VERSION ""

NS_ :

BS_:

BU_: EBOOST_HS CGM_HS BSM_HS HCP_B_HS AVM_HS PFAF_HS LVMPC_HS DCDC_HS TRCM_HS AMP_HS VICM2_HS FICM_HS ARS_HS MCP_B_HS MCP_A_HS ICCM_OBD_HS SAS_HS ACCM_HS VLBS_HS EBCM_OBD_HS HCP_T_HS EDI_HS HPCC_HS VITM_OBD_HS VICM_HS HCP_HS APPS_HS ICCM_HS EOCM_F_HS GPCM_HS VCM_HS HMIM_HS VES_HS Dummy_HS MCP_C_HS ONSTAR_HS EPS_HS TestTool_HS MCP_HS BCP_HS ALC_HS AHL_AFL_HS SADS_HS EPB_HS FCM_HS TCCM_HS RDCM_HS PTO_HS EBCM_HS ACC_HS BCM_HS TCM_HS ECM_HS

BO_ 1373 UUDT_Resp_From_ARS_HS: 8 ARS_HS
 SG_ DgnInf_HS55D : 7|64@0+ (1,0) [0|1.84467440737096E+019] ""  CGM_HS,ONSTAR_HS,TestTool_HS

BO_ 1372 UUDT_Resp_From_ACCM_HS: 8 ACCM_HS
 SG_ DgnInf_HS55C : 7|64@0+ (1,0) [0|1.84467440737096E+019] ""  CGM_HS,ONSTAR_HS,TestTool_HS

BO_ 1371 UUDT_Resp_From_ACC_HS: 8 ACC_HS
 SG_ DgnInf_HS55B : 7|64@0+ (1,0) [0|1.84467440737096E+019] ""  CGM_HS,ONSTAR_HS,TestTool_HS

BO_ 1370 UUDT_Resp_From_Free_5A_HS: 8 Dummy_HS
 SG_ DgnInf_HS55A : 7|64@0+ (1,0) [0|1.84467440737096E+019] ""  CGM_HS,ONSTAR_HS,TestTool_HS

BO_ 1368 UUDT_Resp_From_MCP_B_HS: 8 MCP_B_HS
 SG_ DgnInf_HS558 : 7|64@0+ (1,0) [0|1.84467440737096E+019] ""  CGM_HS,ONSTAR_HS,TestTool_HS

BO_ 1367 UUDT_Resp_From_MCP_HS: 8 MCP_HS
 SG_ DgnInf_HS557 : 7|64@0+ (1,0) [0|1.84467440737096E+019] ""  CGM_HS,ONSTAR_HS,TestTool_HS

BO_ 1366 UUDT_Resp_From_TCCM_HS: 8 TCCM_HS
 SG_ DgnInf_HS556 : 7|64@0+ (1,0) [0|1.84467440737096E+019] ""  CGM_HS,ONSTAR_HS,TestTool_HS

BO_ 1362 UUDT_Resp_From_HMIM_HS: 8 HMIM_HS
 SG_ DgnInf_HS552 : 7|64@0+ (1,0) [0|1.84467440737096E+019] ""  ONSTAR_HS,TestTool_HS

BO_ 1628 USDT_Resp_From_ACCM_HS: 8 ACCM_HS
 SG_ DgnInf : 7|64@0+ (1,0) [0|1.84467440737096E+019] ""  CGM_HS,ONSTAR_HS,TestTool_HS

BO_ 1627 USDT_Resp_From_ACC_HS: 8 ACC_HS
 SG_ DgnInf : 7|64@0+ (1,0) [0|1.84467440737096E+019] ""  CGM_HS,ONSTAR_HS,TestTool_HS

BO_ 1626 USDT_Resp_From_Free_5A_HS: 8 Dummy_HS
 SG_ DgnInf : 7|64@0+ (1,0) [0|1.84467440737096E+019] ""  CGM_HS,ONSTAR_HS,TestTool_HS

BO_ 1624 USDT_Resp_From_MCP_B_HS: 8 MCP_B_HS
 SG_ DgnInf : 7|64@0+ (1,0) [0|1.84467440737096E+019] ""  CGM_HS,ONSTAR_HS,TestTool_HS

BO_ 1623 USDT_Resp_From_MCP_HS: 8 MCP_HS
 SG_ DgnInf : 7|64@0+ (1,0) [0|1.84467440737096E+019] ""  CGM_HS,ONSTAR_HS,TestTool_HS

BO_ 1622 USDT_Resp_From_TCCM_HS: 8 TCCM_HS
 SG_ DgnInf : 7|64@0+ (1,0) [0|1.84467440737096E+019] ""  CGM_HS,ONSTAR_HS,TestTool_HS

BO_ 1619 USDT_Resp_From_AMP_HS: 8 AMP_HS
 SG_ DgnInf : 7|64@0+ (1,0) [0|1.84467440737096E+019] ""  ONSTAR_HS,TestTool_HS

BO_ 1618 USDT_Resp_From_HMIM_HS: 8 HMIM_HS
 SG_ DgnInf : 7|64@0+ (1,0) [0|1.84467440737096E+019] ""  ONSTAR_HS,TestTool_HS

BO_ 1617 USDT_Resp_From_Free_51_HS: 8 Dummy_HS
 SG_ DgnInf : 7|64@0+ (1,0) [0|1.84467440737096E+019] ""  CGM_HS,ONSTAR_HS,TestTool_HS

BO_ 600 USDT_Req_to_MCP_B_HS: 8 TestTool_HS
 SG_ DgnInf : 7|64@0+ (1,0) [0|1.84467440737096E+019] ""  MCP_B_HS

BO_ 599 USDT_Req_to_MCP_HS: 8 TestTool_HS
 SG_ DgnInf : 7|64@0+ (1,0) [0|1.84467440737096E+019] ""  MCP_A_HS,MCP_HS

BO_ 598 USDT_Req_to_TCCM_HS: 8 TestTool_HS
 SG_ DgnInf : 7|64@0+ (1,0) [0|1.84467440737096E+019] ""  TCCM_HS

BO_ 595 USDT_Req_to_AMP_HS: 8 TestTool_HS
 SG_ DgnInf : 7|64@0+ (1,0) [0|1.84467440737096E+019] ""  CGM_HS,AMP_HS

BO_ 594 USDT_Req_to_HMIM_HS: 8 TestTool_HS
 SG_ DgnInf : 7|64@0+ (1,0) [0|1.84467440737096E+019] ""  CGM_HS,HMIM_HS

BO_ 593 USDT_Req_to_Free_51_HS: 8 TestTool_HS
 SG_ DgnInf : 7|64@0+ (1,0) [0|1.84467440737096E+019] ""  Dummy_HS

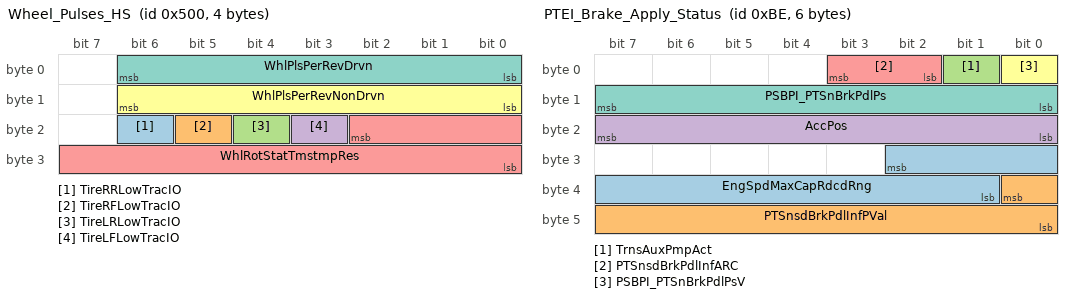
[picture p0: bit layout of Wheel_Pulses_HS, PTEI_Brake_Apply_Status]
BO_ 1280 Wheel_Pulses_HS: 4 EBCM_HS
 SG_ TireRRLowTracIO : 22|1@0+ (1,0) [0|1] ""  CGM_HS,BCM_HS
 SG_ TireRFLowTracIO : 21|1@0+ (1,0) [0|1] ""  CGM_HS,BCM_HS
 SG_ TireLRLowTracIO : 20|1@0+ (1,0) [0|1] ""  CGM_HS,BCM_HS
 SG_ TireLFLowTracIO : 19|1@0+ (1,0) [0|1] ""  CGM_HS,BCM_HS
 SG_ WhlRotStatTmstmpRes : 18|11@0+ (0.002,0) [0|4.094] "uSec"  CGM_HS,RDCM_HS,EPB_HS,HMIM_HS,TCCM_HS,BCM_HS,VES_HS,EPS_HS,EOCM_F_HS,ICCM_OBD_HS,ICCM_HS
 SG_ WhlPlsPerRevNonDrvn : 14|7@0+ (1,0) [0|127] ""  CGM_HS,ICCM_OBD_HS,ICCM_HS,HMIM_HS,TCCM_HS,EOCM_F_HS,VES_HS,EPS_HS,RDCM_HS,EPB_HS,ACC_HS,BCM_HS,SADS_HS,ONSTAR_HS
 SG_ WhlPlsPerRevDrvn : 6|7@0+ (1,0) [0|127] ""  CGM_HS,ICCM_OBD_HS,ICCM_HS,HMIM_HS,TCCM_HS,EOCM_F_HS,VES_HS,EPS_HS,RDCM_HS,ONSTAR_HS,ACC_HS,BCM_HS,EPB_HS,SADS_HS

BO_ 190 PTEI_Brake_Apply_Status: 6 ECM_HS
 SG_ EngSpdMaxCapRdcdRng : 26|10@0+ (8,0) [0|8184] "rpm"  TCM_HS
 SG_ PTSnsdBrkPdlInfPVal : 32|9@0+ (1,0) [0|511] ""  EBCM_OBD_HS,EBCM_HS,EBOOST_HS,ICCM_OBD_HS,ICCM_HS
 SG_ TrnsAuxPmpAct : 1|1@0+ (1,0) [0|1] ""  TCM_HS
 SG_ AccPos : 23|8@0+ (0.392157,0) [0|100.000035] "%"  BCP_HS,FICM_HS,TCM_HS,TCCM_HS
 SG_ PTSnsdBrkPdlInfARC : 3|2@0+ (1,0) [0|3] ""  EBCM_OBD_HS,EBCM_HS,EBOOST_HS,ICCM_OBD_HS,ICCM_HS
 SG_ PSBPI_PTSnBrkPdlPsV : 0|1@0+ (1,0) [0|1] ""  EBCM_OBD_HS,EBCM_HS,EBOOST_HS,ICCM_OBD_HS,ICCM_HS,TCM_HS
 SG_ PSBPI_PTSnBrkPdlPs : 15|8@0+ (0.392157,0) [0|100.000035] "%"  EBCM_OBD_HS,EBCM_HS,EBOOST_HS,ICCM_OBD_HS,ICCM_HS,TCM_HS

BO_ 1361 UUDT_Resp_From_Free_51_HS: 8 Dummy_HS
 SG_ DgnInf_HS551 : 7|64@0+ (1,0) [0|1.84467440737096E+019] ""  CGM_HS,ONSTAR_HS,TestTool_HS

BO_ 1345 UUDT_Resp_From_BCM_HS: 8 BCM_HS
 SG_ DgnInf_HS541 : 7|64@0+ (1,0) [0|1.84467440737096E+019] ""  CGM_HS,ONSTAR_HS,TestTool_HS

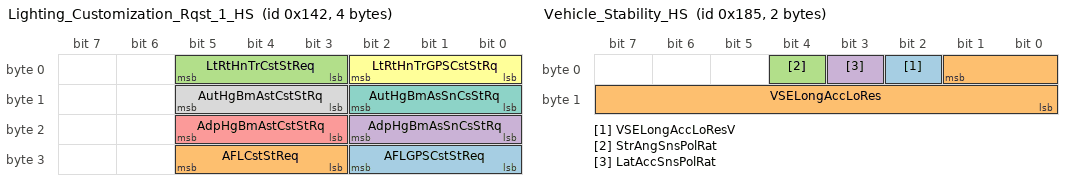
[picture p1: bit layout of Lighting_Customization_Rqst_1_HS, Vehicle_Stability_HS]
BO_ 322 Lighting_Customization_Rqst_1_HS: 4 BCM_HS
 SG_ AFLGPSCstStReq : 26|3@0+ (1,0) [0|7] ""  AHL_AFL_HS
 SG_ AFLCstStReq : 29|3@0+ (1,0) [0|7] ""  AHL_AFL_HS
 SG_ LtRtHnTrCstStReq : 5|3@0+ (1,0) [0|7] ""  AHL_AFL_HS
 SG_ AdpHgBmAsSnCsStRq : 18|3@0+ (1,0) [0|7] ""  AHL_AFL_HS
 SG_ AdpHgBmAstCstStRq : 21|3@0+ (1,0) [0|7] ""  AHL_AFL_HS
 SG_ LtRtHnTrGPSCstStRq : 2|3@0+ (1,0) [0|7] ""  AHL_AFL_HS
 SG_ AutHgBmAsSnCsStRq : 10|3@0+ (1,0) [0|7] ""  AHL_AFL_HS
 SG_ AutHgBmAstCstStRq : 13|3@0+ (1,0) [0|7] ""  AHL_AFL_HS

BO_ 1608 USDT_Resp_From_Free_48_HS: 8 Dummy_HS
 SG_ DgnInf : 7|64@0+ (1,0) [0|1.84467440737096E+019] ""  CGM_HS,ONSTAR_HS,TestTool_HS

BO_ 534 Damper_Information_HS: 2 SADS_HS
 SG_ DmpSysVehTopSpdLim : 15|8@0+ (2,0) [0|510] "km / h"  CGM_HS,BCM_HS
 SG_ SrvSuspSysIO : 0|1@0+ (1,0) [0|1] ""  CGM_HS,EDI_HS,ONSTAR_HS,BCM_HS

BO_ 309 Body_Information_2_HS: 8 BCM_HS
 SG_ StBltTgtCSRq : 23|3@0+ (1,0) [0|7] ""  CGM_HS,EBCM_OBD_HS,EBCM_HS
 SG_ ColPrSysCustReq : 15|3@0+ (1,0) [0|7] ""  FCM_HS,CGM_HS,ACC_HS,EOCM_F_HS
 SG_ SecV : 62|1@0+ (1,0) [0|1] ""  CGM_HS,ACC_HS
 SG_ Sec : 61|6@0+ (1,0) [0|63] "s"  CGM_HS,ACC_HS
 SG_ CldrYr_154 : 55|8@0+ (1,2000) [2000|2255] "year"  CGM_HS,ACC_HS
 SG_ CldrYr : 47|8@0+ (1,2000) [2000|2255] "year"  CGM_HS,EBCM_OBD_HS,EBCM_HS,ACC_HS
 SG_ CldrMth_154 : 39|4@0+ (1,0) [0|15] ""  CGM_HS,ACC_HS
 SG_ CldrMth : 35|4@0+ (1,0) [0|15] ""  EBCM_OBD_HS,EBCM_HS,CGM_HS,ACC_HS
 SG_ CldrDay_154 : 30|5@0+ (1,0) [0|31] "days"  CGM_HS,ACC_HS
 SG_ CldrDay : 20|5@0+ (1,0) [0|31] "days"  EBCM_OBD_HS,EBCM_HS,CGM_HS,ACC_HS
 SG_ AutoHiBmVDA : 25|1@0+ (1,0) [0|1] ""  CGM_HS,AHL_AFL_HS
 SG_ CtLghtDet : 24|1@0+ (1,0) [0|1] ""  CGM_HS,AHL_AFL_HS
 SG_ RrClosVDA : 11|1@0+ (1,0) [0|1] ""  CGM_HS,ICCM_OBD_HS,ICCM_HS,ALC_HS,SADS_HS
 SG_ TCSysDisSwAtv : 4|1@0+ (1,0) [0|1] ""  CGM_HS,EBCM_OBD_HS,EBCM_HS
 SG_ VehMovState : 2|3@0+ (1,0) [0|7] ""  CGM_HS,HMIM_HS,EBCM_OBD_HS,EBCM_HS,RDCM_HS,FCM_HS,SADS_HS,AHL_AFL_HS
 SG_ TCSysDisSwAtvV : 3|1@0+ (1,0) [0|1] ""  CGM_HS,EBCM_OBD_HS,EBCM_HS
 SG_ HillDesCtrlMdSwActV : 10|1@0+ (1,0) [0|1] ""  CGM_HS,EBCM_OBD_HS,EBCM_HS
 SG_ WSWshSwAtv : 5|1@0+ (1,0) [0|1] ""  CGM_HS,EOCM_F_HS,FCM_HS,ACC_HS
 SG_ HillDesCtrlMdSwAct : 9|1@0+ (1,0) [0|1] ""  CGM_HS,EBCM_OBD_HS,EBCM_HS
 SG_ RrClosAjarSwAct : 12|1@0+ (1,0) [0|1] ""  CGM_HS,ICCM_OBD_HS,ICCM_HS,ALC_HS,SADS_HS
 SG_ WSWprAct : 6|1@0+ (1,0) [0|1] ""  CGM_HS,FCM_HS,EOCM_F_HS,EBCM_OBD_HS,EBCM_HS,ACC_HS,AHL_AFL_HS

BO_ 389 Vehicle_Stability_HS: 2 EBCM_HS
 SG_ VSELongAccLoResV : 2|1@0+ (1,0) [0|1] ""  CGM_HS,EDI_HS,FCM_HS,TCM_HS,ICCM_OBD_HS,ICCM_HS,ALC_HS,SADS_HS,VES_HS,EPB_HS,RDCM_HS,BCM_HS,ACC_HS
 SG_ VSELongAccLoRes : 1|10@0- (0.03,0) [-15.36|15.33] "m/s^2"  CGM_HS,EDI_HS,FCM_HS,TCM_HS,ICCM_OBD_HS,ICCM_HS,ALC_HS,SADS_HS,VES_HS,EPB_HS,RDCM_HS,BCM_HS,ACC_HS
 SG_ StrAngSnsPolRat : 4|1@0+ (1,0) [0|1] ""  CGM_HS,EPS_HS
 SG_ LatAccSnsPolRat : 3|1@0+ (1,0) [0|1] ""  CGM_HS,EPS_HS

BO_ 1922 DTC_Triggered_782: 7 Dummy_HS
 SG_ DTCI_WrnIndRqdSt_782 : 47|1@0+ (1,0) [0|1] ""  HMIM_HS,ONSTAR_HS
 SG_ DTCIUnused7_782 : 1|1@0+ (1,0) [0|1] ""  HMIM_HS,ONSTAR_HS
 SG_ DTCIUnused6_782 : 2|1@0+ (1,0) [0|1] ""  HMIM_HS,ONSTAR_HS
 SG_ DTCIUnused5_782 : 3|1@0+ (1,0) [0|1] ""  HMIM_HS,ONSTAR_HS
 SG_ DTCIUnused4_782 : 4|1@0+ (1,0) [0|1] ""  HMIM_HS,ONSTAR_HS
 SG_ DTCIUnused3_782 : 5|1@0+ (1,0) [0|1] ""  HMIM_HS,ONSTAR_HS
 SG_ DTCIUnused2_782 : 6|1@0+ (1,0) [0|1] ""  HMIM_HS,ONSTAR_HS
 SG_ DTCIUnused1_782 : 7|1@0+ (1,0) [0|1] ""  HMIM_HS,ONSTAR_HS
 SG_ DTCI_TstNPsdPwrUpSt_782 : 45|1@0+ (1,0) [0|1] ""  HMIM_HS,ONSTAR_HS
 SG_ DTCI_TstNPsdCdClrdSt_782 : 42|1@0+ (1,0) [0|1] ""  HMIM_HS,ONSTAR_HS
 SG_ DTCI_TstFldPwrUpSt_782 : 46|1@0+ (1,0) [0|1] ""  HMIM_HS,ONSTAR_HS
 SG_ DTCI_TstFldCdClrdStat_782 : 43|1@0+ (1,0) [0|1] ""  HMIM_HS,ONSTAR_HS
 SG_ DTCI_HistStat_782 : 44|1@0+ (1,0) [0|1] ""  HMIM_HS,ONSTAR_HS
 SG_ DTCI_DTCTriggered_782 : 0|1@0+ (1,0) [0|1] ""  HMIM_HS,ONSTAR_HS
 SG_ DTCI_DTCSource_782 : 15|8@0+ (1,0) [0|255] ""  HMIM_HS,ONSTAR_HS
 SG_ DTCI_DTCNumber_782 : 23|16@0+ (1,0) [0|65535] ""  HMIM_HS,ONSTAR_HS
 SG_ DTCI_DTCFaultType_782 : 55|8@0+ (1,0) [0|255] ""  HMIM_HS,ONSTAR_HS
 SG_ DTCI_DTCFailType_782 : 39|8@0+ (1,0) [0|255] ""  HMIM_HS,ONSTAR_HS
 SG_ DTCI_CurrentStatus_782 : 41|1@0+ (1,0) [0|1] ""  HMIM_HS,ONSTAR_HS
 SG_ DTCI_CodeSupported_782 : 40|1@0+ (1,0) [0|1] ""  HMIM_HS,ONSTAR_HS

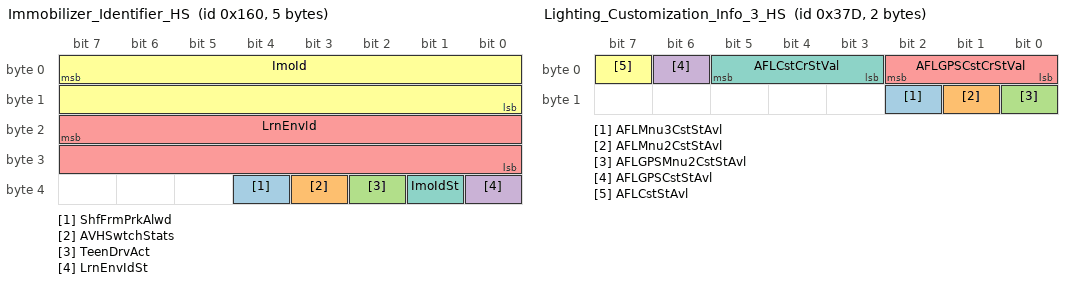
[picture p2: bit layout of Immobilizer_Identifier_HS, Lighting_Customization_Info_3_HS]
BO_ 352 Immobilizer_Identifier_HS: 5 BCM_HS
 SG_ ShfFrmPrkAlwd : 36|1@0+ (1,0) [0|1] ""  ICCM_HS
 SG_ AVHSwtchStats : 35|1@0+ (1,0) [0|1] ""  EBCM_OBD_HS,EBCM_HS
 SG_ TeenDrvAct : 34|1@0+ (1,0) [0|1] ""  CGM_HS,ALC_HS,EBCM_OBD_HS,EBCM_HS,AHL_AFL_HS,ACC_HS
 SG_ LrnEnvIdSt : 32|1@0+ (1,0) [0|1] ""  CGM_HS,VLBS_HS,ONSTAR_HS,EBCM_OBD_HS,EBCM_HS
 SG_ LrnEnvId : 23|16@0+ (1,0) [0|65535] ""  CGM_HS,VLBS_HS,ONSTAR_HS,EBCM_OBD_HS,EBCM_HS
 SG_ ImoId : 7|16@0+ (1,0) [0|65535] ""  CGM_HS,VLBS_HS,ONSTAR_HS,EBCM_OBD_HS,EBCM_HS
 SG_ ImoIdSt : 33|1@0+ (1,0) [0|1] ""  CGM_HS,VLBS_HS,ONSTAR_HS,EBCM_OBD_HS,EBCM_HS

BO_ 562 Driving_Mode_Control_HS: 8 EBCM_HS
 SG_ SndPerfMdCsStAvl : 63|1@0+ (1,0) [0|1] ""  CGM_HS,BCM_HS
 SG_ SndPerfMdCsCrStVal : 62|3@0+ (1,0) [0|7] ""  CGM_HS,BCM_HS
 SG_ DispPerfMdCsStAvl : 59|1@0+ (1,0) [0|1] ""  CGM_HS,BCM_HS
 SG_ DispPerfMdCsCrStVal : 58|3@0+ (1,0) [0|7] ""  CGM_HS,BCM_HS
 SG_ DrvlneMntsPerfMdRq : 50|3@0+ (1,0) [0|7] ""  CGM_HS,Dummy_HS,ICCM_OBD_HS,ICCM_HS
 SG_ RideCntrlPerfMdRq : 18|3@0+ (1,0) [0|7] ""  CGM_HS,EDI_HS,SADS_HS
 SG_ StgSysPerfMdRq : 29|3@0+ (1,0) [0|7] ""  EOCM_F_HS,FCM_HS,CGM_HS,EDI_HS,VES_HS,EPS_HS
 SG_ DiffPerfMdRq : 26|3@0+ (1,0) [0|7] ""  CGM_HS,ICCM_OBD_HS,ICCM_HS
 SG_ SndEnhcmtPerfMdRq : 13|3@0+ (1,0) [0|7] ""  CGM_HS,BCM_HS,AMP_HS
 SG_ DsplyPerfMdRq : 10|3@0+ (1,0) [0|7] ""  CGM_HS,EDI_HS,BCM_HS
 SG_ ExhstPerfMdRq : 5|3@0+ (1,0) [0|7] ""  CGM_HS,ICCM_OBD_HS,ICCM_HS
 SG_ HillDscntCntlSysStat : 55|3@0+ (1,0) [0|7] ""  CGM_HS,BCM_HS
 SG_ SusCustStngAvlbl : 23|1@0+ (1,0) [0|1] ""  CGM_HS,ONSTAR_HS,BCM_HS
 SG_ SusCustCurrStngVal : 45|3@0+ (1,0) [0|7] ""  CGM_HS,ONSTAR_HS,BCM_HS
 SG_ StrCustStngAvlbl : 7|1@0+ (1,0) [0|1] ""  CGM_HS,ONSTAR_HS,BCM_HS
 SG_ StrCustCurrStngVal : 42|3@0+ (1,0) [0|7] ""  CGM_HS,ONSTAR_HS,BCM_HS
 SG_ DrvlnCustStngAvlbl : 6|1@0+ (1,0) [0|1] ""  CGM_HS,ONSTAR_HS,BCM_HS
 SG_ DrvMdCntrlState : 39|8@0+ (1,0) [0|255] ""  CGM_HS,EOCM_F_HS,FCM_HS,VES_HS,EPS_HS,RDCM_HS,SADS_HS
 SG_ AWDPerfMdRq : 2|3@0+ (1,0) [0|7] ""  CGM_HS,RDCM_HS,TCCM_HS
 SG_ DrvlnCustCurrStngVal : 22|3@0+ (1,0) [0|7] ""  CGM_HS,ONSTAR_HS,BCM_HS

BO_ 893 Lighting_Customization_Info_3_HS: 2 AHL_AFL_HS
 SG_ AFLMnu3CstStAvl : 10|1@0+ (1,0) [0|1] ""  BCM_HS
 SG_ AFLMnu2CstStAvl : 9|1@0+ (1,0) [0|1] ""  BCM_HS
 SG_ AFLGPSMnu2CstStAvl : 8|1@0+ (1,0) [0|1] ""  BCM_HS
 SG_ AFLGPSCstStAvl : 6|1@0+ (1,0) [0|1] ""  BCM_HS
 SG_ AFLGPSCstCrStVal : 2|3@0+ (1,0) [0|7] ""  BCM_HS
 SG_ AFLCstStAvl : 7|1@0+ (1,0) [0|1] ""  BCM_HS
 SG_ AFLCstCrStVal : 5|3@0+ (1,0) [0|7] ""  BCM_HS

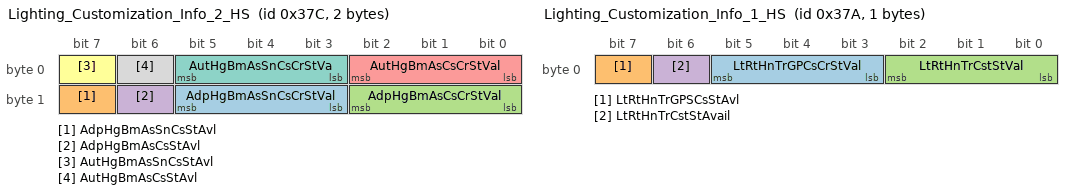
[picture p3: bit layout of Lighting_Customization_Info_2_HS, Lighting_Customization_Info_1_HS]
BO_ 892 Lighting_Customization_Info_2_HS: 2 AHL_AFL_HS
 SG_ AdpHgBmAsSnCsCrStVal : 13|3@0+ (1,0) [0|7] ""  BCM_HS
 SG_ AdpHgBmAsSnCsStAvl : 15|1@0+ (1,0) [0|1] ""  BCM_HS
 SG_ AdpHgBmAsCsCrStVal : 10|3@0+ (1,0) [0|7] ""  BCM_HS
 SG_ AdpHgBmAsCsStAvl : 14|1@0+ (1,0) [0|1] ""  BCM_HS
 SG_ AutHgBmAsCsCrStVal : 2|3@0+ (1,0) [0|7] ""  BCM_HS
 SG_ AutHgBmAsSnCsStAvl : 7|1@0+ (1,0) [0|1] ""  BCM_HS
 SG_ AutHgBmAsSnCsCrStVa : 5|3@0+ (1,0) [0|7] ""  BCM_HS
 SG_ AutHgBmAsCsStAvl : 6|1@0+ (1,0) [0|1] ""  BCM_HS

BO_ 386 Environment_Id_Resp_4_HS: 8 EBCM_HS
 SG_ AHAct : 31|1@0+ (1,0) [0|1] ""  BCM_HS
 SG_ AHEnbld : 30|1@0+ (1,0) [0|1] ""  BCM_HS
 SG_ ShfToPrkBfExtngIO : 29|1@0+ (1,0) [0|1] ""  BCM_HS
 SG_ AHServcIO : 28|1@0+ (1,0) [0|1] ""  BCM_HS
 SG_ AHAppBrkPedlIO : 27|1@0+ (1,0) [0|1] ""  BCM_HS
 SG_ AHDisbldStbltIO : 26|1@0+ (1,0) [0|1] ""  BCM_HS
 SG_ AHDisbldDrOpnIO : 25|1@0+ (1,0) [0|1] ""  BCM_HS
 SG_ PMVSS_Disps : 58|3@0+ (1,0) [0|7] ""  BCM_HS
 SG_ PMVSS_Exhst : 61|3@0+ (1,0) [0|7] ""  BCM_HS
 SG_ PMVSS_PsngrSeat : 48|3@0+ (1,0) [0|7] ""  BCM_HS
 SG_ PMVSS_DrvrSeat : 51|3@0+ (1,0) [0|7] ""  BCM_HS
 SG_ PMVSS_AdptCrsCnt : 54|3@0+ (1,0) [0|7] ""  BCM_HS
 SG_ PMVSS_Drvln : 41|3@0+ (1,0) [0|7] ""  BCM_HS
 SG_ PMVSS_Susp : 44|3@0+ (1,0) [0|7] ""  BCM_HS
 SG_ PMVSS_Strng : 47|3@0+ (1,0) [0|7] ""  BCM_HS
 SG_ PMVSS_Trans : 34|3@0+ (1,0) [0|7] ""  BCM_HS
 SG_ PMVSS_Eng : 37|3@0+ (1,0) [0|7] ""  BCM_HS
 SG_ PMVSS_Snd : 24|3@0+ (1,0) [0|7] ""  BCM_HS
 SG_ AdptCruzCtrlStg : 20|3@0+ (1,0) [0|7] ""  EOCM_F_HS,ACC_HS
 SG_ EnvIdRsp4 : 7|16@0+ (1,0) [0|65535] ""  BCM_HS
 SG_ EnvIdRspSt4 : 17|2@0+ (1,0) [0|3] ""  BCM_HS

BO_ 597 USDT_Req_to_TRCM_HS: 8 TestTool_HS
 SG_ DgnInf : 7|64@0+ (1,0) [0|1.84467440737096E+019] ""  TRCM_HS

BO_ 1621 USDT_Resp_From_TRCM_HS: 8 TRCM_HS
 SG_ DgnInf : 7|64@0+ (1,0) [0|1.84467440737096E+019] ""  CGM_HS,ONSTAR_HS,TestTool_HS

BO_ 532 Brake_Pedal_Driver_Status_HS: 6 EBCM_HS
 SG_ RedntVSEActARC : 38|2@0+ (1,0) [0|3] ""  CGM_HS,EPS_HS,ICCM_OBD_HS,ICCM_HS
 SG_ RedntVSEAct : 39|1@0+ (1,0) [0|1] ""  CGM_HS,EPS_HS,ICCM_OBD_HS,ICCM_HS
 SG_ AutoBrkngActARC : 22|2@0+ (1,0) [0|3] ""  CGM_HS,ICCM_OBD_HS,ICCM_HS
 SG_ HilRlbkCtrlActIO : 19|1@0+ (1,0) [0|1] ""  CGM_HS,BCM_HS
 SG_ VehHldDrvrDsblActvFlg : 36|1@0+ (1,0) [0|1] ""  CGM_HS,EPB_HS
 SG_ ABSAutnmsBrkReqPVal : 41|2@0+ (1,0) [0|3] ""  CGM_HS,EPB_HS
 SG_ AutoBrkngAvlbl : 17|1@0+ (1,0) [0|1] ""  FCM_HS,CGM_HS,EPS_HS,EOCM_F_HS,EPB_HS
 SG_ ABSAutnmsBrkReqARC : 35|2@0+ (1,0) [0|3] ""  CGM_HS,EPB_HS
 SG_ ABSAutnmsBrkReq : 33|1@0+ (1,0) [0|1] ""  CGM_HS,EPB_HS
 SG_ ABSActvProtPVal : 43|2@0+ (1,0) [0|3] ""  CGM_HS,EPS_HS,EOCM_F_HS,ICCM_OBD_HS,ICCM_HS
 SG_ ABSActvProtARC : 45|2@0+ (1,0) [0|3] ""  CGM_HS,EPS_HS,EOCM_F_HS,ICCM_OBD_HS,ICCM_HS
 SG_ HlStrAssActIO : 20|1@0+ (1,0) [0|1] ""  CGM_HS,BCM_HS
 SG_ ABSActvProt : 46|1@0+ (1,0) [0|1] ""  CGM_HS,EPS_HS,EOCM_F_HS,ICCM_OBD_HS,ICCM_HS
 SG_ BrkSysAutBrkFld : 5|1@0+ (1,0) [0|1] ""  FCM_HS,CGM_HS,EPB_HS,BCM_HS,ACC_HS
 SG_ IntBrkAssPreFilReq : 4|1@0+ (1,0) [0|1] "N/A"  CGM_HS,BCM_HS
 SG_ BrkSysMalFuncIndOn : 3|1@0+ (1,0) [0|1] ""  CGM_HS,BCM_HS
 SG_ BrkPdDrvAPrsStaPVal : 16|9@0+ (1,0) [0|511] ""  CGM_HS,FCM_HS,ACC_HS,EOCM_F_HS,ICCM_OBD_HS,ICCM_HS,EPB_HS,SADS_HS
 SG_ BPDAPS_BkPDrvApPV : 8|1@0+ (1,0) [0|1] ""  CGM_HS,FCM_HS,EOCM_F_HS,ICCM_OBD_HS,ICCM_HS,BCM_HS,ACC_HS,SADS_HS,EPB_HS
 SG_ BPDAPS_BkPDrvApP : 0|8@0+ (75,0) [0|19125] "kPa"  CGM_HS,FCM_HS,EOCM_F_HS,ICCM_OBD_HS,ICCM_HS,BCM_HS,ACC_HS,SADS_HS,EPB_HS
 SG_ BrkPdDrvAppPrsAlRC : 2|2@0+ (1,0) [0|3] ""  CGM_HS,FCM_HS,ACC_HS,EOCM_F_HS,ICCM_OBD_HS,ICCM_HS,SADS_HS,EPB_HS
 SG_ BrkFldLvlLwV : 7|1@0+ (1,0) [0|1] ""  CGM_HS,BCM_HS
 SG_ AutoBrkngAct : 18|1@0+ (1,0) [0|1] ""  CGM_HS,ICCM_OBD_HS,ICCM_HS,EPB_HS,ACC_HS
 SG_ BrkFldLvlLw : 6|1@0+ (1,0) [0|1] ""  CGM_HS,BCM_HS

BO_ 890 Lighting_Customization_Info_1_HS: 1 AHL_AFL_HS
 SG_ LtRtHnTrGPCsCrStVal : 5|3@0+ (1,0) [0|7] ""  BCM_HS
 SG_ LtRtHnTrGPSCsStAvl : 7|1@0+ (1,0) [0|1] ""  BCM_HS
 SG_ LtRtHnTrCstStVal : 2|3@0+ (1,0) [0|7] ""  BCM_HS
 SG_ LtRtHnTrCstStAvail : 6|1@0+ (1,0) [0|1] ""  BCM_HS

BO_ 592 USDT_Req_to_AVM_HS: 8 TestTool_HS
 SG_ DgnInf : 7|64@0+ (1,0) [0|1.84467440737096E+019] ""  AVM_HS

BO_ 1365 UUDT_Resp_From_TRCM_HS: 8 TRCM_HS
 SG_ DgnInf_HS555 : 7|64@0+ (1,0) [0|1.84467440737096E+019] ""  CGM_HS,ONSTAR_HS,TestTool_HS

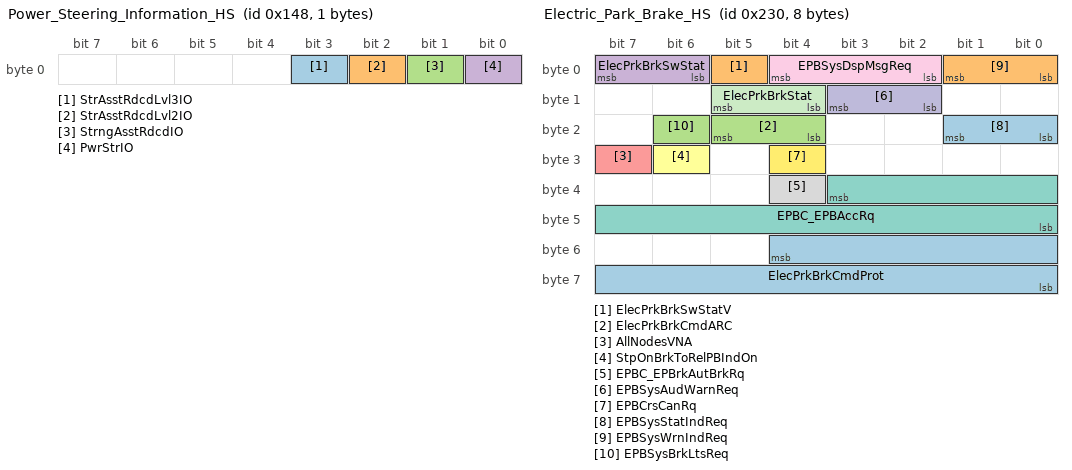
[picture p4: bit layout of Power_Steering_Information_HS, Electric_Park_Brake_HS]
BO_ 328 Power_Steering_Information_HS: 1 EPS_HS
 SG_ StrAsstRdcdLvl3IO : 3|1@0+ (1,0) [0|1] ""  BCM_HS,CGM_HS
 SG_ StrAsstRdcdLvl2IO : 2|1@0+ (1,0) [0|1] ""  BCM_HS,CGM_HS
 SG_ StrngAsstRdcdIO : 1|1@0+ (1,0) [0|1] ""  CGM_HS,BCM_HS
 SG_ PwrStrIO : 0|1@0+ (1,0) [0|1] ""  CGM_HS,BCM_HS,EPB_HS

BO_ 560 Electric_Park_Brake_HS: 8 EPB_HS
 SG_ ElecPrkBrkCmdProt : 52|13@0+ (1,0) [0|8191] ""  CGM_HS,EBCM_OBD_HS,EBCM_HS
 SG_ ElecPrkBrkSwStatV : 5|1@0+ (1,0) [0|1] ""  CGM_HS,EBCM_OBD_HS,EBCM_HS
 SG_ ElecPrkBrkCmdARC : 21|2@0+ (1,0) [0|3] ""  CGM_HS,EBCM_OBD_HS,EBCM_HS
 SG_ ElecPrkBrkSwStat : 7|2@0+ (1,0) [0|3] ""  CGM_HS,EBCM_OBD_HS,EBCM_HS
 SG_ AllNodesVNA : 31|1@0+ (1,0) [0|1] ""  CGM_HS,BCM_HS
 SG_ StpOnBrkToRelPBIndOn : 30|1@0+ (1,0) [0|1] ""  CGM_HS,BCM_HS
 SG_ EPBC_EPBAccRq : 35|12@0- (0.01,0) [-20.48|20.47] "m/s^2"  CGM_HS,EBCM_OBD_HS,EBCM_HS
 SG_ EPBC_EPBrkAutBrkRq : 36|1@0+ (1,0) [0|1] ""  CGM_HS,EBCM_OBD_HS,EBCM_HS
 SG_ EPBSysDspMsgReq : 4|3@0+ (1,0) [0|7] ""  CGM_HS,BCM_HS
 SG_ EPBSysAudWarnReq : 11|2@0+ (1,0) [0|3] ""  CGM_HS,BCM_HS
 SG_ ElecPrkBrkStat : 13|2@0+ (1,0) [0|3] ""  CGM_HS,ICCM_OBD_HS,ICCM_HS,ACC_HS,EOCM_F_HS,BCM_HS,EBCM_OBD_HS,EBCM_HS,RDCM_HS
 SG_ EPBCrsCanRq : 28|1@0+ (1,0) [0|1] ""  CGM_HS,ACC_HS,EOCM_F_HS,EBCM_OBD_HS,EBCM_HS,BCM_HS
 SG_ EPBSysStatIndReq : 17|2@0+ (1,0) [0|3] ""  CGM_HS,BCM_HS
 SG_ EPBSysWrnIndReq : 1|2@0+ (1,0) [0|3] ""  CGM_HS,BCM_HS
 SG_ EPBSysBrkLtsReq : 22|1@0+ (1,0) [0|1] ""  CGM_HS,BCM_HS

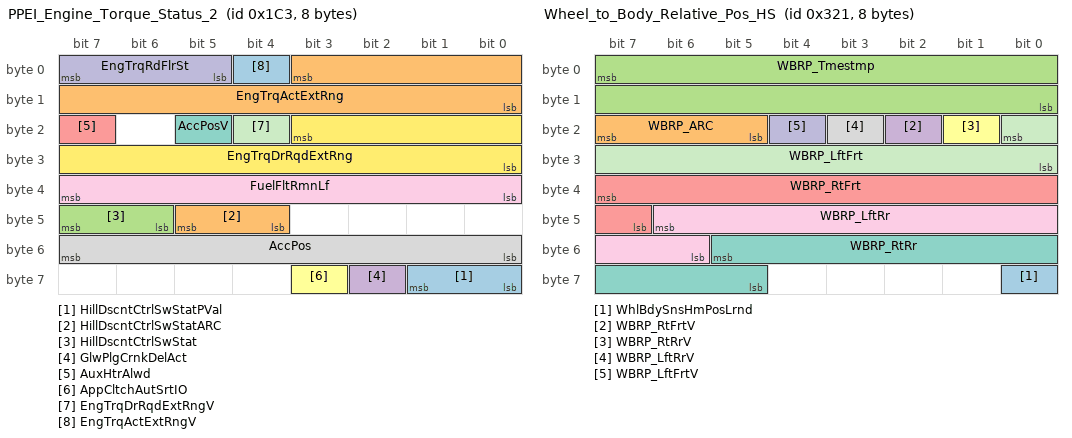
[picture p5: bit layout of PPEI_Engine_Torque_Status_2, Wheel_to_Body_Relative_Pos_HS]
BO_ 451 PPEI_Engine_Torque_Status_2: 8 ECM_HS
 SG_ HillDscntCtrlSwStatPVal : 57|2@0+ (1,0) [0|3] ""  CGM_HS,EBCM_OBD_HS,EBCM_HS
 SG_ HillDscntCtrlSwStatARC : 45|2@0+ (1,0) [0|3] ""  CGM_HS,EBCM_OBD_HS,EBCM_HS
 SG_ HillDscntCtrlSwStat : 47|2@0+ (1,0) [0|3] ""  CGM_HS,EBCM_OBD_HS,EBCM_HS
 SG_ GlwPlgCrnkDelAct : 58|1@0+ (1,0) [0|1] ""  CGM_HS,BCM_HS
 SG_ AuxHtrAlwd : 23|1@0+ (1,0) [0|1] ""  CGM_HS,BCM_HS
 SG_ AppCltchAutSrtIO : 59|1@0+ (1,0) [0|1] ""  CGM_HS,BCM_HS
 SG_ AccPosV : 21|1@0+ (1,0) [0|1] ""  RDCM_HS,CGM_HS,ICCM_OBD_HS,ICCM_HS,ACC_HS,EOCM_F_HS,TCCM_HS,EBCM_OBD_HS,EBCM_HS
 SG_ AccPos : 55|8@0+ (0.392157,0) [0|100.000035] "%"  RDCM_HS,CGM_HS,ICCM_OBD_HS,ICCM_HS,EOCM_F_HS,BSM_HS,VICM_HS,ACC_HS,TCCM_HS,EBCM_OBD_HS,EBCM_HS
 SG_ FuelFltRmnLf : 39|8@0+ (0.392157,0) [0|100.000035] "%"  CGM_HS,ONSTAR_HS,BCM_HS
 SG_ EngTrqRdFlrSt : 7|3@0+ (1,0) [0|7] ""  CGM_HS,EBCM_OBD_HS,EBCM_HS
 SG_ EngTrqDrRqdExtRngV : 20|1@0+ (1,0) [0|1] ""  CGM_HS,BCM_HS,ACC_HS,LVMPC_HS,RDCM_HS,EBCM_OBD_HS,EBCM_HS,SADS_HS
 SG_ EngTrqDrRqdExtRng : 19|12@0+ (0.5,-848) [-848|1199.5] "Nm"  CGM_HS,BCM_HS,LVMPC_HS,ACC_HS,RDCM_HS,EBCM_OBD_HS,EBCM_HS,SADS_HS
 SG_ EngTrqActExtRngV : 4|1@0+ (1,0) [0|1] ""  CGM_HS,AVM_HS,PTO_HS,ICCM_OBD_HS,ICCM_HS,AMP_HS,TCCM_HS,VES_HS,ACC_HS,EPS_HS,EPB_HS,BCM_HS,RDCM_HS,EBCM_OBD_HS,EBCM_HS,SADS_HS
 SG_ EngTrqActExtRng : 3|12@0+ (0.5,-848) [-848|1199.5] "Nm"  CGM_HS,AVM_HS,ICCM_OBD_HS,ICCM_HS,PTO_HS,AMP_HS,TCCM_HS,VES_HS,ACC_HS,EPS_HS,EPB_HS,BCM_HS,RDCM_HS,EBCM_OBD_HS,EBCM_HS,SADS_HS

BO_ 801 Wheel_to_Body_Relative_Pos_HS: 8 SADS_HS
 SG_ WhlBdySnsHmPosLrnd : 56|1@0+ (1,0) [0|1] ""  CGM_HS,EDI_HS,ICCM_OBD_HS,ICCM_HS,ALC_HS,SADS_HS,FCM_HS,AHL_AFL_HS,EBCM_OBD_HS,EBCM_HS
 SG_ WBRP_ARC : 23|3@0+ (1,0) [0|7] "counts"  CGM_HS,EDI_HS,ICCM_OBD_HS,ICCM_HS,ALC_HS,SADS_HS,FCM_HS,EBCM_OBD_HS,EBCM_HS,AHL_AFL_HS
 SG_ WBRP_Tmestmp : 7|16@0+ (1,0) [0|65535] "micro sec"  CGM_HS,EDI_HS,ICCM_OBD_HS,ICCM_HS,ALC_HS,SADS_HS,FCM_HS,EBCM_OBD_HS,EBCM_HS,AHL_AFL_HS
 SG_ WBRP_RtFrtV : 18|1@0+ (1,0) [0|1] ""  CGM_HS,EDI_HS,ICCM_OBD_HS,ICCM_HS,ALC_HS,SADS_HS,FCM_HS,EBCM_OBD_HS,EBCM_HS,AHL_AFL_HS
 SG_ WBRP_RtFrt : 39|9@0- (1,0) [-256|255] "mm"  CGM_HS,EDI_HS,ICCM_OBD_HS,ICCM_HS,ALC_HS,SADS_HS,FCM_HS,EBCM_OBD_HS,EBCM_HS,AHL_AFL_HS
 SG_ WBRP_RtRrV : 17|1@0+ (1,0) [0|1] ""  CGM_HS,EDI_HS,ICCM_OBD_HS,ICCM_HS,ALC_HS,SADS_HS,FCM_HS,EBCM_OBD_HS,EBCM_HS,AHL_AFL_HS
 SG_ WBRP_RtRr : 53|9@0- (1,0) [-256|255] "mm"  CGM_HS,EDI_HS,ICCM_OBD_HS,ICCM_HS,ALC_HS,SADS_HS,FCM_HS,EBCM_OBD_HS,EBCM_HS,AHL_AFL_HS
 SG_ WBRP_LftRrV : 19|1@0+ (1,0) [0|1] ""  CGM_HS,EDI_HS,ICCM_OBD_HS,ICCM_HS,ALC_HS,SADS_HS,FCM_HS,EBCM_OBD_HS,EBCM_HS,AHL_AFL_HS
 SG_ WBRP_LftRr : 46|9@0- (1,0) [-256|255] "mm"  CGM_HS,EDI_HS,ICCM_OBD_HS,ICCM_HS,ALC_HS,SADS_HS,FCM_HS,EBCM_OBD_HS,EBCM_HS,AHL_AFL_HS
 SG_ WBRP_LftFrtV : 20|1@0+ (1,0) [0|1] ""  CGM_HS,EDI_HS,ICCM_OBD_HS,ICCM_HS,ALC_HS,SADS_HS,FCM_HS,EBCM_OBD_HS,EBCM_HS,AHL_AFL_HS
 SG_ WBRP_LftFrt : 16|9@0- (1,0) [-256|255] "mm"  CGM_HS,EDI_HS,ICCM_OBD_HS,ICCM_HS,ALC_HS,SADS_HS,FCM_HS,EBCM_OBD_HS,EBCM_HS,AHL_AFL_HS

BO_ 320 Exterior_Lighting_HS: 3 BCM_HS
 SG_ Ky_IdDevPrgmAuthReq : 14|1@0+ (1,0) [0|1] ""  CGM_HS,EPS_HS
 SG_ ClmnLckStatV : 15|1@0+ (1,0) [0|1] ""  CGM_HS,EPS_HS
 SG_ ClmnLckStat : 21|2@0+ (1,0) [0|3] ""  CGM_HS,EPS_HS
 SG_ AutoBmSlctAllwd : 13|1@0+ (1,0) [0|1] ""  CGM_HS,AHL_AFL_HS
 SG_ BrkLtsAtv : 6|1@0+ (1,0) [0|1] ""  CGM_HS,AHL_AFL_HS,EOCM_F_HS,ACC_HS
 SG_ TrnSwAct : 19|2@0+ (1,0) [0|3] ""  CGM_HS,EBCM_OBD_HS,EBCM_HS,ECM_HS,EOCM_F_HS,AHL_AFL_HS
 SG_ RrFogLmpsAct : 8|1@0+ (1,0) [0|1] ""  CGM_HS,AHL_AFL_HS
 SG_ OtsdAmbtLtLvlStatV : 2|1@0+ (1,0) [0|1] ""  CGM_HS,FCM_HS,EOCM_F_HS,AHL_AFL_HS
 SG_ OtsdAmbtLtLvlStat : 17|2@0+ (1,0) [0|3] ""  CGM_HS,FCM_HS,EOCM_F_HS,AHL_AFL_HS
 SG_ MainLghtSw : 12|2@0+ (1,0) [0|3] "N/A"  CGM_HS,FCM_HS,AHL_AFL_HS
 SG_ LowBmAct : 1|1@0+ (1,0) [0|1] ""  CGM_HS,FCM_HS,EOCM_F_HS,AHL_AFL_HS
 SG_ HighBmAct : 7|1@0+ (1,0) [0|1] ""  CGM_HS,FCM_HS,EOCM_F_HS,AHL_AFL_HS
 SG_ HdlmpBmSelectStat : 10|2@0+ (1,0) [0|3] ""  CGM_HS,FCM_HS,AHL_AFL_HS
 SG_ FlToPsSwAtv : 5|1@0+ (1,0) [0|1] ""  CGM_HS,FCM_HS,AHL_AFL_HS
 SG_ AdvFrntLghtSysEnbld : 3|1@0+ (1,0) [0|1] ""  CGM_HS,AHL_AFL_HS
 SG_ FrFogLmpsAct : 0|1@0+ (1,0) [0|1] ""  CGM_HS,FCM_HS,AHL_AFL_HS
 SG_ AutLghtCtrl : 4|1@0+ (1,0) [0|1] "N/A"  CGM_HS,AHL_AFL_HS

BO_ 957 ETEI_Glow_Plug_Diagnostic_Status: 8 GPCM_HS
 SG_ RdctHtrCStat : 26|1@0+ (1,0) [0|1] ""  ECM_HS
 SG_ RdctHtrBStat : 27|1@0+ (1,0) [0|1] ""  ECM_HS
 SG_ RdctHtrAStat : 28|1@0+ (1,0) [0|1] ""  ECM_HS
 SG_ GPCMDS2_DTCStatus : 58|3@0+ (1,0) [0|7] ""  ECM_HS
 SG_ GPCMDS2_DTCIndex : 63|5@0+ (1,0) [0|31] ""  ECM_HS
 SG_ IntAirHtrPwrConsmp : 55|8@0+ (20,0) [0|5100] "W"  ECM_HS
 SG_ IntAirHtrPwrConsmpV : 29|1@0+ (1,0) [0|1] ""  ECM_HS
 SG_ DslGlwPlgMdOvTmOD : 25|1@0+ (1,0) [0|1] ""  ECM_HS
 SG_ IQAI_DataByte : 47|8@0+ (1,0) [0|255] ""  ECM_HS
 SG_ IQAI_DataSeqNmbr : 35|4@0+ (1,0) [0|15] ""  ECM_HS
 SG_ IQAI_InjIdInd : 38|3@0+ (1,0) [0|7] ""  ECM_HS
 SG_ IQAI_DataStat : 39|1@0+ (1,0) [0|1] ""  ECM_HS
 SG_ IntAirHtrTempSensVoltV : 30|1@0+ (1,0) [0|1] ""  ECM_HS
 SG_ IntAirHtrTempSensVolt : 23|8@0+ (0.0196078,0) [0|4.999989] "volts"  ECM_HS
 SG_ IntAirHtrSupVoltV : 31|1@0+ (1,0) [0|1] ""  ECM_HS
 SG_ IntAirHtrSupVolt : 15|8@0+ (0.1,0) [0|25.5] "volts"  ECM_HS
 SG_ GPCMDS_DTCStatus : 2|3@0+ (1,0) [0|7] ""  ECM_HS
 SG_ GPCMDS_DTCIndex : 7|5@0+ (1,0) [0|31] ""  ECM_HS

BO_ 1364 UUDT_Resp_From_EPB_HS: 8 EPB_HS
 SG_ DgnInf_HS554 : 7|64@0+ (1,0) [0|1.84467440737096E+019] ""  CGM_HS,ONSTAR_HS,TestTool_HS

BO_ 2041 PCU_Resp_From_SDM_HS: 8 BCM_HS
 SG_ PCUInfo_7F9 : 7|64@0+ (1,0) [0|1.84467440737096E+019] ""  TestTool_HS

BO_ 1904 DTC_Triggered_770: 7 ICCM_OBD_HS
 SG_ DTCI_WrnIndRqdSt_770 : 47|1@0+ (1,0) [0|1] ""  HMIM_HS,ONSTAR_HS
 SG_ DTCIUnused7_770 : 7|1@0+ (1,0) [0|1] ""  HMIM_HS,ONSTAR_HS
 SG_ DTCIUnused6_770 : 6|1@0+ (1,0) [0|1] ""  HMIM_HS,ONSTAR_HS
 SG_ DTCIUnused5_770 : 5|1@0+ (1,0) [0|1] ""  HMIM_HS,ONSTAR_HS
 SG_ DTCIUnused4_770 : 4|1@0+ (1,0) [0|1] ""  HMIM_HS,ONSTAR_HS
 SG_ DTCIUnused3_770 : 3|1@0+ (1,0) [0|1] ""  HMIM_HS,ONSTAR_HS
 SG_ DTCIUnused2_770 : 2|1@0+ (1,0) [0|1] ""  HMIM_HS,ONSTAR_HS
 SG_ DTCIUnused1_770 : 1|1@0+ (1,0) [0|1] ""  HMIM_HS,ONSTAR_HS
 SG_ DTCI_TstNPsdPwrUpSt_770 : 45|1@0+ (1,0) [0|1] ""  HMIM_HS,ONSTAR_HS
 SG_ DTCI_TstNPsdCdClrdSt_770 : 42|1@0+ (1,0) [0|1] ""  HMIM_HS,ONSTAR_HS
 SG_ DTCI_TstFldPwrUpSt_770 : 46|1@0+ (1,0) [0|1] ""  HMIM_HS,ONSTAR_HS
 SG_ DTCI_TstFldCdClrdStat_770 : 43|1@0+ (1,0) [0|1] ""  HMIM_HS,ONSTAR_HS
 SG_ DTCI_HistStat_770 : 44|1@0+ (1,0) [0|1] ""  HMIM_HS,ONSTAR_HS
 SG_ DTCI_DTCTriggered_770 : 0|1@0+ (1,0) [0|1] ""  HMIM_HS,ONSTAR_HS
 SG_ DTCI_DTCSource_770 : 15|8@0+ (1,0) [0|255] ""  HMIM_HS,ONSTAR_HS
 SG_ DTCI_DTCNumber_770 : 23|16@0+ (1,0) [0|65535] ""  HMIM_HS,ONSTAR_HS
 SG_ DTCI_DTCFaultType_770 : 55|8@0+ (1,0) [0|255] ""  HMIM_HS,ONSTAR_HS
 SG_ DTCI_DTCFailType_770 : 39|8@0+ (1,0) [0|255] ""  HMIM_HS,ONSTAR_HS
 SG_ DTCI_CurrentStatus_770 : 41|1@0+ (1,0) [0|1] ""  HMIM_HS,ONSTAR_HS
 SG_ DTCI_CodeSupported_770 : 40|1@0+ (1,0) [0|1] ""  HMIM_HS,ONSTAR_HS

BO_ 1908 DTC_Triggered_774: 7 DCDC_HS
 SG_ DTCI_DTCFaultType_774 : 55|8@0+ (1,0) [0|255] ""  HMIM_HS,ONSTAR_HS
 SG_ DTCI_CodeSupported_774 : 40|1@0+ (1,0) [0|1] ""  HMIM_HS,ONSTAR_HS
 SG_ DTCI_CurrentStatus_774 : 41|1@0+ (1,0) [0|1] ""  HMIM_HS,ONSTAR_HS
 SG_ DTCI_TstNPsdCdClrdSt_774 : 42|1@0+ (1,0) [0|1] ""  HMIM_HS,ONSTAR_HS
 SG_ DTCI_TstFldCdClrdStat_774 : 43|1@0+ (1,0) [0|1] ""  HMIM_HS,ONSTAR_HS
 SG_ DTCI_HistStat_774 : 44|1@0+ (1,0) [0|1] ""  HMIM_HS,ONSTAR_HS
 SG_ DTCI_TstNPsdPwrUpSt_774 : 45|1@0+ (1,0) [0|1] ""  HMIM_HS,ONSTAR_HS
 SG_ DTCI_TstFldPwrUpSt_774 : 46|1@0+ (1,0) [0|1] ""  HMIM_HS,ONSTAR_HS
 SG_ DTCI_WrnIndRqdSt_774 : 47|1@0+ (1,0) [0|1] ""  HMIM_HS,ONSTAR_HS
 SG_ DTCI_DTCFailType_774 : 39|8@0+ (1,0) [0|255] ""  HMIM_HS,ONSTAR_HS
 SG_ DTCI_DTCNumber_774 : 23|16@0+ (1,0) [0|65535] ""  HMIM_HS,ONSTAR_HS
 SG_ DTCI_DTCSource_774 : 15|8@0+ (1,0) [0|255] ""  HMIM_HS,ONSTAR_HS
 SG_ DTCI_DTCTriggered_774 : 0|1@0+ (1,0) [0|1] ""  HMIM_HS,ONSTAR_HS
 SG_ DTCIUnused7_774 : 1|1@0+ (1,0) [0|1] ""  HMIM_HS,ONSTAR_HS
 SG_ DTCIUnused6_774 : 2|1@0+ (1,0) [0|1] ""  HMIM_HS,ONSTAR_HS
 SG_ DTCIUnused5_774 : 3|1@0+ (1,0) [0|1] ""  HMIM_HS,ONSTAR_HS
 SG_ DTCIUnused4_774 : 4|1@0+ (1,0) [0|1] ""  HMIM_HS,ONSTAR_HS
 SG_ DTCIUnused3_774 : 5|1@0+ (1,0) [0|1] ""  HMIM_HS,ONSTAR_HS
 SG_ DTCIUnused2_774 : 6|1@0+ (1,0) [0|1] ""  HMIM_HS,ONSTAR_HS
 SG_ DTCIUnused1_774 : 7|1@0+ (1,0) [0|1] ""  HMIM_HS,ONSTAR_HS

BO_ 1909 DTC_Triggered_775: 7 MCP_HS
 SG_ DTCI_DTCFaultType_775 : 55|8@0+ (1,0) [0|255] ""  HMIM_HS,ONSTAR_HS
 SG_ DTCI_CodeSupported_775 : 40|1@0+ (1,0) [0|1] ""  HMIM_HS,ONSTAR_HS
 SG_ DTCI_CurrentStatus_775 : 41|1@0+ (1,0) [0|1] ""  HMIM_HS,ONSTAR_HS
 SG_ DTCI_TstNPsdCdClrdSt_775 : 42|1@0+ (1,0) [0|1] ""  HMIM_HS,ONSTAR_HS
 SG_ DTCI_TstFldCdClrdStat_775 : 43|1@0+ (1,0) [0|1] ""  HMIM_HS,ONSTAR_HS
 SG_ DTCI_HistStat_775 : 44|1@0+ (1,0) [0|1] ""  HMIM_HS,ONSTAR_HS
 SG_ DTCI_TstNPsdPwrUpSt_775 : 45|1@0+ (1,0) [0|1] ""  HMIM_HS,ONSTAR_HS
 SG_ DTCI_TstFldPwrUpSt_775 : 46|1@0+ (1,0) [0|1] ""  HMIM_HS,ONSTAR_HS
 SG_ DTCI_WrnIndRqdSt_775 : 47|1@0+ (1,0) [0|1] ""  HMIM_HS,ONSTAR_HS
 SG_ DTCI_DTCFailType_775 : 39|8@0+ (1,0) [0|255] ""  HMIM_HS,ONSTAR_HS
 SG_ DTCI_DTCNumber_775 : 23|16@0+ (1,0) [0|65535] ""  HMIM_HS,ONSTAR_HS
 SG_ DTCI_DTCSource_775 : 15|8@0+ (1,0) [0|255] ""  HMIM_HS,ONSTAR_HS
 SG_ DTCI_DTCTriggered_775 : 0|1@0+ (1,0) [0|1] ""  HMIM_HS,ONSTAR_HS
 SG_ DTCIUnused7_775 : 1|1@0+ (1,0) [0|1] ""  HMIM_HS,ONSTAR_HS
 SG_ DTCIUnused6_775 : 2|1@0+ (1,0) [0|1] ""  HMIM_HS,ONSTAR_HS
 SG_ DTCIUnused5_775 : 3|1@0+ (1,0) [0|1] ""  HMIM_HS,ONSTAR_HS
 SG_ DTCIUnused4_775 : 4|1@0+ (1,0) [0|1] ""  HMIM_HS,ONSTAR_HS
 SG_ DTCIUnused3_775 : 5|1@0+ (1,0) [0|1] ""  HMIM_HS,ONSTAR_HS
 SG_ DTCIUnused2_775 : 6|1@0+ (1,0) [0|1] ""  HMIM_HS,ONSTAR_HS
 SG_ DTCIUnused1_775 : 7|1@0+ (1,0) [0|1] ""  HMIM_HS,ONSTAR_HS

BO_TX_BU_ 1371 : CGM_HS,ACC_HS;
BO_TX_BU_ 1367 : MCP_A_HS,MCP_HS;
BO_TX_BU_ 1362 : CGM_HS,HMIM_HS;
BO_TX_BU_ 1627 : CGM_HS,ACC_HS;
BO_TX_BU_ 1623 : MCP_A_HS,MCP_HS;
BO_TX_BU_ 1619 : CGM_HS,AMP_HS;
BO_TX_BU_ 1618 : CGM_HS,HMIM_HS;
BO_TX_BU_ 600 : CGM_HS,ONSTAR_HS,TestTool_HS;
BO_TX_BU_ 599 : CGM_HS,ONSTAR_HS,TestTool_HS;
BO_TX_BU_ 598 : CGM_HS,ONSTAR_HS,TestTool_HS;
BO_TX_BU_ 595 : ONSTAR_HS,TestTool_HS;
BO_TX_BU_ 594 : ONSTAR_HS,TestTool_HS;
BO_TX_BU_ 593 : CGM_HS,ONSTAR_HS,TestTool_HS;
BO_TX_BU_ 1280 : EBCM_OBD_HS,EBCM_HS;
BO_TX_BU_ 389 : EBCM_OBD_HS,EBCM_HS;
BO_TX_BU_ 1922 : CGM_HS,PFAF_HS,Dummy_HS;
BO_TX_BU_ 562 : EBCM_OBD_HS,EBCM_HS;
BO_TX_BU_ 893 : CGM_HS,AHL_AFL_HS;
BO_TX_BU_ 386 : EBCM_OBD_HS,EBCM_HS;
BO_TX_BU_ 597 : CGM_HS,ONSTAR_HS,TestTool_HS;
BO_TX_BU_ 532 : EBCM_OBD_HS,EBCM_HS;
BO_TX_BU_ 592 : CGM_HS,ONSTAR_HS,TestTool_HS;
BO_TX_BU_ 328 : EBCM_OBD_HS,EBCM_HS,VES_HS,EPS_HS;
BO_TX_BU_ 560 : CGM_HS,EBCM_OBD_HS,EBCM_HS,EPB_HS;
BO_TX_BU_ 801 : ICCM_OBD_HS,ICCM_HS,ALC_HS,SADS_HS;
BO_TX_BU_ 1364 : CGM_HS,EPB_HS;
BO_TX_BU_ 1909 : MCP_A_HS,MCP_HS;
CM_ SG_ 1922 DTCI_DTCSource_782 "This shall be equal to the Diagnostic Address of the transmittting device.";
CM_ SG_ 1922 DTCI_DTCFaultType_782 "Based on Powertrain definition.  Not expected to be supported by all devices.";
CM_ SG_ 1922 DTCI_DTCFailType_782 "Assigned per GMW3110, Appendix E";
CM_ SG_ 532 BrkSysAutBrkFld "BrakeSystemAutomaticBrakingFailed";
CM_ SG_ 532 IntBrkAssPreFilReq "IntelligentBrakeAssistPreFillRequest";
CM_ SG_ 801 WBRP_RtFrt "Negative values indicate Compression, Positive values indicate Extension.";
CM_ SG_ 801 WBRP_RtRr "Negative values indicate Compression, Positive values indicate Extension.";
CM_ SG_ 801 WBRP_LftRr "Negative values indicate Compression, Positive values indicate Extension.";
CM_ SG_ 801 WBRP_LftFrt "Negative values indicate Compression, Positive values indicate Extension.";
CM_ SG_ 320 MainLghtSw "Operator selection for the main lighting switch";
CM_ SG_ 320 AutLghtCtrl "This signal represents if Automatic Lights Control feature is active/inactive";
CM_ SG_ 1904 DTCI_DTCSource_770 "This shall be equal to the Diagnostic Address of the transmittting device.";
CM_ SG_ 1904 DTCI_DTCFaultType_770 "Based on Powertrain definition.  Not expected to be supported by all devices.";
CM_ SG_ 1904 DTCI_DTCFailType_770 "Assigned per GMW3110, Appendix E";
CM_ SG_ 1908 DTCI_DTCFaultType_774 "Based on Powertrain definition.  Not expected to be supported by all devices.";
CM_ SG_ 1908 DTCI_DTCFailType_774 "Assigned per GMW3110, Appendix E";
CM_ SG_ 1908 DTCI_DTCSource_774 "This shall be equal to the Diagnostic Address of the transmittting device.";
CM_ SG_ 1909 DTCI_DTCFaultType_775 "Based on Powertrain definition.  Not expected to be supported by all devices.";
CM_ SG_ 1909 DTCI_DTCFailType_775 "Assigned per GMW3110, Appendix E";
CM_ SG_ 1909 DTCI_DTCSource_775 "This shall be equal to the Diagnostic Address of the transmittting device.";
BA_DEF_ SG_  "VNSigSLHS_VNReq" ENUM  "No","Yes";
BA_DEF_ SG_  "VNSigSLHSSharedDiagnostic" ENUM  "No","Yes";
BA_DEF_ SG_  "SignalType" STRING ;
BA_DEF_ SG_  "PacketOrder" INT 0 65535;
BA_DEF_ SG_  "SignalLongName" STRING ;
BA_DEF_ SG_  "GenSigStartValue" INT 0 65535;
BA_DEF_ SG_  "VNSigAllNodes" ENUM  "No","Yes";
BA_DEF_ SG_  "GenSigDeltaValue" INT 0 0;
BA_DEF_ SG_  "GenSigSendType" ENUM  "not used","not used","not used","not used","not used","not used","not used","NoSigSendType","not used","not used","OnAnyChange","OnChangeIfActive","OnDelta";
BA_DEF_ SG_  "GenSigSendOnInit" ENUM  "Not Initialized","Application","Handler";
BA_DEF_ BO_  "AppGenMsgCycleTime" INT 0 0;
BA_DEF_ BO_  "TpTxIndex" INT 0 99;
BA_DEF_ BO_  "GenMsgILSupport" ENUM  "No","Yes";
BA_DEF_ BO_  "TpApplType" STRING ;
BA_DEF_ BO_  "Prio" INT 0 7;
BA_DEF_ BO_  "MessageSubnet" ENUM  "LS","MS","HS","CE","PE","HV","FO","S1","HE","LE","HE2";
BA_DEF_ BO_  "DiagState" ENUM  "No","Yes";
BA_DEF_ BO_  "GenMsgStartDelayTime" INT 0 100000;
BA_DEF_ BO_  "GenMsgDelayTime" INT 0 100000;
BA_DEF_ BO_  "GenMsgCycleTime" INT 0 100000;
BA_DEF_ BO_  "GenMsgSendType" ENUM  "cyclicX","spontanX","cyclicIfActiveX","spontanWithDelay","cyclicAndSpontanX","cyclicAndSpontanWithDelay","spontanWithRepitition","cyclicIfActiveAndSpontanWD";
BA_DEF_ BO_  "DiagResponse" ENUM  "No","Yes";
BA_DEF_ BO_  "DiagRequest" ENUM  "No","Yes";
BA_DEF_ BO_  "NmMessage" ENUM  "No","Yes";
BA_DEF_REL_ BU_SG_REL_  "GenSigSuprvRespComment" STRING ;
BA_DEF_REL_ BU_SG_REL_  "GenSigVBitResp" ENUM  "No","Yes";
BA_DEF_REL_ BU_SG_REL_  "GenSigVBitRespComment" STRING ;
BA_DEF_REL_ BU_SG_REL_  "GenSigVDAFailComment" STRING ;
BA_DEF_REL_ BU_SG_REL_  "GenSigVDAFailResp" ENUM  "No","Yes";
BA_DEF_REL_ BU_SG_REL_  "GenSigRxStartValue" STRING ;
BA_DEF_REL_ BU_SG_REL_  "GenSigSuprvRespSubValue" INT 0 65535;
BA_DEF_REL_ BU_SG_REL_  "GenSigSuprvResp" ENUM  "None","Notify App","Substitute Default";
BA_DEF_REL_ BU_SG_REL_  "GenSigTimeoutMsg" HEX -2147483648 268435455;
BA_DEF_REL_ BU_SG_REL_  "GenSigTimeoutTime" INT 0 15000;
BA_DEF_DEF_  "VNSigSLHS_VNReq" "No";
BA_DEF_DEF_  "VNSigSLHSSharedDiagnostic" "No";
BA_DEF_DEF_  "SignalType" "";
BA_DEF_DEF_  "PacketOrder" 0;
BA_DEF_DEF_  "SignalLongName" "";
BA_DEF_DEF_  "GenSigStartValue" 0;
BA_DEF_DEF_  "VNSigAllNodes" "No";
BA_DEF_DEF_  "GenSigDeltaValue" 0;
BA_DEF_DEF_  "GenSigSendType" "NoSigSendType";
BA_DEF_DEF_  "GenSigSendOnInit" "Not Initialized";
BA_DEF_DEF_  "AppGenMsgCycleTime" 0;
BA_DEF_DEF_  "TpTxIndex" 0;
BA_DEF_DEF_  "GenMsgILSupport" "Yes";
BA_DEF_DEF_  "TpApplType" "";
BA_DEF_DEF_  "Prio" 4;
BA_DEF_DEF_  "MessageSubnet" "FO";
BA_DEF_DEF_  "DiagState" "No";
BA_DEF_DEF_  "GenMsgStartDelayTime" 0;
BA_DEF_DEF_  "GenMsgDelayTime" 0;
BA_DEF_DEF_  "GenMsgCycleTime" 0;
BA_DEF_DEF_  "GenMsgSendType" "spontanX";
BA_DEF_DEF_  "DiagResponse" "No";
BA_DEF_DEF_  "DiagRequest" "No";
BA_DEF_DEF_  "NmMessage" "No";
BA_DEF_DEF_REL_ "GenSigSuprvRespComment" "";
BA_DEF_DEF_REL_ "GenSigVBitResp" "No";
BA_DEF_DEF_REL_ "GenSigVBitRespComment" "";
BA_DEF_DEF_REL_ "GenSigVDAFailComment" "";
BA_DEF_DEF_REL_ "GenSigVDAFailResp" "No";
BA_DEF_DEF_REL_ "GenSigRxStartValue" "";
BA_DEF_DEF_REL_ "GenSigSuprvRespSubValue" 0;
BA_DEF_DEF_REL_ "GenSigSuprvResp" "None";
BA_DEF_DEF_REL_ "GenSigTimeoutMsg" 0;
BA_DEF_DEF_REL_ "GenSigTimeoutTime" 0;
BA_ "GenMsgILSupport" BO_ 1373 0;
BA_ "TpApplType" BO_ 1373 "DiagUUDTResponse";
BA_ "Prio" BO_ 1373 0;
BA_ "MessageSubnet" BO_ 1373 2;
BA_ "GenMsgILSupport" BO_ 1372 0;
BA_ "TpApplType" BO_ 1372 "DiagUUDTResponse";
BA_ "Prio" BO_ 1372 0;
BA_ "MessageSubnet" BO_ 1372 2;
BA_ "GenMsgILSupport" BO_ 1371 0;
BA_ "TpApplType" BO_ 1371 "DiagUUDTResponse";
BA_ "Prio" BO_ 1371 0;
BA_ "MessageSubnet" BO_ 1371 2;
BA_ "GenMsgILSupport" BO_ 1370 0;
BA_ "TpApplType" BO_ 1370 "DiagUUDTResponse";
BA_ "Prio" BO_ 1370 0;
BA_ "MessageSubnet" BO_ 1370 2;
BA_ "GenMsgILSupport" BO_ 1368 0;
BA_ "TpApplType" BO_ 1368 "DiagUUDTResponse";
BA_ "Prio" BO_ 1368 0;
BA_ "MessageSubnet" BO_ 1368 2;
BA_ "GenMsgILSupport" BO_ 1367 0;
BA_ "TpApplType" BO_ 1367 "DiagUUDTResponse";
BA_ "Prio" BO_ 1367 0;
BA_ "MessageSubnet" BO_ 1367 2;
BA_ "GenMsgILSupport" BO_ 1366 0;
BA_ "TpApplType" BO_ 1366 "DiagUUDTResponse";
BA_ "Prio" BO_ 1366 0;
BA_ "MessageSubnet" BO_ 1366 2;
BA_ "GenMsgILSupport" BO_ 1362 0;
BA_ "TpApplType" BO_ 1362 "DiagUUDTResponse";
BA_ "Prio" BO_ 1362 0;
BA_ "MessageSubnet" BO_ 1362 2;
BA_ "Prio" BO_ 1628 0;
BA_ "MessageSubnet" BO_ 1628 2;
BA_ "DiagResponse" BO_ 1628 1;
BA_ "Prio" BO_ 1627 0;
BA_ "MessageSubnet" BO_ 1627 2;
BA_ "DiagResponse" BO_ 1627 1;
BA_ "Prio" BO_ 1626 0;
BA_ "MessageSubnet" BO_ 1626 2;
BA_ "DiagResponse" BO_ 1626 1;
BA_ "Prio" BO_ 1624 0;
BA_ "MessageSubnet" BO_ 1624 2;
BA_ "DiagResponse" BO_ 1624 1;
BA_ "Prio" BO_ 1623 0;
BA_ "MessageSubnet" BO_ 1623 2;
BA_ "DiagResponse" BO_ 1623 1;
BA_ "Prio" BO_ 1622 0;
BA_ "MessageSubnet" BO_ 1622 2;
BA_ "DiagResponse" BO_ 1622 1;
BA_ "Prio" BO_ 1619 0;
BA_ "MessageSubnet" BO_ 1619 2;
BA_ "DiagResponse" BO_ 1619 1;
BA_ "Prio" BO_ 1618 0;
BA_ "MessageSubnet" BO_ 1618 2;
BA_ "DiagResponse" BO_ 1618 1;
BA_ "Prio" BO_ 1617 0;
BA_ "MessageSubnet" BO_ 1617 2;
BA_ "DiagResponse" BO_ 1617 1;
BA_ "Prio" BO_ 600 0;
BA_ "MessageSubnet" BO_ 600 2;
BA_ "DiagRequest" BO_ 600 1;
BA_ "Prio" BO_ 599 0;
BA_ "MessageSubnet" BO_ 599 2;
BA_ "DiagRequest" BO_ 599 1;
BA_ "Prio" BO_ 598 0;
BA_ "MessageSubnet" BO_ 598 2;
BA_ "DiagRequest" BO_ 598 1;
BA_ "Prio" BO_ 595 0;
BA_ "MessageSubnet" BO_ 595 2;
BA_ "DiagRequest" BO_ 595 1;
BA_ "Prio" BO_ 594 0;
BA_ "MessageSubnet" BO_ 594 2;
BA_ "DiagRequest" BO_ 594 1;
BA_ "Prio" BO_ 593 0;
BA_ "MessageSubnet" BO_ 593 2;
BA_ "DiagRequest" BO_ 593 1;
BA_ "Prio" BO_ 1280 0;
BA_ "MessageSubnet" BO_ 1280 2;
BA_ "GenMsgCycleTime" BO_ 1280 1000;
BA_ "GenMsgSendType" BO_ 1280 0;
BA_ "Prio" BO_ 190 0;
BA_ "MessageSubnet" BO_ 190 2;
BA_ "GenMsgCycleTime" BO_ 190 12;
BA_ "GenMsgSendType" BO_ 190 0;
BA_ "GenMsgILSupport" BO_ 1361 0;
BA_ "TpApplType" BO_ 1361 "DiagUUDTResponse";
BA_ "Prio" BO_ 1361 0;
BA_ "MessageSubnet" BO_ 1361 2;
BA_ "GenMsgILSupport" BO_ 1345 0;
BA_ "TpApplType" BO_ 1345 "DiagUUDTResponse";
BA_ "Prio" BO_ 1345 0;
BA_ "MessageSubnet" BO_ 1345 2;
BA_ "Prio" BO_ 322 0;
BA_ "MessageSubnet" BO_ 322 2;
BA_ "GenMsgStartDelayTime" BO_ 322 90;
BA_ "GenMsgCycleTime" BO_ 322 100;
BA_ "GenMsgSendType" BO_ 322 0;
BA_ "Prio" BO_ 1608 0;
BA_ "MessageSubnet" BO_ 1608 2;
BA_ "DiagResponse" BO_ 1608 1;
BA_ "Prio" BO_ 534 0;
BA_ "MessageSubnet" BO_ 534 2;
BA_ "GenMsgCycleTime" BO_ 534 100;
BA_ "GenMsgSendType" BO_ 534 0;
BA_ "Prio" BO_ 309 0;
BA_ "MessageSubnet" BO_ 309 2;
BA_ "GenMsgStartDelayTime" BO_ 309 50;
BA_ "GenMsgCycleTime" BO_ 309 100;
BA_ "GenMsgSendType" BO_ 309 0;
BA_ "Prio" BO_ 389 0;
BA_ "MessageSubnet" BO_ 389 2;
BA_ "GenMsgCycleTime" BO_ 389 20;
BA_ "GenMsgSendType" BO_ 389 0;
BA_ "Prio" BO_ 1922 0;
BA_ "MessageSubnet" BO_ 1922 2;
BA_ "GenMsgCycleTime" BO_ 1922 1000;
BA_ "GenMsgSendType" BO_ 1922 0;
BA_ "Prio" BO_ 352 0;
BA_ "MessageSubnet" BO_ 352 2;
BA_ "GenMsgStartDelayTime" BO_ 352 30;
BA_ "GenMsgCycleTime" BO_ 352 100;
BA_ "GenMsgSendType" BO_ 352 0;
BA_ "Prio" BO_ 562 0;
BA_ "MessageSubnet" BO_ 562 2;
BA_ "GenMsgCycleTime" BO_ 562 50;
BA_ "GenMsgSendType" BO_ 562 0;
BA_ "Prio" BO_ 893 0;
BA_ "MessageSubnet" BO_ 893 2;
BA_ "GenMsgCycleTime" BO_ 893 100;
BA_ "GenMsgSendType" BO_ 893 0;
BA_ "Prio" BO_ 892 0;
BA_ "MessageSubnet" BO_ 892 2;
BA_ "GenMsgCycleTime" BO_ 892 100;
BA_ "GenMsgSendType" BO_ 892 0;
BA_ "Prio" BO_ 386 0;
BA_ "MessageSubnet" BO_ 386 2;
BA_ "GenMsgCycleTime" BO_ 386 100;
BA_ "GenMsgSendType" BO_ 386 0;
BA_ "GenMsgILSupport" BO_ 597 0;
BA_ "Prio" BO_ 597 0;
BA_ "MessageSubnet" BO_ 597 2;
BA_ "DiagRequest" BO_ 597 1;
BA_ "GenMsgILSupport" BO_ 1621 0;
BA_ "Prio" BO_ 1621 0;
BA_ "MessageSubnet" BO_ 1621 2;
BA_ "DiagResponse" BO_ 1621 1;
BA_ "Prio" BO_ 532 0;
BA_ "MessageSubnet" BO_ 532 2;
BA_ "GenMsgCycleTime" BO_ 532 50;
BA_ "GenMsgSendType" BO_ 532 0;
BA_ "Prio" BO_ 890 0;
BA_ "MessageSubnet" BO_ 890 2;
BA_ "GenMsgCycleTime" BO_ 890 100;
BA_ "GenMsgSendType" BO_ 890 0;
BA_ "Prio" BO_ 592 0;
BA_ "MessageSubnet" BO_ 592 2;
BA_ "DiagRequest" BO_ 592 1;
BA_ "GenMsgILSupport" BO_ 1365 0;
BA_ "TpApplType" BO_ 1365 "DiagUUDTResponse";
BA_ "Prio" BO_ 1365 0;
BA_ "MessageSubnet" BO_ 1365 2;
BA_ "Prio" BO_ 328 0;
BA_ "MessageSubnet" BO_ 328 2;
BA_ "GenMsgDelayTime" BO_ 328 100;
BA_ "GenMsgCycleTime" BO_ 328 1000;
BA_ "GenMsgSendType" BO_ 328 0;
BA_ "Prio" BO_ 560 0;
BA_ "MessageSubnet" BO_ 560 2;
BA_ "GenMsgCycleTime" BO_ 560 50;
BA_ "GenMsgSendType" BO_ 560 0;
BA_ "Prio" BO_ 451 0;
BA_ "MessageSubnet" BO_ 451 2;
BA_ "GenMsgCycleTime" BO_ 451 25;
BA_ "GenMsgSendType" BO_ 451 0;
BA_ "Prio" BO_ 801 0;
BA_ "MessageSubnet" BO_ 801 2;
BA_ "GenMsgCycleTime" BO_ 801 25;
BA_ "GenMsgSendType" BO_ 801 0;
BA_ "Prio" BO_ 320 0;
BA_ "MessageSubnet" BO_ 320 2;
BA_ "GenMsgStartDelayTime" BO_ 320 30;
BA_ "GenMsgDelayTime" BO_ 320 10;
BA_ "GenMsgCycleTime" BO_ 320 1000;
BA_ "GenMsgSendType" BO_ 320 0;
BA_ "Prio" BO_ 957 0;
BA_ "MessageSubnet" BO_ 957 2;
BA_ "GenMsgCycleTime" BO_ 957 100;
BA_ "GenMsgSendType" BO_ 957 0;
BA_ "GenMsgILSupport" BO_ 1364 0;
BA_ "TpApplType" BO_ 1364 "DiagUUDTResponse";
BA_ "Prio" BO_ 1364 0;
BA_ "MessageSubnet" BO_ 1364 2;
BA_ "Prio" BO_ 2041 0;
BA_ "MessageSubnet" BO_ 2041 2;
BA_ "Prio" BO_ 1904 6;
BA_ "MessageSubnet" BO_ 1904 2;
BA_ "GenMsgCycleTime" BO_ 1904 1000;
BA_ "GenMsgSendType" BO_ 1904 0;
BA_ "Prio" BO_ 1908 6;
BA_ "MessageSubnet" BO_ 1908 2;
BA_ "GenMsgCycleTime" BO_ 1908 1000;
BA_ "GenMsgSendType" BO_ 1908 0;
BA_ "Prio" BO_ 1909 6;
BA_ "MessageSubnet" BO_ 1909 2;
BA_ "GenMsgCycleTime" BO_ 1909 1000;
BA_ "GenMsgSendType" BO_ 1909 0;
BA_ "VNSigSLHSSharedDiagnostic" SG_ 1373 DgnInf_HS55D 1;
BA_ "SignalType" SG_ 1373 DgnInf_HS55D "UNM";
BA_ "SignalLongName" SG_ 1373 DgnInf_HS55D "Diagnostic Information HS55D";
BA_ "VNSigAllNodes" SG_ 1373 DgnInf_HS55D 1;
BA_ "VNSigSLHSSharedDiagnostic" SG_ 1372 DgnInf_HS55C 1;
BA_ "SignalType" SG_ 1372 DgnInf_HS55C "UNM";
BA_ "SignalLongName" SG_ 1372 DgnInf_HS55C "Diagnostic Information HS55C";
BA_ "VNSigAllNodes" SG_ 1372 DgnInf_HS55C 1;
BA_ "VNSigSLHSSharedDiagnostic" SG_ 1371 DgnInf_HS55B 1;
BA_ "SignalType" SG_ 1371 DgnInf_HS55B "UNM";
BA_ "SignalLongName" SG_ 1371 DgnInf_HS55B "Diagnostic Information HS55B";
BA_ "VNSigAllNodes" SG_ 1371 DgnInf_HS55B 1;
BA_ "VNSigSLHSSharedDiagnostic" SG_ 1370 DgnInf_HS55A 1;
BA_ "SignalType" SG_ 1370 DgnInf_HS55A "UNM";
BA_ "SignalLongName" SG_ 1370 DgnInf_HS55A "Diagnostic Information HS55A";
BA_ "VNSigAllNodes" SG_ 1370 DgnInf_HS55A 1;
BA_ "VNSigSLHSSharedDiagnostic" SG_ 1368 DgnInf_HS558 1;
BA_ "SignalType" SG_ 1368 DgnInf_HS558 "UNM";
BA_ "SignalLongName" SG_ 1368 DgnInf_HS558 "Diagnostic Information HS558";
BA_ "VNSigAllNodes" SG_ 1368 DgnInf_HS558 1;
BA_ "VNSigSLHSSharedDiagnostic" SG_ 1367 DgnInf_HS557 1;
BA_ "SignalType" SG_ 1367 DgnInf_HS557 "UNM";
BA_ "SignalLongName" SG_ 1367 DgnInf_HS557 "Diagnostic Information HS557";
BA_ "VNSigAllNodes" SG_ 1367 DgnInf_HS557 1;
BA_ "VNSigSLHSSharedDiagnostic" SG_ 1366 DgnInf_HS556 1;
BA_ "SignalType" SG_ 1366 DgnInf_HS556 "UNM";
BA_ "SignalLongName" SG_ 1366 DgnInf_HS556 "Diagnostic Information HS556";
BA_ "VNSigAllNodes" SG_ 1366 DgnInf_HS556 1;
BA_ "VNSigSLHSSharedDiagnostic" SG_ 1362 DgnInf_HS552 1;
BA_ "SignalType" SG_ 1362 DgnInf_HS552 "UNM";
BA_ "SignalLongName" SG_ 1362 DgnInf_HS552 "Diagnostic Information HS552";
BA_ "VNSigAllNodes" SG_ 1362 DgnInf_HS552 1;
BA_ "VNSigSLHSSharedDiagnostic" SG_ 1628 DgnInf 1;
BA_ "SignalType" SG_ 1628 DgnInf "UNM";
BA_ "SignalLongName" SG_ 1628 DgnInf "Diagnostic Information";
BA_ "VNSigAllNodes" SG_ 1628 DgnInf 1;
BA_ "VNSigSLHSSharedDiagnostic" SG_ 1627 DgnInf 1;
BA_ "SignalType" SG_ 1627 DgnInf "UNM";
BA_ "SignalLongName" SG_ 1627 DgnInf "Diagnostic Information";
BA_ "VNSigAllNodes" SG_ 1627 DgnInf 1;
BA_ "VNSigSLHSSharedDiagnostic" SG_ 1626 DgnInf 1;
BA_ "SignalType" SG_ 1626 DgnInf "UNM";
BA_ "SignalLongName" SG_ 1626 DgnInf "Diagnostic Information";
BA_ "VNSigAllNodes" SG_ 1626 DgnInf 1;
BA_ "VNSigSLHSSharedDiagnostic" SG_ 1624 DgnInf 1;
BA_ "SignalType" SG_ 1624 DgnInf "UNM";
BA_ "SignalLongName" SG_ 1624 DgnInf "Diagnostic Information";
BA_ "VNSigAllNodes" SG_ 1624 DgnInf 1;
BA_ "VNSigSLHSSharedDiagnostic" SG_ 1623 DgnInf 1;
BA_ "SignalType" SG_ 1623 DgnInf "UNM";
BA_ "SignalLongName" SG_ 1623 DgnInf "Diagnostic Information";
BA_ "VNSigAllNodes" SG_ 1623 DgnInf 1;
BA_ "VNSigSLHSSharedDiagnostic" SG_ 1622 DgnInf 1;
BA_ "SignalType" SG_ 1622 DgnInf "UNM";
BA_ "SignalLongName" SG_ 1622 DgnInf "Diagnostic Information";
BA_ "VNSigAllNodes" SG_ 1622 DgnInf 1;
BA_ "VNSigSLHSSharedDiagnostic" SG_ 1619 DgnInf 1;
BA_ "SignalType" SG_ 1619 DgnInf "UNM";
BA_ "SignalLongName" SG_ 1619 DgnInf "Diagnostic Information";
BA_ "VNSigAllNodes" SG_ 1619 DgnInf 1;
BA_ "VNSigSLHSSharedDiagnostic" SG_ 1618 DgnInf 1;
BA_ "SignalType" SG_ 1618 DgnInf "UNM";
BA_ "SignalLongName" SG_ 1618 DgnInf "Diagnostic Information";
BA_ "VNSigAllNodes" SG_ 1618 DgnInf 1;
BA_ "VNSigSLHSSharedDiagnostic" SG_ 1617 DgnInf 1;
BA_ "SignalType" SG_ 1617 DgnInf "UNM";
BA_ "SignalLongName" SG_ 1617 DgnInf "Diagnostic Information";
BA_ "VNSigAllNodes" SG_ 1617 DgnInf 1;
BA_ "VNSigSLHSSharedDiagnostic" SG_ 600 DgnInf 1;
BA_ "SignalType" SG_ 600 DgnInf "UNM";
BA_ "SignalLongName" SG_ 600 DgnInf "Diagnostic Information";
BA_ "VNSigAllNodes" SG_ 600 DgnInf 1;
BA_ "VNSigSLHSSharedDiagnostic" SG_ 599 DgnInf 1;
BA_ "SignalType" SG_ 599 DgnInf "UNM";
BA_ "SignalLongName" SG_ 599 DgnInf "Diagnostic Information";
BA_ "VNSigAllNodes" SG_ 599 DgnInf 1;
BA_ "VNSigSLHSSharedDiagnostic" SG_ 598 DgnInf 1;
BA_ "SignalType" SG_ 598 DgnInf "UNM";
BA_ "SignalLongName" SG_ 598 DgnInf "Diagnostic Information";
BA_ "VNSigAllNodes" SG_ 598 DgnInf 1;
BA_ "VNSigSLHSSharedDiagnostic" SG_ 595 DgnInf 1;
BA_ "SignalType" SG_ 595 DgnInf "UNM";
BA_ "SignalLongName" SG_ 595 DgnInf "Diagnostic Information";
BA_ "VNSigAllNodes" SG_ 595 DgnInf 1;
BA_ "VNSigSLHSSharedDiagnostic" SG_ 594 DgnInf 1;
BA_ "SignalType" SG_ 594 DgnInf "UNM";
BA_ "SignalLongName" SG_ 594 DgnInf "Diagnostic Information";
BA_ "VNSigAllNodes" SG_ 594 DgnInf 1;
BA_ "VNSigSLHSSharedDiagnostic" SG_ 593 DgnInf 1;
BA_ "SignalType" SG_ 593 DgnInf "UNM";
BA_ "SignalLongName" SG_ 593 DgnInf "Diagnostic Information";
BA_ "VNSigAllNodes" SG_ 593 DgnInf 1;
BA_ "SignalType" SG_ 1280 TireRRLowTracIO "BLN";
BA_ "SignalLongName" SG_ 1280 TireRRLowTracIO "Tire Right Rear Low Traction Indication On";
BA_ "VNSigAllNodes" SG_ 1280 TireRRLowTracIO 1;
BA_ "SignalType" SG_ 1280 TireRFLowTracIO "BLN";
BA_ "SignalLongName" SG_ 1280 TireRFLowTracIO "Tire Right Front Low Traction Indication On";
BA_ "VNSigAllNodes" SG_ 1280 TireRFLowTracIO 1;
BA_ "SignalType" SG_ 1280 TireLRLowTracIO "BLN";
BA_ "SignalLongName" SG_ 1280 TireLRLowTracIO "Tire Left Rear Low Traction Indication On";
BA_ "VNSigAllNodes" SG_ 1280 TireLRLowTracIO 1;
BA_ "SignalType" SG_ 1280 TireLFLowTracIO "BLN";
BA_ "SignalLongName" SG_ 1280 TireLFLowTracIO "Tire Left Front Low Traction Indication On";
BA_ "VNSigAllNodes" SG_ 1280 TireLFLowTracIO 1;
BA_ "SignalType" SG_ 1280 WhlRotStatTmstmpRes "UNM";
BA_ "SignalLongName" SG_ 1280 WhlRotStatTmstmpRes "Wheel Rotational Status Timestamp Resolution";
BA_ "VNSigAllNodes" SG_ 1280 WhlRotStatTmstmpRes 1;
BA_ "SignalType" SG_ 1280 WhlPlsPerRevNonDrvn "UNM";
BA_ "SignalLongName" SG_ 1280 WhlPlsPerRevNonDrvn "Wheel Pulses Per Revolution Non Driven";
BA_ "VNSigAllNodes" SG_ 1280 WhlPlsPerRevNonDrvn 1;
BA_ "SignalType" SG_ 1280 WhlPlsPerRevDrvn "UNM";
BA_ "SignalLongName" SG_ 1280 WhlPlsPerRevDrvn "Wheel Pulses Per Revolution Driven";
BA_ "VNSigAllNodes" SG_ 1280 WhlPlsPerRevDrvn 1;
BA_ "SignalType" SG_ 190 EngSpdMaxCapRdcdRng "UNM";
BA_ "SignalLongName" SG_ 190 EngSpdMaxCapRdcdRng "Engine Speed Maximum Capacity Reduced Range";
BA_ "VNSigAllNodes" SG_ 190 EngSpdMaxCapRdcdRng 1;
BA_ "SignalType" SG_ 190 PTSnsdBrkPdlInfPVal "UNM";
BA_ "SignalLongName" SG_ 190 PTSnsdBrkPdlInfPVal "Powertrain Sensed Brake Pedal Information Protection Value";
BA_ "VNSigAllNodes" SG_ 190 PTSnsdBrkPdlInfPVal 1;
BA_ "SignalType" SG_ 190 TrnsAuxPmpAct "BLN";
BA_ "SignalLongName" SG_ 190 TrnsAuxPmpAct "Transmission Auxiliary Pump Active";
BA_ "VNSigAllNodes" SG_ 190 TrnsAuxPmpAct 1;
BA_ "SignalType" SG_ 190 AccPos "UNM";
BA_ "SignalLongName" SG_ 190 AccPos "Accelerator Effective Position";
BA_ "VNSigAllNodes" SG_ 190 AccPos 1;
BA_ "SignalType" SG_ 190 PTSnsdBrkPdlInfARC "UNM";
BA_ "SignalLongName" SG_ 190 PTSnsdBrkPdlInfARC "Powertrain Sensed Brake Pedal Information Alive Rolling Count";
BA_ "VNSigAllNodes" SG_ 190 PTSnsdBrkPdlInfARC 1;
BA_ "SignalType" SG_ 190 PSBPI_PTSnBrkPdlPsV "ENM";
BA_ "PacketOrder" SG_ 190 PSBPI_PTSnBrkPdlPsV 1;
BA_ "SignalLongName" SG_ 190 PSBPI_PTSnBrkPdlPsV "Powertrain Sensed Brake Pedal Information : Powertrain Sensed Brake Pedal Position Validity";
BA_ "VNSigAllNodes" SG_ 190 PSBPI_PTSnBrkPdlPsV 1;
BA_ "SignalType" SG_ 190 PSBPI_PTSnBrkPdlPs "UNM";
BA_ "PacketOrder" SG_ 190 PSBPI_PTSnBrkPdlPs 2;
BA_ "SignalLongName" SG_ 190 PSBPI_PTSnBrkPdlPs "Powertrain Sensed Brake Pedal Information : Powertrain Sensed Brake Pedal Position";
BA_ "VNSigAllNodes" SG_ 190 PSBPI_PTSnBrkPdlPs 1;
BA_ "VNSigSLHSSharedDiagnostic" SG_ 1361 DgnInf_HS551 1;
BA_ "SignalType" SG_ 1361 DgnInf_HS551 "UNM";
BA_ "SignalLongName" SG_ 1361 DgnInf_HS551 "Diagnostic Information HS551";
BA_ "VNSigAllNodes" SG_ 1361 DgnInf_HS551 1;
BA_ "VNSigSLHSSharedDiagnostic" SG_ 1345 DgnInf_HS541 1;
BA_ "SignalType" SG_ 1345 DgnInf_HS541 "UNM";
BA_ "SignalLongName" SG_ 1345 DgnInf_HS541 "Diagnostic Information HS541";
BA_ "VNSigAllNodes" SG_ 1345 DgnInf_HS541 1;
BA_ "SignalType" SG_ 322 AFLGPSCstStReq "ENM";
BA_ "SignalLongName" SG_ 322 AFLGPSCstStReq "Adaptive Forward Lighting With GPS Customization Setting Request";
BA_ "VNSigAllNodes" SG_ 322 AFLGPSCstStReq 1;
BA_ "SignalType" SG_ 322 AFLCstStReq "ENM";
BA_ "SignalLongName" SG_ 322 AFLCstStReq "Adaptive Forward Lighting Customization Setting Request";
BA_ "VNSigAllNodes" SG_ 322 AFLCstStReq 1;
BA_ "SignalType" SG_ 322 LtRtHnTrCstStReq "ENM";
BA_ "SignalLongName" SG_ 322 LtRtHnTrCstStReq "Left Right Hand Traffic Customization Setting Request";
BA_ "VNSigAllNodes" SG_ 322 LtRtHnTrCstStReq 1;
BA_ "SignalType" SG_ 322 AdpHgBmAsSnCsStRq "ENM";
BA_ "SignalLongName" SG_ 322 AdpHgBmAsSnCsStRq "Adaptive High Beam Assist With Sensitivity Customization Setting Request";
BA_ "VNSigAllNodes" SG_ 322 AdpHgBmAsSnCsStRq 1;
BA_ "SignalType" SG_ 322 AdpHgBmAstCstStRq "ENM";
BA_ "SignalLongName" SG_ 322 AdpHgBmAstCstStRq "Adaptive High Beam Assist Customization Setting Request";
BA_ "VNSigAllNodes" SG_ 322 AdpHgBmAstCstStRq 1;
BA_ "SignalType" SG_ 322 LtRtHnTrGPSCstStRq "ENM";
BA_ "SignalLongName" SG_ 322 LtRtHnTrGPSCstStRq "Left Right Hand Traffic With GPS Customization Setting Request";
BA_ "VNSigAllNodes" SG_ 322 LtRtHnTrGPSCstStRq 1;
BA_ "SignalType" SG_ 322 AutHgBmAsSnCsStRq "ENM";
BA_ "SignalLongName" SG_ 322 AutHgBmAsSnCsStRq "Auto High Beam Assist With Sensitivity Customization Setting Request";
BA_ "VNSigAllNodes" SG_ 322 AutHgBmAsSnCsStRq 1;
BA_ "SignalType" SG_ 322 AutHgBmAstCstStRq "ENM";
BA_ "SignalLongName" SG_ 322 AutHgBmAstCstStRq "Auto High Beam Assist Customization Setting Request";
BA_ "VNSigAllNodes" SG_ 322 AutHgBmAstCstStRq 1;
BA_ "VNSigSLHSSharedDiagnostic" SG_ 1608 DgnInf 1;
BA_ "SignalType" SG_ 1608 DgnInf "UNM";
BA_ "SignalLongName" SG_ 1608 DgnInf "Diagnostic Information";
BA_ "VNSigAllNodes" SG_ 1608 DgnInf 1;
BA_ "SignalType" SG_ 534 DmpSysVehTopSpdLim "UNM";
BA_ "SignalLongName" SG_ 534 DmpSysVehTopSpdLim "Damping System Vehicle Top Speed Limit Value";
BA_ "GenSigStartValue" SG_ 534 DmpSysVehTopSpdLim 255;
BA_ "VNSigAllNodes" SG_ 534 DmpSysVehTopSpdLim 1;
BA_ "SignalType" SG_ 534 SrvSuspSysIO "BLN";
BA_ "SignalLongName" SG_ 534 SrvSuspSysIO "Service Suspension System Indication On";
BA_ "VNSigAllNodes" SG_ 534 SrvSuspSysIO 1;
BA_ "SignalType" SG_ 309 StBltTgtCSRq "ENM";
BA_ "SignalLongName" SG_ 309 StBltTgtCSRq "Seat Belt Tightening Customize Setting Request";
BA_ "VNSigAllNodes" SG_ 309 StBltTgtCSRq 1;
BA_ "SignalType" SG_ 309 ColPrSysCustReq "ENM";
BA_ "SignalLongName" SG_ 309 ColPrSysCustReq "Collision Preparation System Customization Setting Request";
BA_ "VNSigAllNodes" SG_ 309 ColPrSysCustReq 1;
BA_ "SignalType" SG_ 309 SecV "ENM";
BA_ "SignalLongName" SG_ 309 SecV "Seconds Validity";
BA_ "VNSigAllNodes" SG_ 309 SecV 1;
BA_ "SignalType" SG_ 309 Sec "UNM";
BA_ "SignalLongName" SG_ 309 Sec "Seconds";
BA_ "VNSigAllNodes" SG_ 309 Sec 1;
BA_ "SignalType" SG_ 309 CldrYr_154 "UNM";
BA_ "SignalLongName" SG_ 309 CldrYr_154 "Calendar Year";
BA_ "VNSigAllNodes" SG_ 309 CldrYr_154 1;
BA_ "SignalType" SG_ 309 CldrYr "UNM";
BA_ "SignalLongName" SG_ 309 CldrYr "Calendar Year";
BA_ "VNSigAllNodes" SG_ 309 CldrYr 1;
BA_ "SignalType" SG_ 309 CldrMth_154 "ENM";
BA_ "SignalLongName" SG_ 309 CldrMth_154 "Calendar Month";
BA_ "VNSigAllNodes" SG_ 309 CldrMth_154 1;
BA_ "SignalType" SG_ 309 CldrMth "ENM";
BA_ "SignalLongName" SG_ 309 CldrMth "Calendar Month";
BA_ "VNSigAllNodes" SG_ 309 CldrMth 1;
BA_ "SignalType" SG_ 309 CldrDay_154 "UNM";
BA_ "SignalLongName" SG_ 309 CldrDay_154 "Calendar Day";
BA_ "VNSigAllNodes" SG_ 309 CldrDay_154 1;
BA_ "SignalType" SG_ 309 CldrDay "UNM";
BA_ "SignalLongName" SG_ 309 CldrDay "Calendar Day";
BA_ "VNSigAllNodes" SG_ 309 CldrDay 1;
BA_ "SignalType" SG_ 309 AutoHiBmVDA "ENM";
BA_ "SignalLongName" SG_ 309 AutoHiBmVDA "Automatic High Beam Virtual Device Availability";
BA_ "GenSigStartValue" SG_ 309 AutoHiBmVDA 1;
BA_ "VNSigAllNodes" SG_ 309 AutoHiBmVDA 1;
BA_ "SignalType" SG_ 309 CtLghtDet "BLN";
BA_ "SignalLongName" SG_ 309 CtLghtDet "City Light Detected";
BA_ "VNSigAllNodes" SG_ 309 CtLghtDet 1;
BA_ "SignalType" SG_ 309 RrClosVDA "ENM";
BA_ "SignalLongName" SG_ 309 RrClosVDA "Rear Closure Virtual Device Availability";
BA_ "GenSigStartValue" SG_ 309 RrClosVDA 1;
BA_ "VNSigAllNodes" SG_ 309 RrClosVDA 1;
BA_ "SignalType" SG_ 309 TCSysDisSwAtv "BLN";
BA_ "SignalLongName" SG_ 309 TCSysDisSwAtv "Traction Control System Disable Switch Active";
BA_ "VNSigAllNodes" SG_ 309 TCSysDisSwAtv 1;
BA_ "SignalType" SG_ 309 VehMovState "ENM";
BA_ "SignalLongName" SG_ 309 VehMovState "Vehicle Movement State";
BA_ "VNSigAllNodes" SG_ 309 VehMovState 1;
BA_ "SignalType" SG_ 309 TCSysDisSwAtvV "ENM";
BA_ "SignalLongName" SG_ 309 TCSysDisSwAtvV "Traction Control System Disable Switch Active Validity";
BA_ "VNSigAllNodes" SG_ 309 TCSysDisSwAtvV 1;
BA_ "SignalType" SG_ 309 HillDesCtrlMdSwActV "ENM";
BA_ "SignalLongName" SG_ 309 HillDesCtrlMdSwActV "Hill Descent Control Mode Switch Active Validity";
BA_ "VNSigAllNodes" SG_ 309 HillDesCtrlMdSwActV 1;
BA_ "SignalType" SG_ 309 WSWshSwAtv "BLN";
BA_ "SignalLongName" SG_ 309 WSWshSwAtv "Windshield Washer Switch Active";
BA_ "VNSigAllNodes" SG_ 309 WSWshSwAtv 1;
BA_ "SignalType" SG_ 309 HillDesCtrlMdSwAct "BLN";
BA_ "SignalLongName" SG_ 309 HillDesCtrlMdSwAct "Hill Descent Control Mode Switch Active";
BA_ "VNSigAllNodes" SG_ 309 HillDesCtrlMdSwAct 1;
BA_ "SignalType" SG_ 309 RrClosAjarSwAct "BLN";
BA_ "SignalLongName" SG_ 309 RrClosAjarSwAct "Rear Closure Ajar Switch Active";
BA_ "VNSigAllNodes" SG_ 309 RrClosAjarSwAct 1;
BA_ "SignalType" SG_ 309 WSWprAct "BLN";
BA_ "SignalLongName" SG_ 309 WSWprAct "Windshield Wiper Active";
BA_ "VNSigAllNodes" SG_ 309 WSWprAct 1;
BA_ "SignalType" SG_ 389 VSELongAccLoResV "ENM";
BA_ "SignalLongName" SG_ 389 VSELongAccLoResV "Vehicle Stability Enhancement Longitudinal Acceleration Low Resolution Validity";
BA_ "VNSigAllNodes" SG_ 389 VSELongAccLoResV 1;
BA_ "SignalType" SG_ 389 VSELongAccLoRes "SNM";
BA_ "SignalLongName" SG_ 389 VSELongAccLoRes "Vehicle Stability Enhancement Longitudinal Acceleration Low Resolution";
BA_ "VNSigAllNodes" SG_ 389 VSELongAccLoRes 1;
BA_ "SignalType" SG_ 389 StrAngSnsPolRat "ENM";
BA_ "SignalLongName" SG_ 389 StrAngSnsPolRat "Steering Angle Sensor Polarity Rationality";
BA_ "VNSigAllNodes" SG_ 389 StrAngSnsPolRat 1;
BA_ "SignalType" SG_ 389 LatAccSnsPolRat "ENM";
BA_ "SignalLongName" SG_ 389 LatAccSnsPolRat "Lateral Acceleration Sensor Polarity Rationality";
BA_ "VNSigAllNodes" SG_ 389 LatAccSnsPolRat 1;
BA_ "SignalType" SG_ 1922 DTCI_WrnIndRqdSt_782 "BLN";
BA_ "PacketOrder" SG_ 1922 DTCI_WrnIndRqdSt_782 12;
BA_ "SignalLongName" SG_ 1922 DTCI_WrnIndRqdSt_782 "Diagnostic Trouble Code Information Extended 782 : Warning Indicator Requested Status";
BA_ "VNSigAllNodes" SG_ 1922 DTCI_WrnIndRqdSt_782 1;
BA_ "SignalType" SG_ 1922 DTCIUnused7_782 "BLN";
BA_ "PacketOrder" SG_ 1922 DTCIUnused7_782 7;
BA_ "SignalLongName" SG_ 1922 DTCIUnused7_782 "Diagnostic Trouble Code Information Extended 782 : Unused 7";
BA_ "VNSigAllNodes" SG_ 1922 DTCIUnused7_782 1;
BA_ "SignalType" SG_ 1922 DTCIUnused6_782 "BLN";
BA_ "PacketOrder" SG_ 1922 DTCIUnused6_782 6;
BA_ "SignalLongName" SG_ 1922 DTCIUnused6_782 "Diagnostic Trouble Code Information Extended 782 : Unused 6";
BA_ "VNSigAllNodes" SG_ 1922 DTCIUnused6_782 1;
BA_ "SignalType" SG_ 1922 DTCIUnused5_782 "BLN";
BA_ "PacketOrder" SG_ 1922 DTCIUnused5_782 5;
BA_ "SignalLongName" SG_ 1922 DTCIUnused5_782 "Diagnostic Trouble Code Information Extended 782 : Unused 5";
BA_ "VNSigAllNodes" SG_ 1922 DTCIUnused5_782 1;
BA_ "SignalType" SG_ 1922 DTCIUnused4_782 "BLN";
BA_ "PacketOrder" SG_ 1922 DTCIUnused4_782 4;
BA_ "SignalLongName" SG_ 1922 DTCIUnused4_782 "Diagnostic Trouble Code Information Extended 782 : Unused 4";
BA_ "VNSigAllNodes" SG_ 1922 DTCIUnused4_782 1;
BA_ "SignalType" SG_ 1922 DTCIUnused3_782 "BLN";
BA_ "PacketOrder" SG_ 1922 DTCIUnused3_782 3;
BA_ "SignalLongName" SG_ 1922 DTCIUnused3_782 "Diagnostic Trouble Code Information Extended 782 : Unused 3";
BA_ "VNSigAllNodes" SG_ 1922 DTCIUnused3_782 1;
BA_ "SignalType" SG_ 1922 DTCIUnused2_782 "BLN";
BA_ "PacketOrder" SG_ 1922 DTCIUnused2_782 2;
BA_ "SignalLongName" SG_ 1922 DTCIUnused2_782 "Diagnostic Trouble Code Information Extended 782 : Unused 2";
BA_ "VNSigAllNodes" SG_ 1922 DTCIUnused2_782 1;
BA_ "SignalType" SG_ 1922 DTCIUnused1_782 "BLN";
BA_ "PacketOrder" SG_ 1922 DTCIUnused1_782 1;
BA_ "SignalLongName" SG_ 1922 DTCIUnused1_782 "Diagnostic Trouble Code Information Extended 782 : Unused 1";
BA_ "VNSigAllNodes" SG_ 1922 DTCIUnused1_782 1;
BA_ "SignalType" SG_ 1922 DTCI_TstNPsdPwrUpSt_782 "BLN";
BA_ "PacketOrder" SG_ 1922 DTCI_TstNPsdPwrUpSt_782 14;
BA_ "SignalLongName" SG_ 1922 DTCI_TstNPsdPwrUpSt_782 "Diagnostic Trouble Code Information Extended 782 : Test Not Passed Since Power Up Status";
BA_ "VNSigAllNodes" SG_ 1922 DTCI_TstNPsdPwrUpSt_782 1;
BA_ "SignalType" SG_ 1922 DTCI_TstNPsdCdClrdSt_782 "BLN";
BA_ "PacketOrder" SG_ 1922 DTCI_TstNPsdCdClrdSt_782 17;
BA_ "SignalLongName" SG_ 1922 DTCI_TstNPsdCdClrdSt_782 "Diagnostic Trouble Code Information Extended 782 : Test Not Passed Since Code Cleared Status";
BA_ "VNSigAllNodes" SG_ 1922 DTCI_TstNPsdCdClrdSt_782 1;
BA_ "SignalType" SG_ 1922 DTCI_TstFldPwrUpSt_782 "BLN";
BA_ "PacketOrder" SG_ 1922 DTCI_TstFldPwrUpSt_782 13;
BA_ "SignalLongName" SG_ 1922 DTCI_TstFldPwrUpSt_782 "Diagnostic Trouble Code Information Extended 782 : Test Failed Since Power Up Status";
BA_ "VNSigAllNodes" SG_ 1922 DTCI_TstFldPwrUpSt_782 1;
BA_ "SignalType" SG_ 1922 DTCI_TstFldCdClrdStat_782 "BLN";
BA_ "PacketOrder" SG_ 1922 DTCI_TstFldCdClrdStat_782 16;
BA_ "SignalLongName" SG_ 1922 DTCI_TstFldCdClrdStat_782 "Diagnostic Trouble Code Information Extended 782 : Test Failed Since Code Cleared Status";
BA_ "VNSigAllNodes" SG_ 1922 DTCI_TstFldCdClrdStat_782 1;
BA_ "SignalType" SG_ 1922 DTCI_HistStat_782 "BLN";
BA_ "PacketOrder" SG_ 1922 DTCI_HistStat_782 15;
BA_ "SignalLongName" SG_ 1922 DTCI_HistStat_782 "Diagnostic Trouble Code Information Extended 782 : History Status";
BA_ "VNSigAllNodes" SG_ 1922 DTCI_HistStat_782 1;
BA_ "SignalType" SG_ 1922 DTCI_DTCTriggered_782 "BLN";
BA_ "PacketOrder" SG_ 1922 DTCI_DTCTriggered_782 8;
BA_ "SignalLongName" SG_ 1922 DTCI_DTCTriggered_782 "Diagnostic Trouble Code Information Extended 782 : Diagnostic Trouble Code Triggered";
BA_ "VNSigAllNodes" SG_ 1922 DTCI_DTCTriggered_782 1;
BA_ "SignalType" SG_ 1922 DTCI_DTCSource_782 "UNM";
BA_ "PacketOrder" SG_ 1922 DTCI_DTCSource_782 9;
BA_ "SignalLongName" SG_ 1922 DTCI_DTCSource_782 "Diagnostic Trouble Code Information Extended 782 : Diagnostic Trouble Code Source";
BA_ "VNSigAllNodes" SG_ 1922 DTCI_DTCSource_782 1;
BA_ "SignalType" SG_ 1922 DTCI_DTCNumber_782 "UNM";
BA_ "PacketOrder" SG_ 1922 DTCI_DTCNumber_782 10;
BA_ "SignalLongName" SG_ 1922 DTCI_DTCNumber_782 "Diagnostic Trouble Code Information Extended 782 : Diagnostic Trouble Code Number";
BA_ "VNSigAllNodes" SG_ 1922 DTCI_DTCNumber_782 1;
BA_ "SignalType" SG_ 1922 DTCI_DTCFaultType_782 "ENM";
BA_ "PacketOrder" SG_ 1922 DTCI_DTCFaultType_782 20;
BA_ "SignalLongName" SG_ 1922 DTCI_DTCFaultType_782 "Diagnostic Trouble Code Information Extended 782 : Diagnostic Trouble Code Fault Type";
BA_ "VNSigAllNodes" SG_ 1922 DTCI_DTCFaultType_782 1;
BA_ "SignalType" SG_ 1922 DTCI_DTCFailType_782 "UNM";
BA_ "PacketOrder" SG_ 1922 DTCI_DTCFailType_782 11;
BA_ "SignalLongName" SG_ 1922 DTCI_DTCFailType_782 "Diagnostic Trouble Code Information Extended 782 : Diagnostic Trouble Code Failure Type";
BA_ "VNSigAllNodes" SG_ 1922 DTCI_DTCFailType_782 1;
BA_ "SignalType" SG_ 1922 DTCI_CurrentStatus_782 "BLN";
BA_ "PacketOrder" SG_ 1922 DTCI_CurrentStatus_782 18;
BA_ "SignalLongName" SG_ 1922 DTCI_CurrentStatus_782 "Diagnostic Trouble Code Information Extended 782 : Current Status";
BA_ "VNSigAllNodes" SG_ 1922 DTCI_CurrentStatus_782 1;
BA_ "SignalType" SG_ 1922 DTCI_CodeSupported_782 "BLN";
BA_ "PacketOrder" SG_ 1922 DTCI_CodeSupported_782 19;
BA_ "SignalLongName" SG_ 1922 DTCI_CodeSupported_782 "Diagnostic Trouble Code Information Extended 782 : Code Supported";
BA_ "VNSigAllNodes" SG_ 1922 DTCI_CodeSupported_782 1;
BA_ "SignalType" SG_ 352 ShfFrmPrkAlwd "BLN";
BA_ "SignalLongName" SG_ 352 ShfFrmPrkAlwd "Shift From Park Allowed";
BA_ "VNSigAllNodes" SG_ 352 ShfFrmPrkAlwd 1;
BA_ "SignalType" SG_ 352 AVHSwtchStats "ENM";
BA_ "SignalLongName" SG_ 352 AVHSwtchStats "Auto Vehicle Hold Switch Status";
BA_ "VNSigAllNodes" SG_ 352 AVHSwtchStats 1;
BA_ "SignalType" SG_ 352 TeenDrvAct "BLN";
BA_ "SignalLongName" SG_ 352 TeenDrvAct "Teen Driver Active";
BA_ "VNSigAllNodes" SG_ 352 TeenDrvAct 1;
BA_ "SignalType" SG_ 352 LrnEnvIdSt "ENM";
BA_ "SignalLongName" SG_ 352 LrnEnvIdSt "Learn Environment Identification Status";
BA_ "VNSigAllNodes" SG_ 352 LrnEnvIdSt 1;
BA_ "SignalType" SG_ 352 LrnEnvId "UNM";
BA_ "SignalLongName" SG_ 352 LrnEnvId "Learn Environment Identification";
BA_ "VNSigAllNodes" SG_ 352 LrnEnvId 1;
BA_ "SignalType" SG_ 352 ImoId "UNM";
BA_ "SignalLongName" SG_ 352 ImoId "Immobilizer Identifier";
BA_ "VNSigAllNodes" SG_ 352 ImoId 1;
BA_ "SignalType" SG_ 352 ImoIdSt "ENM";
BA_ "SignalLongName" SG_ 352 ImoIdSt "Immobilizer Identifier Status";
BA_ "VNSigAllNodes" SG_ 352 ImoIdSt 1;
BA_ "SignalType" SG_ 562 SndPerfMdCsStAvl "BLN";
BA_ "SignalLongName" SG_ 562 SndPerfMdCsStAvl "Sound Performance Mode Customization Setting Available";
BA_ "VNSigAllNodes" SG_ 562 SndPerfMdCsStAvl 1;
BA_ "SignalType" SG_ 562 SndPerfMdCsCrStVal "ENM";
BA_ "SignalLongName" SG_ 562 SndPerfMdCsCrStVal "Sound Performance Mode Customization Current Setting Value";
BA_ "VNSigAllNodes" SG_ 562 SndPerfMdCsCrStVal 1;
BA_ "SignalType" SG_ 562 DispPerfMdCsStAvl "BLN";
BA_ "SignalLongName" SG_ 562 DispPerfMdCsStAvl "Display Performance Mode Customization Setting Available";
BA_ "VNSigAllNodes" SG_ 562 DispPerfMdCsStAvl 1;
BA_ "SignalType" SG_ 562 DispPerfMdCsCrStVal "ENM";
BA_ "SignalLongName" SG_ 562 DispPerfMdCsCrStVal "Display Performance Mode Customization Current Setting Value";
BA_ "VNSigAllNodes" SG_ 562 DispPerfMdCsCrStVal 1;
BA_ "SignalType" SG_ 562 DrvlneMntsPerfMdRq "ENM";
BA_ "SignalLongName" SG_ 562 DrvlneMntsPerfMdRq "Driveline Mounts Performance Mode Request";
BA_ "VNSigAllNodes" SG_ 562 DrvlneMntsPerfMdRq 1;
BA_ "SignalType" SG_ 562 RideCntrlPerfMdRq "ENM";
BA_ "SignalLongName" SG_ 562 RideCntrlPerfMdRq "Ride Control Performance Mode Request";
BA_ "VNSigAllNodes" SG_ 562 RideCntrlPerfMdRq 1;
BA_ "SignalType" SG_ 562 StgSysPerfMdRq "ENM";
BA_ "SignalLongName" SG_ 562 StgSysPerfMdRq "Steering System Performance Mode Request";
BA_ "VNSigAllNodes" SG_ 562 StgSysPerfMdRq 1;
BA_ "SignalType" SG_ 562 DiffPerfMdRq "ENM";
BA_ "SignalLongName" SG_ 562 DiffPerfMdRq "Differential Performance Mode Request";
BA_ "VNSigAllNodes" SG_ 562 DiffPerfMdRq 1;
BA_ "SignalType" SG_ 562 SndEnhcmtPerfMdRq "ENM";
BA_ "SignalLongName" SG_ 562 SndEnhcmtPerfMdRq "Sound Enhancement Performance Mode Request";
BA_ "VNSigAllNodes" SG_ 562 SndEnhcmtPerfMdRq 1;
BA_ "SignalType" SG_ 562 DsplyPerfMdRq "ENM";
BA_ "SignalLongName" SG_ 562 DsplyPerfMdRq "Display Performance Mode Request";
BA_ "VNSigAllNodes" SG_ 562 DsplyPerfMdRq 1;
BA_ "SignalType" SG_ 562 ExhstPerfMdRq "ENM";
BA_ "SignalLongName" SG_ 562 ExhstPerfMdRq "Exhaust Performance Mode Request";
BA_ "VNSigAllNodes" SG_ 562 ExhstPerfMdRq 1;
BA_ "SignalType" SG_ 562 HillDscntCntlSysStat "ENM";
BA_ "SignalLongName" SG_ 562 HillDscntCntlSysStat "Hill Descent Control System Status";
BA_ "VNSigAllNodes" SG_ 562 HillDscntCntlSysStat 1;
BA_ "SignalType" SG_ 562 SusCustStngAvlbl "BLN";
BA_ "SignalLongName" SG_ 562 SusCustStngAvlbl "Suspension Customization Setting Available";
BA_ "VNSigAllNodes" SG_ 562 SusCustStngAvlbl 1;
BA_ "SignalType" SG_ 562 SusCustCurrStngVal "ENM";
BA_ "SignalLongName" SG_ 562 SusCustCurrStngVal "Suspension Customization Current Setting Value";
BA_ "VNSigAllNodes" SG_ 562 SusCustCurrStngVal 1;
BA_ "SignalType" SG_ 562 StrCustStngAvlbl "BLN";
BA_ "SignalLongName" SG_ 562 StrCustStngAvlbl "Steering Customization Setting Available";
BA_ "VNSigAllNodes" SG_ 562 StrCustStngAvlbl 1;
BA_ "SignalType" SG_ 562 StrCustCurrStngVal "ENM";
BA_ "SignalLongName" SG_ 562 StrCustCurrStngVal "Steering Customization Current Setting Value";
BA_ "VNSigAllNodes" SG_ 562 StrCustCurrStngVal 1;
BA_ "SignalType" SG_ 562 DrvlnCustStngAvlbl "BLN";
BA_ "SignalLongName" SG_ 562 DrvlnCustStngAvlbl "Driveline Customization Setting Available";
BA_ "VNSigAllNodes" SG_ 562 DrvlnCustStngAvlbl 1;
BA_ "SignalType" SG_ 562 DrvMdCntrlState "UNM";
BA_ "SignalLongName" SG_ 562 DrvMdCntrlState "Driving Mode Control State";
BA_ "VNSigAllNodes" SG_ 562 DrvMdCntrlState 1;
BA_ "SignalType" SG_ 562 AWDPerfMdRq "ENM";
BA_ "SignalLongName" SG_ 562 AWDPerfMdRq "AWD Performance Mode Request";
BA_ "VNSigAllNodes" SG_ 562 AWDPerfMdRq 1;
BA_ "SignalType" SG_ 562 DrvlnCustCurrStngVal "ENM";
BA_ "SignalLongName" SG_ 562 DrvlnCustCurrStngVal "Driveline Customization Current Setting Value";
BA_ "VNSigAllNodes" SG_ 562 DrvlnCustCurrStngVal 1;
BA_ "SignalType" SG_ 893 AFLMnu3CstStAvl "BLN";
BA_ "SignalLongName" SG_ 893 AFLMnu3CstStAvl "Adaptive Forward Lighting Menu 3 Customization Setting Available";
BA_ "VNSigAllNodes" SG_ 893 AFLMnu3CstStAvl 1;
BA_ "SignalType" SG_ 893 AFLMnu2CstStAvl "BLN";
BA_ "SignalLongName" SG_ 893 AFLMnu2CstStAvl "Adaptive Forward Lighting Menu 2 Customization Setting Available";
BA_ "VNSigAllNodes" SG_ 893 AFLMnu2CstStAvl 1;
BA_ "SignalType" SG_ 893 AFLGPSMnu2CstStAvl "BLN";
BA_ "SignalLongName" SG_ 893 AFLGPSMnu2CstStAvl "Adaptive Forward Lighting With GPS Menu 2 Customization Setting Avail";
BA_ "VNSigAllNodes" SG_ 893 AFLGPSMnu2CstStAvl 1;
BA_ "SignalType" SG_ 893 AFLGPSCstStAvl "BLN";
BA_ "SignalLongName" SG_ 893 AFLGPSCstStAvl "Adaptive Forward Lighting With GPS Customization Setting Available";
BA_ "VNSigAllNodes" SG_ 893 AFLGPSCstStAvl 1;
BA_ "SignalType" SG_ 893 AFLGPSCstCrStVal "ENM";
BA_ "SignalLongName" SG_ 893 AFLGPSCstCrStVal "Adaptive Forward Lighting With GPS Customization Current Setting Value";
BA_ "VNSigAllNodes" SG_ 893 AFLGPSCstCrStVal 1;
BA_ "SignalType" SG_ 893 AFLCstStAvl "BLN";
BA_ "SignalLongName" SG_ 893 AFLCstStAvl "Adaptive Forward Lighting Customization Setting Available";
BA_ "VNSigAllNodes" SG_ 893 AFLCstStAvl 1;
BA_ "SignalType" SG_ 893 AFLCstCrStVal "ENM";
BA_ "SignalLongName" SG_ 893 AFLCstCrStVal "Adaptive Forward Lighting Customization Current Setting Value";
BA_ "VNSigAllNodes" SG_ 893 AFLCstCrStVal 1;
BA_ "SignalType" SG_ 892 AdpHgBmAsSnCsCrStVal "ENM";
BA_ "SignalLongName" SG_ 892 AdpHgBmAsSnCsCrStVal "Adaptive High Beam Assist With Sensitivity Customization Current Setting Value";
BA_ "VNSigAllNodes" SG_ 892 AdpHgBmAsSnCsCrStVal 1;
BA_ "SignalType" SG_ 892 AdpHgBmAsSnCsStAvl "BLN";
BA_ "SignalLongName" SG_ 892 AdpHgBmAsSnCsStAvl "Adaptive High Beam Assist With Sensitivity Customization Setting Available";
BA_ "VNSigAllNodes" SG_ 892 AdpHgBmAsSnCsStAvl 1;
BA_ "SignalType" SG_ 892 AdpHgBmAsCsCrStVal "ENM";
BA_ "SignalLongName" SG_ 892 AdpHgBmAsCsCrStVal "Adaptive High Beam Assist Customization Current Setting Value";
BA_ "VNSigAllNodes" SG_ 892 AdpHgBmAsCsCrStVal 1;
BA_ "SignalType" SG_ 892 AdpHgBmAsCsStAvl "BLN";
BA_ "SignalLongName" SG_ 892 AdpHgBmAsCsStAvl "Adaptive High Beam Assist Customization Setting Available";
BA_ "VNSigAllNodes" SG_ 892 AdpHgBmAsCsStAvl 1;
BA_ "SignalType" SG_ 892 AutHgBmAsCsCrStVal "ENM";
BA_ "SignalLongName" SG_ 892 AutHgBmAsCsCrStVal "Auto High Beam Assist Customization Current Setting Value";
BA_ "VNSigAllNodes" SG_ 892 AutHgBmAsCsCrStVal 1;
BA_ "SignalType" SG_ 892 AutHgBmAsSnCsStAvl "BLN";
BA_ "SignalLongName" SG_ 892 AutHgBmAsSnCsStAvl "Auto High Beam Assist With Sensitivity Customization Setting Available";
BA_ "VNSigAllNodes" SG_ 892 AutHgBmAsSnCsStAvl 1;
BA_ "SignalType" SG_ 892 AutHgBmAsSnCsCrStVa "ENM";
BA_ "SignalLongName" SG_ 892 AutHgBmAsSnCsCrStVa "Auto High Beam Assist With Sensitivity Customization Current Setting Value";
BA_ "VNSigAllNodes" SG_ 892 AutHgBmAsSnCsCrStVa 1;
BA_ "SignalType" SG_ 892 AutHgBmAsCsStAvl "BLN";
BA_ "SignalLongName" SG_ 892 AutHgBmAsCsStAvl "Auto High Beam Assist Customization Setting Available";
BA_ "VNSigAllNodes" SG_ 892 AutHgBmAsCsStAvl 1;
BA_ "SignalType" SG_ 386 AHAct "BLN";
BA_ "SignalLongName" SG_ 386 AHAct "Auto Hold Active";
BA_ "VNSigAllNodes" SG_ 386 AHAct 1;
BA_ "SignalType" SG_ 386 AHEnbld "BLN";
BA_ "SignalLongName" SG_ 386 AHEnbld "Auto Hold Enabled";
BA_ "VNSigAllNodes" SG_ 386 AHEnbld 1;
BA_ "SignalType" SG_ 386 ShfToPrkBfExtngIO "BLN";
BA_ "SignalLongName" SG_ 386 ShfToPrkBfExtngIO "Shift To Park Before Exiting Indication On";
BA_ "VNSigAllNodes" SG_ 386 ShfToPrkBfExtngIO 1;
BA_ "SignalType" SG_ 386 AHServcIO "BLN";
BA_ "SignalLongName" SG_ 386 AHServcIO "Auto Hold Service Indication On";
BA_ "VNSigAllNodes" SG_ 386 AHServcIO 1;
BA_ "SignalType" SG_ 386 AHAppBrkPedlIO "BLN";
BA_ "SignalLongName" SG_ 386 AHAppBrkPedlIO "Auto Hold Apply Brake Pedal Indication On";
BA_ "VNSigAllNodes" SG_ 386 AHAppBrkPedlIO 1;
BA_ "SignalType" SG_ 386 AHDisbldStbltIO "BLN";
BA_ "SignalLongName" SG_ 386 AHDisbldStbltIO "Auto Hold Disabled Seatbelt Indication On";
BA_ "VNSigAllNodes" SG_ 386 AHDisbldStbltIO 1;
BA_ "SignalType" SG_ 386 AHDisbldDrOpnIO "BLN";
BA_ "SignalLongName" SG_ 386 AHDisbldDrOpnIO "Auto Hold Disabled Door Open Indication On";
BA_ "VNSigAllNodes" SG_ 386 AHDisbldDrOpnIO 1;
BA_ "SignalType" SG_ 386 PMVSS_Disps "ENM";
BA_ "PacketOrder" SG_ 386 PMVSS_Disps 11;
BA_ "SignalLongName" SG_ 386 PMVSS_Disps "Performance Mode Visualization Screen Status : Displays";
BA_ "VNSigAllNodes" SG_ 386 PMVSS_Disps 1;
BA_ "SignalType" SG_ 386 PMVSS_Exhst "ENM";
BA_ "PacketOrder" SG_ 386 PMVSS_Exhst 10;
BA_ "SignalLongName" SG_ 386 PMVSS_Exhst "Performance Mode Visualization Screen Status : Exhaust";
BA_ "VNSigAllNodes" SG_ 386 PMVSS_Exhst 1;
BA_ "SignalType" SG_ 386 PMVSS_PsngrSeat "ENM";
BA_ "PacketOrder" SG_ 386 PMVSS_PsngrSeat 9;
BA_ "SignalLongName" SG_ 386 PMVSS_PsngrSeat "Performance Mode Visualization Screen Status : Passenger Seat";
BA_ "VNSigAllNodes" SG_ 386 PMVSS_PsngrSeat 1;
BA_ "SignalType" SG_ 386 PMVSS_DrvrSeat "ENM";
BA_ "PacketOrder" SG_ 386 PMVSS_DrvrSeat 8;
BA_ "SignalLongName" SG_ 386 PMVSS_DrvrSeat "Performance Mode Visualization Screen Status : Driver Seat";
BA_ "VNSigAllNodes" SG_ 386 PMVSS_DrvrSeat 1;
BA_ "SignalType" SG_ 386 PMVSS_AdptCrsCnt "ENM";
BA_ "PacketOrder" SG_ 386 PMVSS_AdptCrsCnt 7;
BA_ "SignalLongName" SG_ 386 PMVSS_AdptCrsCnt "Performance Mode Visualization Screen Status : Adaptive Cruise Control";
BA_ "VNSigAllNodes" SG_ 386 PMVSS_AdptCrsCnt 1;
BA_ "SignalType" SG_ 386 PMVSS_Drvln "ENM";
BA_ "PacketOrder" SG_ 386 PMVSS_Drvln 6;
BA_ "SignalLongName" SG_ 386 PMVSS_Drvln "Performance Mode Visualization Screen Status : Driveline";
BA_ "VNSigAllNodes" SG_ 386 PMVSS_Drvln 1;
BA_ "SignalType" SG_ 386 PMVSS_Susp "ENM";
BA_ "PacketOrder" SG_ 386 PMVSS_Susp 5;
BA_ "SignalLongName" SG_ 386 PMVSS_Susp "Performance Mode Visualization Screen Status : Suspension";
BA_ "VNSigAllNodes" SG_ 386 PMVSS_Susp 1;
BA_ "SignalType" SG_ 386 PMVSS_Strng "ENM";
BA_ "PacketOrder" SG_ 386 PMVSS_Strng 4;
BA_ "SignalLongName" SG_ 386 PMVSS_Strng "Performance Mode Visualization Screen Status : Steering";
BA_ "VNSigAllNodes" SG_ 386 PMVSS_Strng 1;
BA_ "SignalType" SG_ 386 PMVSS_Trans "ENM";
BA_ "PacketOrder" SG_ 386 PMVSS_Trans 3;
BA_ "SignalLongName" SG_ 386 PMVSS_Trans "Performance Mode Visualization Screen Status : Transmission";
BA_ "VNSigAllNodes" SG_ 386 PMVSS_Trans 1;
BA_ "SignalType" SG_ 386 PMVSS_Eng "ENM";
BA_ "PacketOrder" SG_ 386 PMVSS_Eng 2;
BA_ "SignalLongName" SG_ 386 PMVSS_Eng "Performance Mode Visualization Screen Status : Engine";
BA_ "VNSigAllNodes" SG_ 386 PMVSS_Eng 1;
BA_ "SignalType" SG_ 386 PMVSS_Snd "ENM";
BA_ "PacketOrder" SG_ 386 PMVSS_Snd 1;
BA_ "SignalLongName" SG_ 386 PMVSS_Snd "Performance Mode Visualization Screen Status : Sound";
BA_ "VNSigAllNodes" SG_ 386 PMVSS_Snd 1;
BA_ "SignalType" SG_ 386 AdptCruzCtrlStg "ENM";
BA_ "SignalLongName" SG_ 386 AdptCruzCtrlStg "Adaptive Cruise Control Setting";
BA_ "VNSigAllNodes" SG_ 386 AdptCruzCtrlStg 1;
BA_ "SignalType" SG_ 386 EnvIdRsp4 "UNM";
BA_ "SignalLongName" SG_ 386 EnvIdRsp4 "Environment Identification Response 4";
BA_ "VNSigAllNodes" SG_ 386 EnvIdRsp4 1;
BA_ "SignalType" SG_ 386 EnvIdRspSt4 "ENM";
BA_ "SignalLongName" SG_ 386 EnvIdRspSt4 "Environment Identification Response Status 4";
BA_ "VNSigAllNodes" SG_ 386 EnvIdRspSt4 1;
BA_ "VNSigSLHSSharedDiagnostic" SG_ 597 DgnInf 1;
BA_ "SignalType" SG_ 597 DgnInf "UNM";
BA_ "SignalLongName" SG_ 597 DgnInf "Diagnostic Information";
BA_ "VNSigAllNodes" SG_ 597 DgnInf 1;
BA_ "VNSigSLHSSharedDiagnostic" SG_ 1621 DgnInf 1;
BA_ "SignalType" SG_ 1621 DgnInf "UNM";
BA_ "SignalLongName" SG_ 1621 DgnInf "Diagnostic Information";
BA_ "VNSigAllNodes" SG_ 1621 DgnInf 1;
BA_ "SignalType" SG_ 532 RedntVSEActARC "UNM";
BA_ "SignalLongName" SG_ 532 RedntVSEActARC "Redundant Vehicle Stability Enhancement System Active Alive Rolling Count";
BA_ "VNSigAllNodes" SG_ 532 RedntVSEActARC 1;
BA_ "SignalType" SG_ 532 RedntVSEAct "BLN";
BA_ "SignalLongName" SG_ 532 RedntVSEAct "Redundant Vehicle Stability Enhancement System Active";
BA_ "VNSigAllNodes" SG_ 532 RedntVSEAct 1;
BA_ "SignalType" SG_ 532 AutoBrkngActARC "UNM";
BA_ "SignalLongName" SG_ 532 AutoBrkngActARC "Automatic Braking Active Alive Rolling Count";
BA_ "VNSigAllNodes" SG_ 532 AutoBrkngActARC 1;
BA_ "SignalType" SG_ 532 HilRlbkCtrlActIO "BLN";
BA_ "SignalLongName" SG_ 532 HilRlbkCtrlActIO "Hill Rollback Control Active Indiction On";
BA_ "VNSigAllNodes" SG_ 532 HilRlbkCtrlActIO 1;
BA_ "SignalType" SG_ 532 VehHldDrvrDsblActvFlg "BLN";
BA_ "SignalLongName" SG_ 532 VehHldDrvrDsblActvFlg "Vehicle Hold Driver Disable Active Flag";
BA_ "VNSigAllNodes" SG_ 532 VehHldDrvrDsblActvFlg 1;
BA_ "SignalType" SG_ 532 ABSAutnmsBrkReqPVal "UNM";
BA_ "SignalLongName" SG_ 532 ABSAutnmsBrkReqPVal "Antilock Brake System Autonomous Braking Request Protection Value";
BA_ "VNSigAllNodes" SG_ 532 ABSAutnmsBrkReqPVal 1;
BA_ "SignalType" SG_ 532 AutoBrkngAvlbl "BLN";
BA_ "SignalLongName" SG_ 532 AutoBrkngAvlbl "Automatic Braking Available";
BA_ "VNSigAllNodes" SG_ 532 AutoBrkngAvlbl 1;
BA_ "SignalType" SG_ 532 ABSAutnmsBrkReqARC "UNM";
BA_ "SignalLongName" SG_ 532 ABSAutnmsBrkReqARC "Antilock Brake System Autonomous Braking Request Alive Rolling Count";
BA_ "VNSigAllNodes" SG_ 532 ABSAutnmsBrkReqARC 1;
BA_ "SignalType" SG_ 532 ABSAutnmsBrkReq "BLN";
BA_ "SignalLongName" SG_ 532 ABSAutnmsBrkReq "Antilock Brake System Autonomous Braking Request";
BA_ "VNSigAllNodes" SG_ 532 ABSAutnmsBrkReq 1;
BA_ "SignalType" SG_ 532 ABSActvProtPVal "UNM";
BA_ "SignalLongName" SG_ 532 ABSActvProtPVal "Antilock Brake System Active Protected Protection Value";
BA_ "VNSigAllNodes" SG_ 532 ABSActvProtPVal 1;
BA_ "SignalType" SG_ 532 ABSActvProtARC "UNM";
BA_ "SignalLongName" SG_ 532 ABSActvProtARC "Antilock Brake System Active Protected Alive Rolling Count";
BA_ "VNSigAllNodes" SG_ 532 ABSActvProtARC 1;
BA_ "SignalType" SG_ 532 HlStrAssActIO "BLN";
BA_ "SignalLongName" SG_ 532 HlStrAssActIO "Hill Start Assist Active Indication On";
BA_ "VNSigAllNodes" SG_ 532 HlStrAssActIO 1;
BA_ "SignalType" SG_ 532 ABSActvProt "BLN";
BA_ "SignalLongName" SG_ 532 ABSActvProt "Antilock Brake System Active Protected";
BA_ "VNSigAllNodes" SG_ 532 ABSActvProt 1;
BA_ "SignalType" SG_ 532 BrkSysAutBrkFld "BLN";
BA_ "SignalLongName" SG_ 532 BrkSysAutBrkFld "Brake System Automatic Braking Failed";
BA_ "VNSigAllNodes" SG_ 532 BrkSysAutBrkFld 1;
BA_ "SignalType" SG_ 532 IntBrkAssPreFilReq "BLN";
BA_ "SignalLongName" SG_ 532 IntBrkAssPreFilReq "Inteligent Brake Assist Pre-Fil Request";
BA_ "VNSigAllNodes" SG_ 532 IntBrkAssPreFilReq 1;
BA_ "SignalType" SG_ 532 BrkSysMalFuncIndOn "BLN";
BA_ "SignalLongName" SG_ 532 BrkSysMalFuncIndOn "Brake System Malfunction Indication On";
BA_ "VNSigAllNodes" SG_ 532 BrkSysMalFuncIndOn 1;
BA_ "SignalType" SG_ 532 BrkPdDrvAPrsStaPVal "UNM";
BA_ "SignalLongName" SG_ 532 BrkPdDrvAPrsStaPVal "Brake Pedal Driver Applied Pressure Status Protection Value";
BA_ "VNSigAllNodes" SG_ 532 BrkPdDrvAPrsStaPVal 1;
BA_ "SignalType" SG_ 532 BPDAPS_BkPDrvApPV "ENM";
BA_ "PacketOrder" SG_ 532 BPDAPS_BkPDrvApPV 2;
BA_ "SignalLongName" SG_ 532 BPDAPS_BkPDrvApPV "Brake Pedal Driver Applied Pressure Status : Brake Pedal Driver Applied Pressure Validity";
BA_ "VNSigAllNodes" SG_ 532 BPDAPS_BkPDrvApPV 1;
BA_ "SignalType" SG_ 532 BPDAPS_BkPDrvApP "UNM";
BA_ "PacketOrder" SG_ 532 BPDAPS_BkPDrvApP 1;
BA_ "SignalLongName" SG_ 532 BPDAPS_BkPDrvApP "Brake Pedal Driver Applied Pressure Status : Brake Pedal Driver Applied Pressure";
BA_ "VNSigAllNodes" SG_ 532 BPDAPS_BkPDrvApP 1;
BA_ "SignalType" SG_ 532 BrkPdDrvAppPrsAlRC "UNM";
BA_ "SignalLongName" SG_ 532 BrkPdDrvAppPrsAlRC "Brake Pedal Driver Applied Pressure Alive Rolling Count";
BA_ "VNSigAllNodes" SG_ 532 BrkPdDrvAppPrsAlRC 1;
BA_ "SignalType" SG_ 532 BrkFldLvlLwV "ENM";
BA_ "SignalLongName" SG_ 532 BrkFldLvlLwV "Brake Fluid Level Low Validity";
BA_ "VNSigAllNodes" SG_ 532 BrkFldLvlLwV 1;
BA_ "SignalType" SG_ 532 AutoBrkngAct "BLN";
BA_ "SignalLongName" SG_ 532 AutoBrkngAct "Automatic Braking Active";
BA_ "VNSigAllNodes" SG_ 532 AutoBrkngAct 1;
BA_ "SignalType" SG_ 532 BrkFldLvlLw "BLN";
BA_ "SignalLongName" SG_ 532 BrkFldLvlLw "Brake Fluid Level Low";
BA_ "VNSigAllNodes" SG_ 532 BrkFldLvlLw 1;
BA_ "SignalType" SG_ 890 LtRtHnTrGPCsCrStVal "ENM";
BA_ "SignalLongName" SG_ 890 LtRtHnTrGPCsCrStVal "Left Right Hand Traffic With GPS Customization Current Setting Value";
BA_ "VNSigAllNodes" SG_ 890 LtRtHnTrGPCsCrStVal 1;
BA_ "SignalType" SG_ 890 LtRtHnTrGPSCsStAvl "BLN";
BA_ "SignalLongName" SG_ 890 LtRtHnTrGPSCsStAvl "Left Right Hand Traffic With GPS Customization Setting Available";
BA_ "VNSigAllNodes" SG_ 890 LtRtHnTrGPSCsStAvl 1;
BA_ "SignalType" SG_ 890 LtRtHnTrCstStVal "ENM";
BA_ "SignalLongName" SG_ 890 LtRtHnTrCstStVal "Left Right Hand Traffic Customization Current Setting Value";
BA_ "VNSigAllNodes" SG_ 890 LtRtHnTrCstStVal 1;
BA_ "SignalType" SG_ 890 LtRtHnTrCstStAvail "ENM";
BA_ "SignalLongName" SG_ 890 LtRtHnTrCstStAvail "Left Right Hand Traffic Customization Setting Available";
BA_ "VNSigAllNodes" SG_ 890 LtRtHnTrCstStAvail 1;
BA_ "VNSigSLHSSharedDiagnostic" SG_ 592 DgnInf 1;
BA_ "SignalType" SG_ 592 DgnInf "UNM";
BA_ "SignalLongName" SG_ 592 DgnInf "Diagnostic Information";
BA_ "VNSigAllNodes" SG_ 592 DgnInf 1;
BA_ "GenSigDeltaValue" SG_ 1365 DgnInf_HS555 1;
BA_ "VNSigSLHSSharedDiagnostic" SG_ 1365 DgnInf_HS555 1;
BA_ "SignalType" SG_ 1365 DgnInf_HS555 "UNM";
BA_ "SignalLongName" SG_ 1365 DgnInf_HS555 "Diagnostic Information HS555";
BA_ "VNSigAllNodes" SG_ 1365 DgnInf_HS555 1;
BA_ "VNSigAllNodes" SG_ 328 StrAsstRdcdLvl3IO 1;
BA_ "SignalLongName" SG_ 328 StrAsstRdcdLvl3IO "Steering Assist Reduced Level 3 Indication On";
BA_ "SignalType" SG_ 328 StrAsstRdcdLvl3IO "BLN";
BA_ "VNSigAllNodes" SG_ 328 StrAsstRdcdLvl2IO 1;
BA_ "SignalLongName" SG_ 328 StrAsstRdcdLvl2IO "Steering Assist Reduced Level 2 Indication On";
BA_ "GenSigSendType" SG_ 328 StrngAsstRdcdIO 10;
BA_ "SignalType" SG_ 328 StrngAsstRdcdIO "BLN";
BA_ "SignalLongName" SG_ 328 StrngAsstRdcdIO "Steering Assist Reduced Indication On";
BA_ "VNSigAllNodes" SG_ 328 StrngAsstRdcdIO 1;
BA_ "GenSigSendType" SG_ 328 PwrStrIO 10;
BA_ "SignalType" SG_ 328 PwrStrIO "BLN";
BA_ "SignalLongName" SG_ 328 PwrStrIO "Power Steering Indication On";
BA_ "VNSigAllNodes" SG_ 328 PwrStrIO 1;
BA_ "SignalType" SG_ 560 ElecPrkBrkCmdProt "UNM";
BA_ "SignalLongName" SG_ 560 ElecPrkBrkCmdProt "Electric Park Brake Command Protection";
BA_ "VNSigAllNodes" SG_ 560 ElecPrkBrkCmdProt 1;
BA_ "SignalType" SG_ 560 ElecPrkBrkSwStatV "ENM";
BA_ "SignalLongName" SG_ 560 ElecPrkBrkSwStatV "Electric Park Brake Switch Status Validity";
BA_ "VNSigAllNodes" SG_ 560 ElecPrkBrkSwStatV 1;
BA_ "SignalType" SG_ 560 ElecPrkBrkCmdARC "UNM";
BA_ "SignalLongName" SG_ 560 ElecPrkBrkCmdARC "Electric Park Brake Command Alive Rolling Count";
BA_ "VNSigAllNodes" SG_ 560 ElecPrkBrkCmdARC 1;
BA_ "SignalType" SG_ 560 ElecPrkBrkSwStat "ENM";
BA_ "SignalLongName" SG_ 560 ElecPrkBrkSwStat "Electric Park Brake Switch Status";
BA_ "VNSigAllNodes" SG_ 560 ElecPrkBrkSwStat 1;
BA_ "VNSigSLHS_VNReq" SG_ 560 AllNodesVNA 1;
BA_ "SignalType" SG_ 560 AllNodesVNA "ENM";
BA_ "SignalLongName" SG_ 560 AllNodesVNA "All Nodes Virtual Network Activation";
BA_ "VNSigAllNodes" SG_ 560 AllNodesVNA 1;
BA_ "SignalType" SG_ 560 StpOnBrkToRelPBIndOn "BLN";
BA_ "SignalLongName" SG_ 560 StpOnBrkToRelPBIndOn "Step On Brake To Release Park Brake Indication On";
BA_ "VNSigAllNodes" SG_ 560 StpOnBrkToRelPBIndOn 1;
BA_ "SignalType" SG_ 560 EPBC_EPBAccRq "SNM";
BA_ "PacketOrder" SG_ 560 EPBC_EPBAccRq 2;
BA_ "SignalLongName" SG_ 560 EPBC_EPBAccRq "Electric Park Brake Command : Electric Park Brake Acceleration Requested";
BA_ "VNSigAllNodes" SG_ 560 EPBC_EPBAccRq 1;
BA_ "SignalType" SG_ 560 EPBC_EPBrkAutBrkRq "BLN";
BA_ "PacketOrder" SG_ 560 EPBC_EPBrkAutBrkRq 1;
BA_ "SignalLongName" SG_ 560 EPBC_EPBrkAutBrkRq "Electric Park Brake Command : Electric Park Brake Automatic Braking Requested";
BA_ "VNSigAllNodes" SG_ 560 EPBC_EPBrkAutBrkRq 1;
BA_ "SignalType" SG_ 560 EPBSysDspMsgReq "ENM";
BA_ "SignalLongName" SG_ 560 EPBSysDspMsgReq "Electric Park Brake System Display Message Request";
BA_ "VNSigAllNodes" SG_ 560 EPBSysDspMsgReq 1;
BA_ "SignalType" SG_ 560 EPBSysAudWarnReq "ENM";
BA_ "SignalLongName" SG_ 560 EPBSysAudWarnReq "Electric Park Brake System Audible Warning Request";
BA_ "VNSigAllNodes" SG_ 560 EPBSysAudWarnReq 1;
BA_ "SignalType" SG_ 560 ElecPrkBrkStat "ENM";
BA_ "SignalLongName" SG_ 560 ElecPrkBrkStat "Electric Park Brake Status";
BA_ "VNSigAllNodes" SG_ 560 ElecPrkBrkStat 1;
BA_ "SignalType" SG_ 560 EPBCrsCanRq "BLN";
BA_ "SignalLongName" SG_ 560 EPBCrsCanRq "Electric Park Brake Cruise Control Cancel Requested";
BA_ "VNSigAllNodes" SG_ 560 EPBCrsCanRq 1;
BA_ "SignalType" SG_ 560 EPBSysStatIndReq "ENM";
BA_ "SignalLongName" SG_ 560 EPBSysStatIndReq "Electric Park Brake System Status Indication Request";
BA_ "VNSigAllNodes" SG_ 560 EPBSysStatIndReq 1;
BA_ "SignalType" SG_ 560 EPBSysWrnIndReq "ENM";
BA_ "SignalLongName" SG_ 560 EPBSysWrnIndReq "Electric Park Brake System Warning Indication Request";
BA_ "VNSigAllNodes" SG_ 560 EPBSysWrnIndReq 1;
BA_ "SignalType" SG_ 560 EPBSysBrkLtsReq "BLN";
BA_ "SignalLongName" SG_ 560 EPBSysBrkLtsReq "Electric Park Brake System Brake Lights Requested";
BA_ "VNSigAllNodes" SG_ 560 EPBSysBrkLtsReq 1;
BA_ "SignalType" SG_ 451 HillDscntCtrlSwStatPVal "UNM";
BA_ "SignalLongName" SG_ 451 HillDscntCtrlSwStatPVal "Hill Descent Control Switch Status Protection Value";
BA_ "VNSigAllNodes" SG_ 451 HillDscntCtrlSwStatPVal 1;
BA_ "SignalType" SG_ 451 HillDscntCtrlSwStatARC "UNM";
BA_ "SignalLongName" SG_ 451 HillDscntCtrlSwStatARC "Hill Descent Control Switch Status Alive Rolling Count";
BA_ "VNSigAllNodes" SG_ 451 HillDscntCtrlSwStatARC 1;
BA_ "SignalType" SG_ 451 HillDscntCtrlSwStat "ENM";
BA_ "SignalLongName" SG_ 451 HillDscntCtrlSwStat "Hill Descent Control Switch Status";
BA_ "VNSigAllNodes" SG_ 451 HillDscntCtrlSwStat 1;
BA_ "SignalType" SG_ 451 GlwPlgCrnkDelAct "BLN";
BA_ "SignalLongName" SG_ 451 GlwPlgCrnkDelAct "Glow Plugs Crank Delay Active";
BA_ "VNSigAllNodes" SG_ 451 GlwPlgCrnkDelAct 1;
BA_ "SignalType" SG_ 451 AuxHtrAlwd "BLN";
BA_ "SignalLongName" SG_ 451 AuxHtrAlwd "Auxiliary Heater Allowed";
BA_ "VNSigAllNodes" SG_ 451 AuxHtrAlwd 1;
BA_ "SignalType" SG_ 451 AppCltchAutSrtIO "BLN";
BA_ "SignalLongName" SG_ 451 AppCltchAutSrtIO "Apply Clutch For Automatic Start Indication On";
BA_ "VNSigAllNodes" SG_ 451 AppCltchAutSrtIO 1;
BA_ "SignalType" SG_ 451 AccPosV "ENM";
BA_ "SignalLongName" SG_ 451 AccPosV "Accelerator Effective Position Validity";
BA_ "VNSigAllNodes" SG_ 451 AccPosV 1;
BA_ "SignalType" SG_ 451 AccPos "UNM";
BA_ "SignalLongName" SG_ 451 AccPos "Accelerator Effective Position";
BA_ "VNSigAllNodes" SG_ 451 AccPos 1;
BA_ "SignalType" SG_ 451 FuelFltRmnLf "UNM";
BA_ "SignalLongName" SG_ 451 FuelFltRmnLf "Fuel Filter Remaining Life";
BA_ "VNSigAllNodes" SG_ 451 FuelFltRmnLf 1;
BA_ "SignalType" SG_ 451 EngTrqRdFlrSt "ENM";
BA_ "SignalLongName" SG_ 451 EngTrqRdFlrSt "Engine Torque Reduction Failure Status";
BA_ "VNSigAllNodes" SG_ 451 EngTrqRdFlrSt 1;
BA_ "SignalType" SG_ 451 EngTrqDrRqdExtRngV "ENM";
BA_ "SignalLongName" SG_ 451 EngTrqDrRqdExtRngV "Engine Torque Driver Requested Extended Range Validity";
BA_ "VNSigAllNodes" SG_ 451 EngTrqDrRqdExtRngV 1;
BA_ "SignalType" SG_ 451 EngTrqDrRqdExtRng "UNM";
BA_ "SignalLongName" SG_ 451 EngTrqDrRqdExtRng "Engine Torque Driver Requested Extended Range";
BA_ "GenSigStartValue" SG_ 451 EngTrqDrRqdExtRng 1696;
BA_ "VNSigAllNodes" SG_ 451 EngTrqDrRqdExtRng 1;
BA_ "SignalType" SG_ 451 EngTrqActExtRngV "ENM";
BA_ "SignalLongName" SG_ 451 EngTrqActExtRngV "Engine Torque Actual Extended Range Validity";
BA_ "VNSigAllNodes" SG_ 451 EngTrqActExtRngV 1;
BA_ "SignalType" SG_ 451 EngTrqActExtRng "UNM";
BA_ "SignalLongName" SG_ 451 EngTrqActExtRng "Engine Torque Actual Extended Range";
BA_ "GenSigStartValue" SG_ 451 EngTrqActExtRng 1696;
BA_ "VNSigAllNodes" SG_ 451 EngTrqActExtRng 1;
BA_ "SignalType" SG_ 801 WhlBdySnsHmPosLrnd "BLN";
BA_ "SignalLongName" SG_ 801 WhlBdySnsHmPosLrnd "Wheel to Body Sensors Home Position Learned";
BA_ "VNSigAllNodes" SG_ 801 WhlBdySnsHmPosLrnd 1;
BA_ "SignalType" SG_ 801 WBRP_ARC "UNM";
BA_ "PacketOrder" SG_ 801 WBRP_ARC 2;
BA_ "SignalLongName" SG_ 801 WBRP_ARC "Wheel to Body Relative Position : Alive Rolling Count";
BA_ "VNSigAllNodes" SG_ 801 WBRP_ARC 1;
BA_ "SignalType" SG_ 801 WBRP_Tmestmp "UNM";
BA_ "PacketOrder" SG_ 801 WBRP_Tmestmp 1;
BA_ "SignalLongName" SG_ 801 WBRP_Tmestmp "Wheel to Body Relative Position : Timestamp";
BA_ "VNSigAllNodes" SG_ 801 WBRP_Tmestmp 1;
BA_ "SignalType" SG_ 801 WBRP_RtFrtV "ENM";
BA_ "PacketOrder" SG_ 801 WBRP_RtFrtV 5;
BA_ "SignalLongName" SG_ 801 WBRP_RtFrtV "Wheel to Body Relative Position : Right Front Validity";
BA_ "VNSigAllNodes" SG_ 801 WBRP_RtFrtV 1;
BA_ "SignalType" SG_ 801 WBRP_RtFrt "SNM";
BA_ "PacketOrder" SG_ 801 WBRP_RtFrt 8;
BA_ "SignalLongName" SG_ 801 WBRP_RtFrt "Wheel to Body Relative Position : Right Front";
BA_ "VNSigAllNodes" SG_ 801 WBRP_RtFrt 1;
BA_ "SignalType" SG_ 801 WBRP_RtRrV "ENM";
BA_ "PacketOrder" SG_ 801 WBRP_RtRrV 6;
BA_ "SignalLongName" SG_ 801 WBRP_RtRrV "Wheel to Body Relative Position : Right Rear Validity";
BA_ "VNSigAllNodes" SG_ 801 WBRP_RtRrV 1;
BA_ "SignalType" SG_ 801 WBRP_RtRr "SNM";
BA_ "PacketOrder" SG_ 801 WBRP_RtRr 10;
BA_ "SignalLongName" SG_ 801 WBRP_RtRr "Wheel to Body Relative Position : Right Rear";
BA_ "VNSigAllNodes" SG_ 801 WBRP_RtRr 1;
BA_ "SignalType" SG_ 801 WBRP_LftRrV "ENM";
BA_ "PacketOrder" SG_ 801 WBRP_LftRrV 4;
BA_ "SignalLongName" SG_ 801 WBRP_LftRrV "Wheel to Body Relative Position : Left Rear Validity";
BA_ "VNSigAllNodes" SG_ 801 WBRP_LftRrV 1;
BA_ "SignalType" SG_ 801 WBRP_LftRr "SNM";
BA_ "PacketOrder" SG_ 801 WBRP_LftRr 9;
BA_ "SignalLongName" SG_ 801 WBRP_LftRr "Wheel to Body Relative Position : Left Rear";
BA_ "VNSigAllNodes" SG_ 801 WBRP_LftRr 1;
BA_ "SignalType" SG_ 801 WBRP_LftFrtV "ENM";
BA_ "PacketOrder" SG_ 801 WBRP_LftFrtV 3;
BA_ "SignalLongName" SG_ 801 WBRP_LftFrtV "Wheel to Body Relative Position : Left Front Validity";
BA_ "VNSigAllNodes" SG_ 801 WBRP_LftFrtV 1;
BA_ "SignalType" SG_ 801 WBRP_LftFrt "SNM";
BA_ "PacketOrder" SG_ 801 WBRP_LftFrt 7;
BA_ "SignalLongName" SG_ 801 WBRP_LftFrt "Wheel to Body Relative Position : Left Front";
BA_ "VNSigAllNodes" SG_ 801 WBRP_LftFrt 1;
BA_ "GenSigSendType" SG_ 320 Ky_IdDevPrgmAuthReq 10;
BA_ "SignalType" SG_ 320 Ky_IdDevPrgmAuthReq "BLN";
BA_ "SignalLongName" SG_ 320 Ky_IdDevPrgmAuthReq "Key / Identification Device Programming Authentication Requested";
BA_ "VNSigAllNodes" SG_ 320 Ky_IdDevPrgmAuthReq 1;
BA_ "GenSigSendType" SG_ 320 ClmnLckStatV 10;
BA_ "SignalType" SG_ 320 ClmnLckStatV "ENM";
BA_ "SignalLongName" SG_ 320 ClmnLckStatV "Column Lock Status Validity";
BA_ "VNSigAllNodes" SG_ 320 ClmnLckStatV 1;
BA_ "GenSigSendType" SG_ 320 ClmnLckStat 10;
BA_ "SignalType" SG_ 320 ClmnLckStat "ENM";
BA_ "SignalLongName" SG_ 320 ClmnLckStat "Column Lock Status";
BA_ "VNSigAllNodes" SG_ 320 ClmnLckStat 1;
BA_ "GenSigSendType" SG_ 320 AutoBmSlctAllwd 10;
BA_ "SignalType" SG_ 320 AutoBmSlctAllwd "BLN";
BA_ "SignalLongName" SG_ 320 AutoBmSlctAllwd "Automatic Beam Select Allowed";
BA_ "VNSigAllNodes" SG_ 320 AutoBmSlctAllwd 1;
BA_ "GenSigSendType" SG_ 320 BrkLtsAtv 10;
BA_ "SignalType" SG_ 320 BrkLtsAtv "BLN";
BA_ "SignalLongName" SG_ 320 BrkLtsAtv "Brake Lights Active";
BA_ "VNSigAllNodes" SG_ 320 BrkLtsAtv 1;
BA_ "GenSigSendType" SG_ 320 TrnSwAct 10;
BA_ "SignalType" SG_ 320 TrnSwAct "ENM";
BA_ "SignalLongName" SG_ 320 TrnSwAct "Turn Switch Activation";
BA_ "VNSigAllNodes" SG_ 320 TrnSwAct 1;
BA_ "GenSigSendType" SG_ 320 RrFogLmpsAct 10;
BA_ "SignalType" SG_ 320 RrFogLmpsAct "BLN";
BA_ "SignalLongName" SG_ 320 RrFogLmpsAct "Rear Fog Lamps Active";
BA_ "VNSigAllNodes" SG_ 320 RrFogLmpsAct 1;
BA_ "GenSigSendType" SG_ 320 OtsdAmbtLtLvlStatV 10;
BA_ "SignalType" SG_ 320 OtsdAmbtLtLvlStatV "ENM";
BA_ "SignalLongName" SG_ 320 OtsdAmbtLtLvlStatV "Outside Ambient Light Level Status Validity";
BA_ "VNSigAllNodes" SG_ 320 OtsdAmbtLtLvlStatV 1;
BA_ "GenSigSendType" SG_ 320 OtsdAmbtLtLvlStat 10;
BA_ "SignalType" SG_ 320 OtsdAmbtLtLvlStat "ENM";
BA_ "SignalLongName" SG_ 320 OtsdAmbtLtLvlStat "Outside Ambient Light Level Status";
BA_ "VNSigAllNodes" SG_ 320 OtsdAmbtLtLvlStat 1;
BA_ "GenSigSendType" SG_ 320 MainLghtSw 10;
BA_ "SignalType" SG_ 320 MainLghtSw "ENM";
BA_ "SignalLongName" SG_ 320 MainLghtSw "Main Light Switch";
BA_ "VNSigAllNodes" SG_ 320 MainLghtSw 1;
BA_ "GenSigSendType" SG_ 320 LowBmAct 10;
BA_ "SignalType" SG_ 320 LowBmAct "BLN";
BA_ "SignalLongName" SG_ 320 LowBmAct "Low Beam Active";
BA_ "VNSigAllNodes" SG_ 320 LowBmAct 1;
BA_ "GenSigSendType" SG_ 320 HighBmAct 10;
BA_ "SignalType" SG_ 320 HighBmAct "BLN";
BA_ "SignalLongName" SG_ 320 HighBmAct "High Beam Active";
BA_ "VNSigAllNodes" SG_ 320 HighBmAct 1;
BA_ "GenSigSendType" SG_ 320 HdlmpBmSelectStat 10;
BA_ "SignalType" SG_ 320 HdlmpBmSelectStat "ENM";
BA_ "SignalLongName" SG_ 320 HdlmpBmSelectStat "Headlamp Beam Select Status";
BA_ "VNSigAllNodes" SG_ 320 HdlmpBmSelectStat 1;
BA_ "GenSigSendType" SG_ 320 FlToPsSwAtv 10;
BA_ "SignalType" SG_ 320 FlToPsSwAtv "BLN";
BA_ "SignalLongName" SG_ 320 FlToPsSwAtv "Flash To Pass Switch Active";
BA_ "VNSigAllNodes" SG_ 320 FlToPsSwAtv 1;
BA_ "GenSigSendType" SG_ 320 AdvFrntLghtSysEnbld 10;
BA_ "SignalType" SG_ 320 AdvFrntLghtSysEnbld "BLN";
BA_ "SignalLongName" SG_ 320 AdvFrntLghtSysEnbld "Advanced Front Lighting System Enabled";
BA_ "VNSigAllNodes" SG_ 320 AdvFrntLghtSysEnbld 1;
BA_ "GenSigSendType" SG_ 320 FrFogLmpsAct 10;
BA_ "SignalType" SG_ 320 FrFogLmpsAct "BLN";
BA_ "SignalLongName" SG_ 320 FrFogLmpsAct "Front Fog Lamps Active";
BA_ "VNSigAllNodes" SG_ 320 FrFogLmpsAct 1;
BA_ "GenSigSendType" SG_ 320 AutLghtCtrl 10;
BA_ "SignalType" SG_ 320 AutLghtCtrl "BLN";
BA_ "SignalLongName" SG_ 320 AutLghtCtrl "Auto Light Control";
BA_ "VNSigAllNodes" SG_ 320 AutLghtCtrl 1;
BA_ "SignalType" SG_ 957 RdctHtrCStat "ENM";
BA_ "SignalLongName" SG_ 957 RdctHtrCStat "Reductant Heater C Status";
BA_ "VNSigAllNodes" SG_ 957 RdctHtrCStat 1;
BA_ "SignalType" SG_ 957 RdctHtrBStat "ENM";
BA_ "SignalLongName" SG_ 957 RdctHtrBStat "Reductant Heater B Status";
BA_ "VNSigAllNodes" SG_ 957 RdctHtrBStat 1;
BA_ "SignalType" SG_ 957 RdctHtrAStat "ENM";
BA_ "SignalLongName" SG_ 957 RdctHtrAStat "Reductant Heater A Status";
BA_ "VNSigAllNodes" SG_ 957 RdctHtrAStat 1;
BA_ "SignalType" SG_ 957 GPCMDS2_DTCStatus "ENM";
BA_ "PacketOrder" SG_ 957 GPCMDS2_DTCStatus 2;
BA_ "SignalLongName" SG_ 957 GPCMDS2_DTCStatus "Glow Plug Control Module Diagnostic Status 2 : Diagnostic Trouble Code Status";
BA_ "VNSigAllNodes" SG_ 957 GPCMDS2_DTCStatus 1;
BA_ "SignalType" SG_ 957 GPCMDS2_DTCIndex "UNM";
BA_ "PacketOrder" SG_ 957 GPCMDS2_DTCIndex 1;
BA_ "SignalLongName" SG_ 957 GPCMDS2_DTCIndex "Glow Plug Control Module Diagnostic Status 2 : Diagnostic Trouble Code Index";
BA_ "VNSigAllNodes" SG_ 957 GPCMDS2_DTCIndex 1;
BA_ "SignalType" SG_ 957 IntAirHtrPwrConsmp "UNM";
BA_ "SignalLongName" SG_ 957 IntAirHtrPwrConsmp "Intake Air Heater Power Consumption";
BA_ "VNSigAllNodes" SG_ 957 IntAirHtrPwrConsmp 1;
BA_ "SignalType" SG_ 957 IntAirHtrPwrConsmpV "ENM";
BA_ "SignalLongName" SG_ 957 IntAirHtrPwrConsmpV "Intake Air Heater Power Consumption Validity";
BA_ "VNSigAllNodes" SG_ 957 IntAirHtrPwrConsmpV 1;
BA_ "SignalType" SG_ 957 DslGlwPlgMdOvTmOD "BLN";
BA_ "SignalLongName" SG_ 957 DslGlwPlgMdOvTmOD "Glow Plug Control Module Over Temperature Outputs Disabled";
BA_ "VNSigAllNodes" SG_ 957 DslGlwPlgMdOvTmOD 1;
BA_ "SignalType" SG_ 957 IQAI_DataByte "UNM";
BA_ "PacketOrder" SG_ 957 IQAI_DataByte 4;
BA_ "SignalLongName" SG_ 957 IQAI_DataByte "Injector Quantity Adjustment Information : Data Byte";
BA_ "VNSigAllNodes" SG_ 957 IQAI_DataByte 1;
BA_ "SignalType" SG_ 957 IQAI_DataSeqNmbr "UNM";
BA_ "PacketOrder" SG_ 957 IQAI_DataSeqNmbr 3;
BA_ "SignalLongName" SG_ 957 IQAI_DataSeqNmbr "Injector Quantity Adjustment Information : Data Sequence Number";
BA_ "VNSigAllNodes" SG_ 957 IQAI_DataSeqNmbr 1;
BA_ "GenSigStartValue" SG_ 957 IQAI_InjIdInd 1;
BA_ "SignalType" SG_ 957 IQAI_InjIdInd "ENM";
BA_ "PacketOrder" SG_ 957 IQAI_InjIdInd 2;
BA_ "SignalLongName" SG_ 957 IQAI_InjIdInd "Injector Quantity Adjustment Information : Injector Identification Index";
BA_ "VNSigAllNodes" SG_ 957 IQAI_InjIdInd 1;
BA_ "SignalType" SG_ 957 IQAI_DataStat "ENM";
BA_ "PacketOrder" SG_ 957 IQAI_DataStat 1;
BA_ "SignalLongName" SG_ 957 IQAI_DataStat "Injector Quantity Adjustment Information : Data Status";
BA_ "VNSigAllNodes" SG_ 957 IQAI_DataStat 1;
BA_ "SignalType" SG_ 957 IntAirHtrTempSensVoltV "ENM";
BA_ "SignalLongName" SG_ 957 IntAirHtrTempSensVoltV "Intake Air Heater Temperature Sensor Voltage Validity";
BA_ "VNSigAllNodes" SG_ 957 IntAirHtrTempSensVoltV 1;
BA_ "SignalType" SG_ 957 IntAirHtrTempSensVolt "UNM";
BA_ "SignalLongName" SG_ 957 IntAirHtrTempSensVolt "Intake Air Heater Temperature Sensor Voltage";
BA_ "VNSigAllNodes" SG_ 957 IntAirHtrTempSensVolt 1;
BA_ "SignalType" SG_ 957 IntAirHtrSupVoltV "ENM";
BA_ "SignalLongName" SG_ 957 IntAirHtrSupVoltV "Intake Air Heater Supply Voltage Validity";
BA_ "VNSigAllNodes" SG_ 957 IntAirHtrSupVoltV 1;
BA_ "SignalType" SG_ 957 IntAirHtrSupVolt "UNM";
BA_ "SignalLongName" SG_ 957 IntAirHtrSupVolt "Intake Air Heater Supply Voltage";
BA_ "VNSigAllNodes" SG_ 957 IntAirHtrSupVolt 1;
BA_ "SignalType" SG_ 957 GPCMDS_DTCStatus "ENM";
BA_ "PacketOrder" SG_ 957 GPCMDS_DTCStatus 2;
BA_ "SignalLongName" SG_ 957 GPCMDS_DTCStatus "Glow Plug Control Module Diagnostic Status : Diagnostic Trouble Code Status";
BA_ "VNSigAllNodes" SG_ 957 GPCMDS_DTCStatus 1;
BA_ "SignalType" SG_ 957 GPCMDS_DTCIndex "UNM";
BA_ "PacketOrder" SG_ 957 GPCMDS_DTCIndex 1;
BA_ "SignalLongName" SG_ 957 GPCMDS_DTCIndex "Glow Plug Control Module Diagnostic Status : Diagnostic Trouble Code Index";
BA_ "VNSigAllNodes" SG_ 957 GPCMDS_DTCIndex 1;
BA_ "VNSigSLHSSharedDiagnostic" SG_ 1364 DgnInf_HS554 1;
BA_ "SignalType" SG_ 1364 DgnInf_HS554 "UNM";
BA_ "SignalLongName" SG_ 1364 DgnInf_HS554 "Diagnostic Information HS554";
BA_ "VNSigAllNodes" SG_ 1364 DgnInf_HS554 1;
BA_ "GenSigDeltaValue" SG_ 2041 PCUInfo_7F9 1;
BA_ "GenSigSendType" SG_ 2041 PCUInfo_7F9 12;
BA_ "SignalType" SG_ 2041 PCUInfo_7F9 "UNM";
BA_ "SignalLongName" SG_ 2041 PCUInfo_7F9 "Pyrotechnical Control Unit Information 7F9";
BA_ "VNSigAllNodes" SG_ 2041 PCUInfo_7F9 1;
BA_ "SignalType" SG_ 1904 DTCI_WrnIndRqdSt_770 "BLN";
BA_ "PacketOrder" SG_ 1904 DTCI_WrnIndRqdSt_770 12;
BA_ "SignalLongName" SG_ 1904 DTCI_WrnIndRqdSt_770 "Diagnostic Trouble Code Information Extended 770 : Warning Indicator Requested Status";
BA_ "VNSigAllNodes" SG_ 1904 DTCI_WrnIndRqdSt_770 1;
BA_ "SignalType" SG_ 1904 DTCIUnused7_770 "BLN";
BA_ "PacketOrder" SG_ 1904 DTCIUnused7_770 1;
BA_ "SignalLongName" SG_ 1904 DTCIUnused7_770 "Diagnostic Trouble Code Information Extended 770 : Unused 7";
BA_ "VNSigAllNodes" SG_ 1904 DTCIUnused7_770 1;
BA_ "SignalType" SG_ 1904 DTCIUnused6_770 "BLN";
BA_ "PacketOrder" SG_ 1904 DTCIUnused6_770 2;
BA_ "SignalLongName" SG_ 1904 DTCIUnused6_770 "Diagnostic Trouble Code Information Extended 770 : Unused 6";
BA_ "VNSigAllNodes" SG_ 1904 DTCIUnused6_770 1;
BA_ "SignalType" SG_ 1904 DTCIUnused5_770 "BLN";
BA_ "PacketOrder" SG_ 1904 DTCIUnused5_770 3;
BA_ "SignalLongName" SG_ 1904 DTCIUnused5_770 "Diagnostic Trouble Code Information Extended 770 : Unused 5";
BA_ "VNSigAllNodes" SG_ 1904 DTCIUnused5_770 1;
BA_ "SignalType" SG_ 1904 DTCIUnused4_770 "BLN";
BA_ "PacketOrder" SG_ 1904 DTCIUnused4_770 4;
BA_ "SignalLongName" SG_ 1904 DTCIUnused4_770 "Diagnostic Trouble Code Information Extended 770 : Unused 4";
BA_ "VNSigAllNodes" SG_ 1904 DTCIUnused4_770 1;
BA_ "SignalType" SG_ 1904 DTCIUnused3_770 "BLN";
BA_ "PacketOrder" SG_ 1904 DTCIUnused3_770 5;
BA_ "SignalLongName" SG_ 1904 DTCIUnused3_770 "Diagnostic Trouble Code Information Extended 770 : Unused 3";
BA_ "VNSigAllNodes" SG_ 1904 DTCIUnused3_770 1;
BA_ "SignalType" SG_ 1904 DTCIUnused2_770 "BLN";
BA_ "PacketOrder" SG_ 1904 DTCIUnused2_770 6;
BA_ "SignalLongName" SG_ 1904 DTCIUnused2_770 "Diagnostic Trouble Code Information Extended 770 : Unused 2";
BA_ "VNSigAllNodes" SG_ 1904 DTCIUnused2_770 1;
BA_ "SignalType" SG_ 1904 DTCIUnused1_770 "BLN";
BA_ "PacketOrder" SG_ 1904 DTCIUnused1_770 7;
BA_ "SignalLongName" SG_ 1904 DTCIUnused1_770 "Diagnostic Trouble Code Information Extended 770 : Unused 1";
BA_ "VNSigAllNodes" SG_ 1904 DTCIUnused1_770 1;
BA_ "SignalType" SG_ 1904 DTCI_TstNPsdPwrUpSt_770 "BLN";
BA_ "PacketOrder" SG_ 1904 DTCI_TstNPsdPwrUpSt_770 14;
BA_ "SignalLongName" SG_ 1904 DTCI_TstNPsdPwrUpSt_770 "Diagnostic Trouble Code Information Extended 770 : Test Not Passed Since Power Up Status";
BA_ "VNSigAllNodes" SG_ 1904 DTCI_TstNPsdPwrUpSt_770 1;
BA_ "SignalType" SG_ 1904 DTCI_TstNPsdCdClrdSt_770 "BLN";
BA_ "PacketOrder" SG_ 1904 DTCI_TstNPsdCdClrdSt_770 17;
BA_ "SignalLongName" SG_ 1904 DTCI_TstNPsdCdClrdSt_770 "Diagnostic Trouble Code Information Extended 770 : Test Not Passed Since Code Cleared Status";
BA_ "VNSigAllNodes" SG_ 1904 DTCI_TstNPsdCdClrdSt_770 1;
BA_ "SignalType" SG_ 1904 DTCI_TstFldPwrUpSt_770 "BLN";
BA_ "PacketOrder" SG_ 1904 DTCI_TstFldPwrUpSt_770 13;
BA_ "SignalLongName" SG_ 1904 DTCI_TstFldPwrUpSt_770 "Diagnostic Trouble Code Information Extended 770 : Test Failed Since Power Up Status";
BA_ "VNSigAllNodes" SG_ 1904 DTCI_TstFldPwrUpSt_770 1;
BA_ "SignalType" SG_ 1904 DTCI_TstFldCdClrdStat_770 "BLN";
BA_ "PacketOrder" SG_ 1904 DTCI_TstFldCdClrdStat_770 16;
BA_ "SignalLongName" SG_ 1904 DTCI_TstFldCdClrdStat_770 "Diagnostic Trouble Code Information Extended 770 : Test Failed Since Code Cleared Status";
BA_ "VNSigAllNodes" SG_ 1904 DTCI_TstFldCdClrdStat_770 1;
BA_ "SignalType" SG_ 1904 DTCI_HistStat_770 "BLN";
BA_ "PacketOrder" SG_ 1904 DTCI_HistStat_770 15;
BA_ "SignalLongName" SG_ 1904 DTCI_HistStat_770 "Diagnostic Trouble Code Information Extended 770 : History Status";
BA_ "VNSigAllNodes" SG_ 1904 DTCI_HistStat_770 1;
BA_ "SignalType" SG_ 1904 DTCI_DTCTriggered_770 "BLN";
BA_ "PacketOrder" SG_ 1904 DTCI_DTCTriggered_770 8;
BA_ "SignalLongName" SG_ 1904 DTCI_DTCTriggered_770 "Diagnostic Trouble Code Information Extended 770 : Diagnostic Trouble Code Triggered";
BA_ "VNSigAllNodes" SG_ 1904 DTCI_DTCTriggered_770 1;
BA_ "SignalType" SG_ 1904 DTCI_DTCSource_770 "UNM";
BA_ "PacketOrder" SG_ 1904 DTCI_DTCSource_770 9;
BA_ "SignalLongName" SG_ 1904 DTCI_DTCSource_770 "Diagnostic Trouble Code Information Extended 770 : Diagnostic Trouble Code Source";
BA_ "VNSigAllNodes" SG_ 1904 DTCI_DTCSource_770 1;
BA_ "SignalType" SG_ 1904 DTCI_DTCNumber_770 "UNM";
BA_ "PacketOrder" SG_ 1904 DTCI_DTCNumber_770 10;
BA_ "SignalLongName" SG_ 1904 DTCI_DTCNumber_770 "Diagnostic Trouble Code Information Extended 770 : Diagnostic Trouble Code Number";
BA_ "VNSigAllNodes" SG_ 1904 DTCI_DTCNumber_770 1;
BA_ "SignalType" SG_ 1904 DTCI_DTCFaultType_770 "ENM";
BA_ "PacketOrder" SG_ 1904 DTCI_DTCFaultType_770 20;
BA_ "SignalLongName" SG_ 1904 DTCI_DTCFaultType_770 "Diagnostic Trouble Code Information Extended 770 : Diagnostic Trouble Code Fault Type";
BA_ "VNSigAllNodes" SG_ 1904 DTCI_DTCFaultType_770 1;
BA_ "SignalType" SG_ 1904 DTCI_DTCFailType_770 "UNM";
BA_ "PacketOrder" SG_ 1904 DTCI_DTCFailType_770 11;
BA_ "SignalLongName" SG_ 1904 DTCI_DTCFailType_770 "Diagnostic Trouble Code Information Extended 770 : Diagnostic Trouble Code Failure Type";
BA_ "VNSigAllNodes" SG_ 1904 DTCI_DTCFailType_770 1;
BA_ "SignalType" SG_ 1904 DTCI_CurrentStatus_770 "BLN";
BA_ "PacketOrder" SG_ 1904 DTCI_CurrentStatus_770 18;
BA_ "SignalLongName" SG_ 1904 DTCI_CurrentStatus_770 "Diagnostic Trouble Code Information Extended 770 : Current Status";
BA_ "VNSigAllNodes" SG_ 1904 DTCI_CurrentStatus_770 1;
BA_ "SignalType" SG_ 1904 DTCI_CodeSupported_770 "BLN";
BA_ "PacketOrder" SG_ 1904 DTCI_CodeSupported_770 19;
BA_ "SignalLongName" SG_ 1904 DTCI_CodeSupported_770 "Diagnostic Trouble Code Information Extended 770 : Code Supported";
BA_ "VNSigAllNodes" SG_ 1904 DTCI_CodeSupported_770 1;
BA_ "SignalType" SG_ 1908 DTCI_DTCFaultType_774 "ENM";
BA_ "PacketOrder" SG_ 1908 DTCI_DTCFaultType_774 20;
BA_ "SignalLongName" SG_ 1908 DTCI_DTCFaultType_774 "Diagnostic Trouble Code Information Extended 774 : Diagnostic Trouble Code Fault Type";
BA_ "VNSigAllNodes" SG_ 1908 DTCI_DTCFaultType_774 1;
BA_ "SignalType" SG_ 1908 DTCI_CodeSupported_774 "BLN";
BA_ "PacketOrder" SG_ 1908 DTCI_CodeSupported_774 19;
BA_ "SignalLongName" SG_ 1908 DTCI_CodeSupported_774 "Diagnostic Trouble Code Information Extended 774 : Code Supported";
BA_ "VNSigAllNodes" SG_ 1908 DTCI_CodeSupported_774 1;
BA_ "SignalType" SG_ 1908 DTCI_CurrentStatus_774 "BLN";
BA_ "PacketOrder" SG_ 1908 DTCI_CurrentStatus_774 18;
BA_ "SignalLongName" SG_ 1908 DTCI_CurrentStatus_774 "Diagnostic Trouble Code Information Extended 774 : Current Status";
BA_ "VNSigAllNodes" SG_ 1908 DTCI_CurrentStatus_774 1;
BA_ "SignalType" SG_ 1908 DTCI_TstNPsdCdClrdSt_774 "BLN";
BA_ "PacketOrder" SG_ 1908 DTCI_TstNPsdCdClrdSt_774 17;
BA_ "SignalLongName" SG_ 1908 DTCI_TstNPsdCdClrdSt_774 "Diagnostic Trouble Code Information Extended 774 : Test Not Passed Since Code Cleared Status";
BA_ "VNSigAllNodes" SG_ 1908 DTCI_TstNPsdCdClrdSt_774 1;
BA_ "SignalType" SG_ 1908 DTCI_TstFldCdClrdStat_774 "BLN";
BA_ "PacketOrder" SG_ 1908 DTCI_TstFldCdClrdStat_774 16;
BA_ "SignalLongName" SG_ 1908 DTCI_TstFldCdClrdStat_774 "Diagnostic Trouble Code Information Extended 774 : Test Failed Since Code Cleared Status";
BA_ "VNSigAllNodes" SG_ 1908 DTCI_TstFldCdClrdStat_774 1;
BA_ "SignalType" SG_ 1908 DTCI_HistStat_774 "BLN";
BA_ "PacketOrder" SG_ 1908 DTCI_HistStat_774 15;
BA_ "SignalLongName" SG_ 1908 DTCI_HistStat_774 "Diagnostic Trouble Code Information Extended 774 : History Status";
BA_ "VNSigAllNodes" SG_ 1908 DTCI_HistStat_774 1;
BA_ "SignalType" SG_ 1908 DTCI_TstNPsdPwrUpSt_774 "BLN";
BA_ "PacketOrder" SG_ 1908 DTCI_TstNPsdPwrUpSt_774 14;
BA_ "SignalLongName" SG_ 1908 DTCI_TstNPsdPwrUpSt_774 "Diagnostic Trouble Code Information Extended 774 : Test Not Passed Since Power Up Status";
BA_ "VNSigAllNodes" SG_ 1908 DTCI_TstNPsdPwrUpSt_774 1;
BA_ "SignalType" SG_ 1908 DTCI_TstFldPwrUpSt_774 "BLN";
BA_ "PacketOrder" SG_ 1908 DTCI_TstFldPwrUpSt_774 13;
BA_ "SignalLongName" SG_ 1908 DTCI_TstFldPwrUpSt_774 "Diagnostic Trouble Code Information Extended 774 : Test Failed Since Power Up Status";
BA_ "VNSigAllNodes" SG_ 1908 DTCI_TstFldPwrUpSt_774 1;
BA_ "SignalType" SG_ 1908 DTCI_WrnIndRqdSt_774 "BLN";
BA_ "PacketOrder" SG_ 1908 DTCI_WrnIndRqdSt_774 12;
BA_ "SignalLongName" SG_ 1908 DTCI_WrnIndRqdSt_774 "Diagnostic Trouble Code Information Extended 774 : Warning Indicator Requested Status";
BA_ "VNSigAllNodes" SG_ 1908 DTCI_WrnIndRqdSt_774 1;
BA_ "SignalType" SG_ 1908 DTCI_DTCFailType_774 "UNM";
BA_ "PacketOrder" SG_ 1908 DTCI_DTCFailType_774 11;
BA_ "SignalLongName" SG_ 1908 DTCI_DTCFailType_774 "Diagnostic Trouble Code Information Extended 774 : Diagnostic Trouble Code Failure Type";
BA_ "VNSigAllNodes" SG_ 1908 DTCI_DTCFailType_774 1;
BA_ "SignalType" SG_ 1908 DTCI_DTCNumber_774 "UNM";
BA_ "PacketOrder" SG_ 1908 DTCI_DTCNumber_774 10;
BA_ "SignalLongName" SG_ 1908 DTCI_DTCNumber_774 "Diagnostic Trouble Code Information Extended 774 : Diagnostic Trouble Code Number";
BA_ "VNSigAllNodes" SG_ 1908 DTCI_DTCNumber_774 1;
BA_ "SignalType" SG_ 1908 DTCI_DTCSource_774 "UNM";
BA_ "PacketOrder" SG_ 1908 DTCI_DTCSource_774 9;
BA_ "SignalLongName" SG_ 1908 DTCI_DTCSource_774 "Diagnostic Trouble Code Information Extended 774 : Diagnostic Trouble Code Source";
BA_ "VNSigAllNodes" SG_ 1908 DTCI_DTCSource_774 1;
BA_ "SignalType" SG_ 1908 DTCI_DTCTriggered_774 "BLN";
BA_ "PacketOrder" SG_ 1908 DTCI_DTCTriggered_774 8;
BA_ "SignalLongName" SG_ 1908 DTCI_DTCTriggered_774 "Diagnostic Trouble Code Information Extended 774 : Diagnostic Trouble Code Triggered";
BA_ "VNSigAllNodes" SG_ 1908 DTCI_DTCTriggered_774 1;
BA_ "SignalType" SG_ 1908 DTCIUnused7_774 "BLN";
BA_ "PacketOrder" SG_ 1908 DTCIUnused7_774 7;
BA_ "SignalLongName" SG_ 1908 DTCIUnused7_774 "Diagnostic Trouble Code Information Extended 774 : Unused 7";
BA_ "VNSigAllNodes" SG_ 1908 DTCIUnused7_774 1;
BA_ "SignalType" SG_ 1908 DTCIUnused6_774 "BLN";
BA_ "PacketOrder" SG_ 1908 DTCIUnused6_774 6;
BA_ "SignalLongName" SG_ 1908 DTCIUnused6_774 "Diagnostic Trouble Code Information Extended 774 : Unused 6";
BA_ "VNSigAllNodes" SG_ 1908 DTCIUnused6_774 1;
BA_ "SignalType" SG_ 1908 DTCIUnused5_774 "BLN";
BA_ "PacketOrder" SG_ 1908 DTCIUnused5_774 5;
BA_ "SignalLongName" SG_ 1908 DTCIUnused5_774 "Diagnostic Trouble Code Information Extended 774 : Unused 5";
BA_ "VNSigAllNodes" SG_ 1908 DTCIUnused5_774 1;
BA_ "SignalType" SG_ 1908 DTCIUnused4_774 "BLN";
BA_ "PacketOrder" SG_ 1908 DTCIUnused4_774 4;
BA_ "SignalLongName" SG_ 1908 DTCIUnused4_774 "Diagnostic Trouble Code Information Extended 774 : Unused 4";
BA_ "VNSigAllNodes" SG_ 1908 DTCIUnused4_774 1;
BA_ "SignalType" SG_ 1908 DTCIUnused3_774 "BLN";
BA_ "PacketOrder" SG_ 1908 DTCIUnused3_774 3;
BA_ "SignalLongName" SG_ 1908 DTCIUnused3_774 "Diagnostic Trouble Code Information Extended 774 : Unused 3";
BA_ "VNSigAllNodes" SG_ 1908 DTCIUnused3_774 1;
BA_ "SignalType" SG_ 1908 DTCIUnused2_774 "BLN";
BA_ "PacketOrder" SG_ 1908 DTCIUnused2_774 2;
BA_ "SignalLongName" SG_ 1908 DTCIUnused2_774 "Diagnostic Trouble Code Information Extended 774 : Unused 2";
BA_ "VNSigAllNodes" SG_ 1908 DTCIUnused2_774 1;
BA_ "SignalType" SG_ 1908 DTCIUnused1_774 "BLN";
BA_ "PacketOrder" SG_ 1908 DTCIUnused1_774 1;
BA_ "SignalLongName" SG_ 1908 DTCIUnused1_774 "Diagnostic Trouble Code Information Extended 774 : Unused 1";
BA_ "VNSigAllNodes" SG_ 1908 DTCIUnused1_774 1;
BA_ "SignalType" SG_ 1909 DTCI_DTCFaultType_775 "ENM";
BA_ "PacketOrder" SG_ 1909 DTCI_DTCFaultType_775 20;
BA_ "SignalLongName" SG_ 1909 DTCI_DTCFaultType_775 "Diagnostic Trouble Code Information Extended 775 : Diagnostic Trouble Code Fault Type";
BA_ "VNSigAllNodes" SG_ 1909 DTCI_DTCFaultType_775 1;
BA_ "SignalType" SG_ 1909 DTCI_CodeSupported_775 "BLN";
BA_ "PacketOrder" SG_ 1909 DTCI_CodeSupported_775 19;
BA_ "SignalLongName" SG_ 1909 DTCI_CodeSupported_775 "Diagnostic Trouble Code Information Extended 775 : Code Supported";
BA_ "VNSigAllNodes" SG_ 1909 DTCI_CodeSupported_775 1;
BA_ "SignalType" SG_ 1909 DTCI_CurrentStatus_775 "BLN";
BA_ "PacketOrder" SG_ 1909 DTCI_CurrentStatus_775 18;
BA_ "SignalLongName" SG_ 1909 DTCI_CurrentStatus_775 "Diagnostic Trouble Code Information Extended 775 : Current Status";
BA_ "VNSigAllNodes" SG_ 1909 DTCI_CurrentStatus_775 1;
BA_ "SignalType" SG_ 1909 DTCI_TstNPsdCdClrdSt_775 "BLN";
BA_ "PacketOrder" SG_ 1909 DTCI_TstNPsdCdClrdSt_775 17;
BA_ "SignalLongName" SG_ 1909 DTCI_TstNPsdCdClrdSt_775 "Diagnostic Trouble Code Information Extended 775 : Test Not Passed Since Code Cleared Status";
BA_ "VNSigAllNodes" SG_ 1909 DTCI_TstNPsdCdClrdSt_775 1;
BA_ "SignalType" SG_ 1909 DTCI_TstFldCdClrdStat_775 "BLN";
BA_ "PacketOrder" SG_ 1909 DTCI_TstFldCdClrdStat_775 16;
BA_ "SignalLongName" SG_ 1909 DTCI_TstFldCdClrdStat_775 "Diagnostic Trouble Code Information Extended 775 : Test Failed Since Code Cleared Status";
BA_ "VNSigAllNodes" SG_ 1909 DTCI_TstFldCdClrdStat_775 1;
BA_ "SignalType" SG_ 1909 DTCI_HistStat_775 "BLN";
BA_ "PacketOrder" SG_ 1909 DTCI_HistStat_775 15;
BA_ "SignalLongName" SG_ 1909 DTCI_HistStat_775 "Diagnostic Trouble Code Information Extended 775 : History Status";
BA_ "VNSigAllNodes" SG_ 1909 DTCI_HistStat_775 1;
BA_ "SignalType" SG_ 1909 DTCI_TstNPsdPwrUpSt_775 "BLN";
BA_ "PacketOrder" SG_ 1909 DTCI_TstNPsdPwrUpSt_775 14;
BA_ "SignalLongName" SG_ 1909 DTCI_TstNPsdPwrUpSt_775 "Diagnostic Trouble Code Information Extended 775 : Test Not Passed Since Power Up Status";
BA_ "VNSigAllNodes" SG_ 1909 DTCI_TstNPsdPwrUpSt_775 1;
BA_ "SignalType" SG_ 1909 DTCI_TstFldPwrUpSt_775 "BLN";
BA_ "PacketOrder" SG_ 1909 DTCI_TstFldPwrUpSt_775 13;
BA_ "SignalLongName" SG_ 1909 DTCI_TstFldPwrUpSt_775 "Diagnostic Trouble Code Information Extended 775 : Test Failed Since Power Up Status";
BA_ "VNSigAllNodes" SG_ 1909 DTCI_TstFldPwrUpSt_775 1;
BA_ "SignalType" SG_ 1909 DTCI_WrnIndRqdSt_775 "BLN";
BA_ "PacketOrder" SG_ 1909 DTCI_WrnIndRqdSt_775 12;
BA_ "SignalLongName" SG_ 1909 DTCI_WrnIndRqdSt_775 "Diagnostic Trouble Code Information Extended 775 : Warning Indicator Requested Status";
BA_ "VNSigAllNodes" SG_ 1909 DTCI_WrnIndRqdSt_775 1;
BA_ "SignalType" SG_ 1909 DTCI_DTCFailType_775 "UNM";
BA_ "PacketOrder" SG_ 1909 DTCI_DTCFailType_775 11;
BA_ "SignalLongName" SG_ 1909 DTCI_DTCFailType_775 "Diagnostic Trouble Code Information Extended 775 : Diagnostic Trouble Code Failure Type";
BA_ "VNSigAllNodes" SG_ 1909 DTCI_DTCFailType_775 1;
BA_ "SignalType" SG_ 1909 DTCI_DTCNumber_775 "UNM";
BA_ "PacketOrder" SG_ 1909 DTCI_DTCNumber_775 10;
BA_ "SignalLongName" SG_ 1909 DTCI_DTCNumber_775 "Diagnostic Trouble Code Information Extended 775 : Diagnostic Trouble Code Number";
BA_ "VNSigAllNodes" SG_ 1909 DTCI_DTCNumber_775 1;
BA_ "SignalType" SG_ 1909 DTCI_DTCSource_775 "UNM";
BA_ "PacketOrder" SG_ 1909 DTCI_DTCSource_775 9;
BA_ "SignalLongName" SG_ 1909 DTCI_DTCSource_775 "Diagnostic Trouble Code Information Extended 775 : Diagnostic Trouble Code Source";
BA_ "VNSigAllNodes" SG_ 1909 DTCI_DTCSource_775 1;
BA_ "SignalType" SG_ 1909 DTCI_DTCTriggered_775 "BLN";
BA_ "PacketOrder" SG_ 1909 DTCI_DTCTriggered_775 8;
BA_ "SignalLongName" SG_ 1909 DTCI_DTCTriggered_775 "Diagnostic Trouble Code Information Extended 775 : Diagnostic Trouble Code Triggered";
BA_ "VNSigAllNodes" SG_ 1909 DTCI_DTCTriggered_775 1;
BA_ "SignalType" SG_ 1909 DTCIUnused7_775 "BLN";
BA_ "PacketOrder" SG_ 1909 DTCIUnused7_775 7;
BA_ "SignalLongName" SG_ 1909 DTCIUnused7_775 "Diagnostic Trouble Code Information Extended 775 : Unused 7";
BA_ "VNSigAllNodes" SG_ 1909 DTCIUnused7_775 1;
BA_ "SignalType" SG_ 1909 DTCIUnused6_775 "BLN";
BA_ "PacketOrder" SG_ 1909 DTCIUnused6_775 6;
BA_ "SignalLongName" SG_ 1909 DTCIUnused6_775 "Diagnostic Trouble Code Information Extended 775 : Unused 6";
BA_ "VNSigAllNodes" SG_ 1909 DTCIUnused6_775 1;
BA_ "SignalType" SG_ 1909 DTCIUnused5_775 "BLN";
BA_ "PacketOrder" SG_ 1909 DTCIUnused5_775 5;
BA_ "SignalLongName" SG_ 1909 DTCIUnused5_775 "Diagnostic Trouble Code Information Extended 775 : Unused 5";
BA_ "VNSigAllNodes" SG_ 1909 DTCIUnused5_775 1;
BA_ "SignalType" SG_ 1909 DTCIUnused4_775 "BLN";
BA_ "PacketOrder" SG_ 1909 DTCIUnused4_775 4;
BA_ "SignalLongName" SG_ 1909 DTCIUnused4_775 "Diagnostic Trouble Code Information Extended 775 : Unused 4";
BA_ "VNSigAllNodes" SG_ 1909 DTCIUnused4_775 1;
BA_ "SignalType" SG_ 1909 DTCIUnused3_775 "BLN";
BA_ "PacketOrder" SG_ 1909 DTCIUnused3_775 3;
BA_ "SignalLongName" SG_ 1909 DTCIUnused3_775 "Diagnostic Trouble Code Information Extended 775 : Unused 3";
BA_ "VNSigAllNodes" SG_ 1909 DTCIUnused3_775 1;
BA_ "SignalType" SG_ 1909 DTCIUnused2_775 "BLN";
BA_ "PacketOrder" SG_ 1909 DTCIUnused2_775 2;
BA_ "SignalLongName" SG_ 1909 DTCIUnused2_775 "Diagnostic Trouble Code Information Extended 775 : Unused 2";
BA_ "VNSigAllNodes" SG_ 1909 DTCIUnused2_775 1;
BA_ "SignalType" SG_ 1909 DTCIUnused1_775 "BLN";
BA_ "PacketOrder" SG_ 1909 DTCIUnused1_775 1;
BA_ "SignalLongName" SG_ 1909 DTCIUnused1_775 "Diagnostic Trouble Code Information Extended 775 : Unused 1";
BA_ "VNSigAllNodes" SG_ 1909 DTCIUnused1_775 1;
BA_REL_ "GenSigSuprvResp" BU_SG_REL_ BCM_HS SG_ 1280 TireRRLowTracIO 1;
BA_REL_ "GenSigTimeoutMsg" BU_SG_REL_ BCM_HS SG_ 1280 TireRRLowTracIO 1280;
BA_REL_ "GenSigTimeoutTime" BU_SG_REL_ BCM_HS SG_ 1280 TireRRLowTracIO 2500;
BA_REL_ "GenSigSuprvResp" BU_SG_REL_ BCM_HS SG_ 1280 TireRFLowTracIO 1;
BA_REL_ "GenSigTimeoutMsg" BU_SG_REL_ BCM_HS SG_ 1280 TireRFLowTracIO 1280;
BA_REL_ "GenSigTimeoutTime" BU_SG_REL_ BCM_HS SG_ 1280 TireRFLowTracIO 2500;
BA_REL_ "GenSigSuprvResp" BU_SG_REL_ BCM_HS SG_ 1280 TireLRLowTracIO 1;
BA_REL_ "GenSigTimeoutMsg" BU_SG_REL_ BCM_HS SG_ 1280 TireLRLowTracIO 1280;
BA_REL_ "GenSigTimeoutTime" BU_SG_REL_ BCM_HS SG_ 1280 TireLRLowTracIO 2500;
BA_REL_ "GenSigSuprvResp" BU_SG_REL_ BCM_HS SG_ 1280 TireLFLowTracIO 1;
BA_REL_ "GenSigTimeoutMsg" BU_SG_REL_ BCM_HS SG_ 1280 TireLFLowTracIO 1280;
BA_REL_ "GenSigTimeoutTime" BU_SG_REL_ BCM_HS SG_ 1280 TireLFLowTracIO 2500;
BA_REL_ "GenSigSuprvResp" BU_SG_REL_ RDCM_HS SG_ 1280 WhlRotStatTmstmpRes 1;
BA_REL_ "GenSigTimeoutMsg" BU_SG_REL_ RDCM_HS SG_ 1280 WhlRotStatTmstmpRes 1280;
BA_REL_ "GenSigTimeoutTime" BU_SG_REL_ RDCM_HS SG_ 1280 WhlRotStatTmstmpRes 2500;
BA_REL_ "GenSigSuprvResp" BU_SG_REL_ VES_HS SG_ 1280 WhlRotStatTmstmpRes 1;
BA_REL_ "GenSigTimeoutMsg" BU_SG_REL_ VES_HS SG_ 1280 WhlRotStatTmstmpRes 1280;
BA_REL_ "GenSigTimeoutTime" BU_SG_REL_ VES_HS SG_ 1280 WhlRotStatTmstmpRes 2500;
BA_REL_ "GenSigSuprvResp" BU_SG_REL_ EPS_HS SG_ 1280 WhlRotStatTmstmpRes 1;
BA_REL_ "GenSigTimeoutMsg" BU_SG_REL_ EPS_HS SG_ 1280 WhlRotStatTmstmpRes 1280;
BA_REL_ "GenSigTimeoutTime" BU_SG_REL_ EPS_HS SG_ 1280 WhlRotStatTmstmpRes 2500;
BA_REL_ "GenSigSuprvResp" BU_SG_REL_ EOCM_F_HS SG_ 1280 WhlRotStatTmstmpRes 1;
BA_REL_ "GenSigTimeoutTime" BU_SG_REL_ EOCM_F_HS SG_ 1280 WhlRotStatTmstmpRes 2500;
BA_REL_ "GenSigSuprvResp" BU_SG_REL_ ICCM_OBD_HS SG_ 1280 WhlRotStatTmstmpRes 1;
BA_REL_ "GenSigTimeoutMsg" BU_SG_REL_ ICCM_OBD_HS SG_ 1280 WhlRotStatTmstmpRes 1280;
BA_REL_ "GenSigTimeoutTime" BU_SG_REL_ ICCM_OBD_HS SG_ 1280 WhlRotStatTmstmpRes 2500;
BA_REL_ "GenSigSuprvResp" BU_SG_REL_ ICCM_HS SG_ 1280 WhlRotStatTmstmpRes 1;
BA_REL_ "GenSigTimeoutMsg" BU_SG_REL_ ICCM_HS SG_ 1280 WhlRotStatTmstmpRes 1280;
BA_REL_ "GenSigTimeoutTime" BU_SG_REL_ ICCM_HS SG_ 1280 WhlRotStatTmstmpRes 2500;
BA_REL_ "GenSigSuprvResp" BU_SG_REL_ TCCM_HS SG_ 1280 WhlPlsPerRevNonDrvn 1;
BA_REL_ "GenSigTimeoutMsg" BU_SG_REL_ TCCM_HS SG_ 1280 WhlPlsPerRevNonDrvn 1280;
BA_REL_ "GenSigTimeoutTime" BU_SG_REL_ TCCM_HS SG_ 1280 WhlPlsPerRevNonDrvn 2500;
BA_REL_ "GenSigSuprvResp" BU_SG_REL_ EOCM_F_HS SG_ 1280 WhlPlsPerRevNonDrvn 1;
BA_REL_ "GenSigTimeoutTime" BU_SG_REL_ EOCM_F_HS SG_ 1280 WhlPlsPerRevNonDrvn 2500;
BA_REL_ "GenSigRxStartValue" BU_SG_REL_ RDCM_HS SG_ 1280 WhlPlsPerRevNonDrvn "48 pulses ($30)";
BA_REL_ "GenSigSuprvResp" BU_SG_REL_ TCCM_HS SG_ 1280 WhlPlsPerRevDrvn 1;
BA_REL_ "GenSigTimeoutMsg" BU_SG_REL_ TCCM_HS SG_ 1280 WhlPlsPerRevDrvn 1280;
BA_REL_ "GenSigTimeoutTime" BU_SG_REL_ TCCM_HS SG_ 1280 WhlPlsPerRevDrvn 2500;
BA_REL_ "GenSigSuprvResp" BU_SG_REL_ EOCM_F_HS SG_ 1280 WhlPlsPerRevDrvn 1;
BA_REL_ "GenSigTimeoutTime" BU_SG_REL_ EOCM_F_HS SG_ 1280 WhlPlsPerRevDrvn 2500;
BA_REL_ "GenSigSuprvResp" BU_SG_REL_ RDCM_HS SG_ 1280 WhlPlsPerRevDrvn 1;
BA_REL_ "GenSigTimeoutMsg" BU_SG_REL_ RDCM_HS SG_ 1280 WhlPlsPerRevDrvn 1280;
BA_REL_ "GenSigTimeoutTime" BU_SG_REL_ RDCM_HS SG_ 1280 WhlPlsPerRevDrvn 2500;
BA_REL_ "GenSigRxStartValue" BU_SG_REL_ RDCM_HS SG_ 1280 WhlPlsPerRevDrvn "48 pulses ($30)";
BA_REL_ "GenSigSuprvResp" BU_SG_REL_ RDCM_HS SG_ 1280 WhlPlsPerRevDrvn 1;
BA_REL_ "GenSigTimeoutMsg" BU_SG_REL_ RDCM_HS SG_ 1280 WhlPlsPerRevDrvn 1280;
BA_REL_ "GenSigTimeoutTime" BU_SG_REL_ RDCM_HS SG_ 1280 WhlPlsPerRevDrvn 2500;
BA_REL_ "GenSigSuprvResp" BU_SG_REL_ TCM_HS SG_ 190 EngSpdMaxCapRdcdRng 1;
BA_REL_ "GenSigTimeoutMsg" BU_SG_REL_ TCM_HS SG_ 190 EngSpdMaxCapRdcdRng 190;
BA_REL_ "GenSigTimeoutTime" BU_SG_REL_ TCM_HS SG_ 190 EngSpdMaxCapRdcdRng 250;
BA_REL_ "GenSigSuprvResp" BU_SG_REL_ EBOOST_HS SG_ 190 PTSnsdBrkPdlInfPVal 1;
BA_REL_ "GenSigTimeoutMsg" BU_SG_REL_ EBOOST_HS SG_ 190 PTSnsdBrkPdlInfPVal 190;
BA_REL_ "GenSigTimeoutTime" BU_SG_REL_ EBOOST_HS SG_ 190 PTSnsdBrkPdlInfPVal 250;
BA_REL_ "GenSigSuprvResp" BU_SG_REL_ ICCM_OBD_HS SG_ 190 PTSnsdBrkPdlInfPVal 1;
BA_REL_ "GenSigTimeoutMsg" BU_SG_REL_ ICCM_OBD_HS SG_ 190 PTSnsdBrkPdlInfPVal 190;
BA_REL_ "GenSigTimeoutTime" BU_SG_REL_ ICCM_OBD_HS SG_ 190 PTSnsdBrkPdlInfPVal 250;
BA_REL_ "GenSigSuprvResp" BU_SG_REL_ ICCM_HS SG_ 190 PTSnsdBrkPdlInfPVal 1;
BA_REL_ "GenSigTimeoutMsg" BU_SG_REL_ ICCM_HS SG_ 190 PTSnsdBrkPdlInfPVal 190;
BA_REL_ "GenSigTimeoutTime" BU_SG_REL_ ICCM_HS SG_ 190 PTSnsdBrkPdlInfPVal 250;
BA_REL_ "GenSigSuprvResp" BU_SG_REL_ TCM_HS SG_ 190 TrnsAuxPmpAct 1;
BA_REL_ "GenSigTimeoutMsg" BU_SG_REL_ TCM_HS SG_ 190 TrnsAuxPmpAct 190;
BA_REL_ "GenSigTimeoutTime" BU_SG_REL_ TCM_HS SG_ 190 TrnsAuxPmpAct 250;
BA_REL_ "GenSigSuprvResp" BU_SG_REL_ BCP_HS SG_ 190 AccPos 1;
BA_REL_ "GenSigTimeoutMsg" BU_SG_REL_ BCP_HS SG_ 190 AccPos 190;
BA_REL_ "GenSigTimeoutTime" BU_SG_REL_ BCP_HS SG_ 190 AccPos 250;
BA_REL_ "GenSigSuprvResp" BU_SG_REL_ FICM_HS SG_ 190 AccPos 1;
BA_REL_ "GenSigTimeoutMsg" BU_SG_REL_ FICM_HS SG_ 190 AccPos 190;
BA_REL_ "GenSigTimeoutTime" BU_SG_REL_ FICM_HS SG_ 190 AccPos 250;
BA_REL_ "GenSigSuprvResp" BU_SG_REL_ TCM_HS SG_ 190 AccPos 1;
BA_REL_ "GenSigTimeoutMsg" BU_SG_REL_ TCM_HS SG_ 190 AccPos 190;
BA_REL_ "GenSigTimeoutTime" BU_SG_REL_ TCM_HS SG_ 190 AccPos 250;
BA_REL_ "GenSigSuprvResp" BU_SG_REL_ TCCM_HS SG_ 190 AccPos 1;
BA_REL_ "GenSigTimeoutMsg" BU_SG_REL_ TCCM_HS SG_ 190 AccPos 190;
BA_REL_ "GenSigTimeoutTime" BU_SG_REL_ TCCM_HS SG_ 190 AccPos 250;
BA_REL_ "GenSigSuprvResp" BU_SG_REL_ EBOOST_HS SG_ 190 PTSnsdBrkPdlInfARC 1;
BA_REL_ "GenSigTimeoutMsg" BU_SG_REL_ EBOOST_HS SG_ 190 PTSnsdBrkPdlInfARC 190;
BA_REL_ "GenSigTimeoutTime" BU_SG_REL_ EBOOST_HS SG_ 190 PTSnsdBrkPdlInfARC 250;
BA_REL_ "GenSigSuprvResp" BU_SG_REL_ ICCM_OBD_HS SG_ 190 PTSnsdBrkPdlInfARC 1;
BA_REL_ "GenSigTimeoutMsg" BU_SG_REL_ ICCM_OBD_HS SG_ 190 PTSnsdBrkPdlInfARC 190;
BA_REL_ "GenSigTimeoutTime" BU_SG_REL_ ICCM_OBD_HS SG_ 190 PTSnsdBrkPdlInfARC 250;
BA_REL_ "GenSigSuprvResp" BU_SG_REL_ ICCM_HS SG_ 190 PTSnsdBrkPdlInfARC 1;
BA_REL_ "GenSigTimeoutMsg" BU_SG_REL_ ICCM_HS SG_ 190 PTSnsdBrkPdlInfARC 190;
BA_REL_ "GenSigTimeoutTime" BU_SG_REL_ ICCM_HS SG_ 190 PTSnsdBrkPdlInfARC 250;
BA_REL_ "GenSigSuprvResp" BU_SG_REL_ EBCM_OBD_HS SG_ 190 PSBPI_PTSnBrkPdlPsV 1;
BA_REL_ "GenSigTimeoutMsg" BU_SG_REL_ EBCM_OBD_HS SG_ 190 PSBPI_PTSnBrkPdlPsV 190;
BA_REL_ "GenSigTimeoutTime" BU_SG_REL_ EBCM_OBD_HS SG_ 190 PSBPI_PTSnBrkPdlPsV 250;
BA_REL_ "GenSigSuprvResp" BU_SG_REL_ EBCM_HS SG_ 190 PSBPI_PTSnBrkPdlPsV 1;
BA_REL_ "GenSigTimeoutMsg" BU_SG_REL_ EBCM_HS SG_ 190 PSBPI_PTSnBrkPdlPsV 190;
BA_REL_ "GenSigTimeoutTime" BU_SG_REL_ EBCM_HS SG_ 190 PSBPI_PTSnBrkPdlPsV 250;
BA_REL_ "GenSigSuprvResp" BU_SG_REL_ EBOOST_HS SG_ 190 PSBPI_PTSnBrkPdlPsV 1;
BA_REL_ "GenSigTimeoutMsg" BU_SG_REL_ EBOOST_HS SG_ 190 PSBPI_PTSnBrkPdlPsV 190;
BA_REL_ "GenSigTimeoutTime" BU_SG_REL_ EBOOST_HS SG_ 190 PSBPI_PTSnBrkPdlPsV 250;
BA_REL_ "GenSigSuprvResp" BU_SG_REL_ ICCM_OBD_HS SG_ 190 PSBPI_PTSnBrkPdlPsV 1;
BA_REL_ "GenSigTimeoutMsg" BU_SG_REL_ ICCM_OBD_HS SG_ 190 PSBPI_PTSnBrkPdlPsV 190;
BA_REL_ "GenSigTimeoutTime" BU_SG_REL_ ICCM_OBD_HS SG_ 190 PSBPI_PTSnBrkPdlPsV 250;
BA_REL_ "GenSigSuprvResp" BU_SG_REL_ ICCM_HS SG_ 190 PSBPI_PTSnBrkPdlPsV 1;
BA_REL_ "GenSigTimeoutMsg" BU_SG_REL_ ICCM_HS SG_ 190 PSBPI_PTSnBrkPdlPsV 190;
BA_REL_ "GenSigTimeoutTime" BU_SG_REL_ ICCM_HS SG_ 190 PSBPI_PTSnBrkPdlPsV 250;
BA_REL_ "GenSigSuprvResp" BU_SG_REL_ EBCM_OBD_HS SG_ 190 PSBPI_PTSnBrkPdlPs 1;
BA_REL_ "GenSigTimeoutMsg" BU_SG_REL_ EBCM_OBD_HS SG_ 190 PSBPI_PTSnBrkPdlPs 190;
BA_REL_ "GenSigTimeoutTime" BU_SG_REL_ EBCM_OBD_HS SG_ 190 PSBPI_PTSnBrkPdlPs 250;
BA_REL_ "GenSigSuprvResp" BU_SG_REL_ EBCM_HS SG_ 190 PSBPI_PTSnBrkPdlPs 1;
BA_REL_ "GenSigTimeoutMsg" BU_SG_REL_ EBCM_HS SG_ 190 PSBPI_PTSnBrkPdlPs 190;
BA_REL_ "GenSigTimeoutTime" BU_SG_REL_ EBCM_HS SG_ 190 PSBPI_PTSnBrkPdlPs 250;
BA_REL_ "GenSigSuprvResp" BU_SG_REL_ EBOOST_HS SG_ 190 PSBPI_PTSnBrkPdlPs 1;
BA_REL_ "GenSigTimeoutMsg" BU_SG_REL_ EBOOST_HS SG_ 190 PSBPI_PTSnBrkPdlPs 190;
BA_REL_ "GenSigTimeoutTime" BU_SG_REL_ EBOOST_HS SG_ 190 PSBPI_PTSnBrkPdlPs 250;
BA_REL_ "GenSigSuprvResp" BU_SG_REL_ ICCM_OBD_HS SG_ 190 PSBPI_PTSnBrkPdlPs 1;
BA_REL_ "GenSigTimeoutMsg" BU_SG_REL_ ICCM_OBD_HS SG_ 190 PSBPI_PTSnBrkPdlPs 190;
BA_REL_ "GenSigTimeoutTime" BU_SG_REL_ ICCM_OBD_HS SG_ 190 PSBPI_PTSnBrkPdlPs 250;
BA_REL_ "GenSigSuprvResp" BU_SG_REL_ ICCM_HS SG_ 190 PSBPI_PTSnBrkPdlPs 1;
BA_REL_ "GenSigTimeoutMsg" BU_SG_REL_ ICCM_HS SG_ 190 PSBPI_PTSnBrkPdlPs 190;
BA_REL_ "GenSigTimeoutTime" BU_SG_REL_ ICCM_HS SG_ 190 PSBPI_PTSnBrkPdlPs 250;
BA_REL_ "GenSigSuprvRespSubValue" BU_SG_REL_ BCM_HS SG_ 534 DmpSysVehTopSpdLim 255;
BA_REL_ "GenSigSuprvResp" BU_SG_REL_ BCM_HS SG_ 534 DmpSysVehTopSpdLim 2;
BA_REL_ "GenSigTimeoutMsg" BU_SG_REL_ BCM_HS SG_ 534 DmpSysVehTopSpdLim 534;
BA_REL_ "GenSigTimeoutTime" BU_SG_REL_ BCM_HS SG_ 534 DmpSysVehTopSpdLim 250;
BA_REL_ "GenSigSuprvResp" BU_SG_REL_ BCM_HS SG_ 534 SrvSuspSysIO 1;
BA_REL_ "GenSigTimeoutMsg" BU_SG_REL_ BCM_HS SG_ 534 SrvSuspSysIO 534;
BA_REL_ "GenSigTimeoutTime" BU_SG_REL_ BCM_HS SG_ 534 SrvSuspSysIO 250;
BA_REL_ "GenSigSuprvResp" BU_SG_REL_ EBCM_OBD_HS SG_ 309 StBltTgtCSRq 1;
BA_REL_ "GenSigTimeoutMsg" BU_SG_REL_ EBCM_OBD_HS SG_ 309 StBltTgtCSRq 309;
BA_REL_ "GenSigTimeoutTime" BU_SG_REL_ EBCM_OBD_HS SG_ 309 StBltTgtCSRq 250;
BA_REL_ "GenSigSuprvResp" BU_SG_REL_ EBCM_HS SG_ 309 StBltTgtCSRq 1;
BA_REL_ "GenSigTimeoutMsg" BU_SG_REL_ EBCM_HS SG_ 309 StBltTgtCSRq 309;
BA_REL_ "GenSigTimeoutTime" BU_SG_REL_ EBCM_HS SG_ 309 StBltTgtCSRq 250;
BA_REL_ "GenSigSuprvResp" BU_SG_REL_ EOCM_F_HS SG_ 309 ColPrSysCustReq 1;
BA_REL_ "GenSigTimeoutMsg" BU_SG_REL_ EOCM_F_HS SG_ 309 ColPrSysCustReq 309;
BA_REL_ "GenSigTimeoutTime" BU_SG_REL_ EOCM_F_HS SG_ 309 ColPrSysCustReq 250;
BA_REL_ "GenSigSuprvResp" BU_SG_REL_ EBCM_OBD_HS SG_ 309 CldrYr 1;
BA_REL_ "GenSigTimeoutMsg" BU_SG_REL_ EBCM_OBD_HS SG_ 309 CldrYr 309;
BA_REL_ "GenSigTimeoutTime" BU_SG_REL_ EBCM_OBD_HS SG_ 309 CldrYr 250;
BA_REL_ "GenSigSuprvResp" BU_SG_REL_ EBCM_OBD_HS SG_ 309 CldrYr 1;
BA_REL_ "GenSigTimeoutMsg" BU_SG_REL_ EBCM_OBD_HS SG_ 309 CldrYr 309;
BA_REL_ "GenSigTimeoutTime" BU_SG_REL_ EBCM_OBD_HS SG_ 309 CldrYr 250;
BA_REL_ "GenSigSuprvResp" BU_SG_REL_ EBCM_HS SG_ 309 CldrYr 1;
BA_REL_ "GenSigTimeoutMsg" BU_SG_REL_ EBCM_HS SG_ 309 CldrYr 309;
BA_REL_ "GenSigTimeoutTime" BU_SG_REL_ EBCM_HS SG_ 309 CldrYr 250;
BA_REL_ "GenSigSuprvResp" BU_SG_REL_ EBCM_HS SG_ 309 CldrYr 1;
BA_REL_ "GenSigTimeoutMsg" BU_SG_REL_ EBCM_HS SG_ 309 CldrYr 309;
BA_REL_ "GenSigTimeoutTime" BU_SG_REL_ EBCM_HS SG_ 309 CldrYr 250;
BA_REL_ "GenSigSuprvResp" BU_SG_REL_ EBCM_OBD_HS SG_ 309 CldrMth 1;
BA_REL_ "GenSigTimeoutMsg" BU_SG_REL_ EBCM_OBD_HS SG_ 309 CldrMth 309;
BA_REL_ "GenSigTimeoutTime" BU_SG_REL_ EBCM_OBD_HS SG_ 309 CldrMth 250;
BA_REL_ "GenSigSuprvResp" BU_SG_REL_ EBCM_HS SG_ 309 CldrMth 1;
BA_REL_ "GenSigTimeoutMsg" BU_SG_REL_ EBCM_HS SG_ 309 CldrMth 309;
BA_REL_ "GenSigTimeoutTime" BU_SG_REL_ EBCM_HS SG_ 309 CldrMth 250;
BA_REL_ "GenSigSuprvResp" BU_SG_REL_ EBCM_OBD_HS SG_ 309 CldrDay 1;
BA_REL_ "GenSigTimeoutMsg" BU_SG_REL_ EBCM_OBD_HS SG_ 309 CldrDay 309;
BA_REL_ "GenSigTimeoutTime" BU_SG_REL_ EBCM_OBD_HS SG_ 309 CldrDay 250;
BA_REL_ "GenSigSuprvResp" BU_SG_REL_ EBCM_HS SG_ 309 CldrDay 1;
BA_REL_ "GenSigTimeoutMsg" BU_SG_REL_ EBCM_HS SG_ 309 CldrDay 309;
BA_REL_ "GenSigTimeoutTime" BU_SG_REL_ EBCM_HS SG_ 309 CldrDay 250;
BA_REL_ "GenSigVDAFailComment" BU_SG_REL_ AHL_AFL_HS SG_ 309 CtLghtDet "Automatic High Beam Virtual Device Availability";
BA_REL_ "GenSigVDAFailResp" BU_SG_REL_ AHL_AFL_HS SG_ 309 CtLghtDet 1;
BA_REL_ "GenSigSuprvResp" BU_SG_REL_ AHL_AFL_HS SG_ 309 CtLghtDet 1;
BA_REL_ "GenSigTimeoutMsg" BU_SG_REL_ AHL_AFL_HS SG_ 309 CtLghtDet 309;
BA_REL_ "GenSigTimeoutTime" BU_SG_REL_ AHL_AFL_HS SG_ 309 CtLghtDet 250;
BA_REL_ "GenSigSuprvResp" BU_SG_REL_ HMIM_HS SG_ 309 VehMovState 1;
BA_REL_ "GenSigTimeoutMsg" BU_SG_REL_ HMIM_HS SG_ 309 VehMovState 309;
BA_REL_ "GenSigTimeoutTime" BU_SG_REL_ HMIM_HS SG_ 309 VehMovState 250;
BA_REL_ "GenSigSuprvResp" BU_SG_REL_ AHL_AFL_HS SG_ 309 VehMovState 1;
BA_REL_ "GenSigTimeoutMsg" BU_SG_REL_ AHL_AFL_HS SG_ 309 VehMovState 309;
BA_REL_ "GenSigTimeoutTime" BU_SG_REL_ AHL_AFL_HS SG_ 309 VehMovState 250;
BA_REL_ "GenSigSuprvResp" BU_SG_REL_ EOCM_F_HS SG_ 309 WSWshSwAtv 1;
BA_REL_ "GenSigTimeoutMsg" BU_SG_REL_ EOCM_F_HS SG_ 309 WSWshSwAtv 309;
BA_REL_ "GenSigTimeoutTime" BU_SG_REL_ EOCM_F_HS SG_ 309 WSWshSwAtv 250;
BA_REL_ "GenSigSuprvResp" BU_SG_REL_ ACC_HS SG_ 309 WSWshSwAtv 1;
BA_REL_ "GenSigTimeoutMsg" BU_SG_REL_ ACC_HS SG_ 309 WSWshSwAtv 309;
BA_REL_ "GenSigTimeoutTime" BU_SG_REL_ ACC_HS SG_ 309 WSWshSwAtv 250;
BA_REL_ "GenSigSuprvResp" BU_SG_REL_ EOCM_F_HS SG_ 309 WSWprAct 2;
BA_REL_ "GenSigTimeoutMsg" BU_SG_REL_ EOCM_F_HS SG_ 309 WSWprAct 309;
BA_REL_ "GenSigTimeoutTime" BU_SG_REL_ EOCM_F_HS SG_ 309 WSWprAct 250;
BA_REL_ "GenSigSuprvResp" BU_SG_REL_ ACC_HS SG_ 309 WSWprAct 1;
BA_REL_ "GenSigTimeoutMsg" BU_SG_REL_ ACC_HS SG_ 309 WSWprAct 309;
BA_REL_ "GenSigTimeoutTime" BU_SG_REL_ ACC_HS SG_ 309 WSWprAct 250;
BA_REL_ "GenSigSuprvResp" BU_SG_REL_ CGM_HS SG_ 389 VSELongAccLoRes 1;
BA_REL_ "GenSigTimeoutMsg" BU_SG_REL_ CGM_HS SG_ 389 VSELongAccLoRes 389;
BA_REL_ "GenSigTimeoutTime" BU_SG_REL_ CGM_HS SG_ 389 VSELongAccLoRes 250;
BA_REL_ "GenSigSuprvResp" BU_SG_REL_ FCM_HS SG_ 389 VSELongAccLoRes 1;
BA_REL_ "GenSigTimeoutMsg" BU_SG_REL_ FCM_HS SG_ 389 VSELongAccLoRes 389;
BA_REL_ "GenSigTimeoutTime" BU_SG_REL_ FCM_HS SG_ 389 VSELongAccLoRes 250;
BA_REL_ "GenSigSuprvResp" BU_SG_REL_ VES_HS SG_ 389 VSELongAccLoRes 1;
BA_REL_ "GenSigTimeoutMsg" BU_SG_REL_ VES_HS SG_ 389 VSELongAccLoRes 389;
BA_REL_ "GenSigTimeoutTime" BU_SG_REL_ VES_HS SG_ 389 VSELongAccLoRes 250;
BA_REL_ "GenSigSuprvResp" BU_SG_REL_ ACC_HS SG_ 389 VSELongAccLoRes 1;
BA_REL_ "GenSigTimeoutMsg" BU_SG_REL_ ACC_HS SG_ 389 VSELongAccLoRes 389;
BA_REL_ "GenSigTimeoutTime" BU_SG_REL_ ACC_HS SG_ 389 VSELongAccLoRes 250;
BA_REL_ "GenSigSuprvResp" BU_SG_REL_ EPS_HS SG_ 389 StrAngSnsPolRat 1;
BA_REL_ "GenSigTimeoutMsg" BU_SG_REL_ EPS_HS SG_ 389 StrAngSnsPolRat 389;
BA_REL_ "GenSigTimeoutTime" BU_SG_REL_ EPS_HS SG_ 389 StrAngSnsPolRat 250;
BA_REL_ "GenSigSuprvResp" BU_SG_REL_ EPS_HS SG_ 389 LatAccSnsPolRat 1;
BA_REL_ "GenSigTimeoutMsg" BU_SG_REL_ EPS_HS SG_ 389 LatAccSnsPolRat 389;
BA_REL_ "GenSigTimeoutTime" BU_SG_REL_ EPS_HS SG_ 389 LatAccSnsPolRat 250;
BA_REL_ "GenSigSuprvResp" BU_SG_REL_ ICCM_HS SG_ 352 ShfFrmPrkAlwd 1;
BA_REL_ "GenSigTimeoutMsg" BU_SG_REL_ ICCM_HS SG_ 352 ShfFrmPrkAlwd 352;
BA_REL_ "GenSigTimeoutTime" BU_SG_REL_ ICCM_HS SG_ 352 ShfFrmPrkAlwd 250;
BA_REL_ "GenSigSuprvResp" BU_SG_REL_ EBCM_OBD_HS SG_ 352 AVHSwtchStats 1;
BA_REL_ "GenSigTimeoutMsg" BU_SG_REL_ EBCM_OBD_HS SG_ 352 AVHSwtchStats 352;
BA_REL_ "GenSigTimeoutTime" BU_SG_REL_ EBCM_OBD_HS SG_ 352 AVHSwtchStats 250;
BA_REL_ "GenSigSuprvResp" BU_SG_REL_ EBCM_HS SG_ 352 AVHSwtchStats 1;
BA_REL_ "GenSigTimeoutMsg" BU_SG_REL_ EBCM_HS SG_ 352 AVHSwtchStats 352;
BA_REL_ "GenSigTimeoutTime" BU_SG_REL_ EBCM_HS SG_ 352 AVHSwtchStats 250;
BA_REL_ "GenSigSuprvResp" BU_SG_REL_ CGM_HS SG_ 352 TeenDrvAct 1;
BA_REL_ "GenSigTimeoutMsg" BU_SG_REL_ CGM_HS SG_ 352 TeenDrvAct 352;
BA_REL_ "GenSigTimeoutTime" BU_SG_REL_ CGM_HS SG_ 352 TeenDrvAct 250;
BA_REL_ "GenSigSuprvResp" BU_SG_REL_ ALC_HS SG_ 352 TeenDrvAct 1;
BA_REL_ "GenSigTimeoutMsg" BU_SG_REL_ ALC_HS SG_ 352 TeenDrvAct 352;
BA_REL_ "GenSigTimeoutTime" BU_SG_REL_ ALC_HS SG_ 352 TeenDrvAct 250;
BA_REL_ "GenSigSuprvResp" BU_SG_REL_ EBCM_OBD_HS SG_ 352 TeenDrvAct 1;
BA_REL_ "GenSigTimeoutMsg" BU_SG_REL_ EBCM_OBD_HS SG_ 352 TeenDrvAct 352;
BA_REL_ "GenSigTimeoutTime" BU_SG_REL_ EBCM_OBD_HS SG_ 352 TeenDrvAct 250;
BA_REL_ "GenSigSuprvResp" BU_SG_REL_ EBCM_HS SG_ 352 TeenDrvAct 1;
BA_REL_ "GenSigTimeoutMsg" BU_SG_REL_ EBCM_HS SG_ 352 TeenDrvAct 352;
BA_REL_ "GenSigTimeoutTime" BU_SG_REL_ EBCM_HS SG_ 352 TeenDrvAct 250;
BA_REL_ "GenSigSuprvResp" BU_SG_REL_ AHL_AFL_HS SG_ 352 TeenDrvAct 1;
BA_REL_ "GenSigTimeoutMsg" BU_SG_REL_ AHL_AFL_HS SG_ 352 TeenDrvAct 352;
BA_REL_ "GenSigTimeoutTime" BU_SG_REL_ AHL_AFL_HS SG_ 352 TeenDrvAct 250;
BA_REL_ "GenSigSuprvResp" BU_SG_REL_ ACC_HS SG_ 352 TeenDrvAct 1;
BA_REL_ "GenSigTimeoutMsg" BU_SG_REL_ ACC_HS SG_ 352 TeenDrvAct 352;
BA_REL_ "GenSigTimeoutTime" BU_SG_REL_ ACC_HS SG_ 352 TeenDrvAct 250;
BA_REL_ "GenSigSuprvResp" BU_SG_REL_ ACC_HS SG_ 352 TeenDrvAct 1;
BA_REL_ "GenSigTimeoutMsg" BU_SG_REL_ ACC_HS SG_ 352 TeenDrvAct 352;
BA_REL_ "GenSigTimeoutTime" BU_SG_REL_ ACC_HS SG_ 352 TeenDrvAct 250;
BA_REL_ "GenSigSuprvResp" BU_SG_REL_ BCM_HS SG_ 562 SndPerfMdCsStAvl 1;
BA_REL_ "GenSigTimeoutMsg" BU_SG_REL_ BCM_HS SG_ 562 SndPerfMdCsStAvl 562;
BA_REL_ "GenSigTimeoutTime" BU_SG_REL_ BCM_HS SG_ 562 SndPerfMdCsStAvl 250;
BA_REL_ "GenSigSuprvResp" BU_SG_REL_ BCM_HS SG_ 562 SndPerfMdCsCrStVal 1;
BA_REL_ "GenSigTimeoutMsg" BU_SG_REL_ BCM_HS SG_ 562 SndPerfMdCsCrStVal 562;
BA_REL_ "GenSigTimeoutTime" BU_SG_REL_ BCM_HS SG_ 562 SndPerfMdCsCrStVal 250;
BA_REL_ "GenSigSuprvResp" BU_SG_REL_ BCM_HS SG_ 562 DispPerfMdCsStAvl 1;
BA_REL_ "GenSigTimeoutMsg" BU_SG_REL_ BCM_HS SG_ 562 DispPerfMdCsStAvl 562;
BA_REL_ "GenSigTimeoutTime" BU_SG_REL_ BCM_HS SG_ 562 DispPerfMdCsStAvl 250;
BA_REL_ "GenSigSuprvResp" BU_SG_REL_ BCM_HS SG_ 562 DispPerfMdCsCrStVal 1;
BA_REL_ "GenSigTimeoutMsg" BU_SG_REL_ BCM_HS SG_ 562 DispPerfMdCsCrStVal 562;
BA_REL_ "GenSigTimeoutTime" BU_SG_REL_ BCM_HS SG_ 562 DispPerfMdCsCrStVal 250;
BA_REL_ "GenSigSuprvResp" BU_SG_REL_ ICCM_OBD_HS SG_ 562 DrvlneMntsPerfMdRq 1;
BA_REL_ "GenSigTimeoutMsg" BU_SG_REL_ ICCM_OBD_HS SG_ 562 DrvlneMntsPerfMdRq 562;
BA_REL_ "GenSigTimeoutTime" BU_SG_REL_ ICCM_OBD_HS SG_ 562 DrvlneMntsPerfMdRq 250;
BA_REL_ "GenSigSuprvResp" BU_SG_REL_ ICCM_HS SG_ 562 DrvlneMntsPerfMdRq 1;
BA_REL_ "GenSigTimeoutMsg" BU_SG_REL_ ICCM_HS SG_ 562 DrvlneMntsPerfMdRq 562;
BA_REL_ "GenSigTimeoutTime" BU_SG_REL_ ICCM_HS SG_ 562 DrvlneMntsPerfMdRq 250;
BA_REL_ "GenSigSuprvResp" BU_SG_REL_ SADS_HS SG_ 562 RideCntrlPerfMdRq 1;
BA_REL_ "GenSigTimeoutMsg" BU_SG_REL_ SADS_HS SG_ 562 RideCntrlPerfMdRq 562;
BA_REL_ "GenSigTimeoutTime" BU_SG_REL_ SADS_HS SG_ 562 RideCntrlPerfMdRq 250;
BA_REL_ "GenSigSuprvResp" BU_SG_REL_ EOCM_F_HS SG_ 562 StgSysPerfMdRq 1;
BA_REL_ "GenSigTimeoutMsg" BU_SG_REL_ EOCM_F_HS SG_ 562 StgSysPerfMdRq 562;
BA_REL_ "GenSigTimeoutTime" BU_SG_REL_ EOCM_F_HS SG_ 562 StgSysPerfMdRq 250;
BA_REL_ "GenSigSuprvResp" BU_SG_REL_ FCM_HS SG_ 562 StgSysPerfMdRq 1;
BA_REL_ "GenSigTimeoutMsg" BU_SG_REL_ FCM_HS SG_ 562 StgSysPerfMdRq 562;
BA_REL_ "GenSigTimeoutTime" BU_SG_REL_ FCM_HS SG_ 562 StgSysPerfMdRq 250;
BA_REL_ "GenSigSuprvResp" BU_SG_REL_ VES_HS SG_ 562 StgSysPerfMdRq 1;
BA_REL_ "GenSigTimeoutMsg" BU_SG_REL_ VES_HS SG_ 562 StgSysPerfMdRq 562;
BA_REL_ "GenSigTimeoutTime" BU_SG_REL_ VES_HS SG_ 562 StgSysPerfMdRq 250;
BA_REL_ "GenSigSuprvResp" BU_SG_REL_ EPS_HS SG_ 562 StgSysPerfMdRq 1;
BA_REL_ "GenSigTimeoutMsg" BU_SG_REL_ EPS_HS SG_ 562 StgSysPerfMdRq 562;
BA_REL_ "GenSigTimeoutTime" BU_SG_REL_ EPS_HS SG_ 562 StgSysPerfMdRq 250;
BA_REL_ "GenSigSuprvResp" BU_SG_REL_ ICCM_OBD_HS SG_ 562 DiffPerfMdRq 1;
BA_REL_ "GenSigTimeoutMsg" BU_SG_REL_ ICCM_OBD_HS SG_ 562 DiffPerfMdRq 562;
BA_REL_ "GenSigTimeoutTime" BU_SG_REL_ ICCM_OBD_HS SG_ 562 DiffPerfMdRq 250;
BA_REL_ "GenSigSuprvResp" BU_SG_REL_ ICCM_HS SG_ 562 DiffPerfMdRq 1;
BA_REL_ "GenSigTimeoutMsg" BU_SG_REL_ ICCM_HS SG_ 562 DiffPerfMdRq 562;
BA_REL_ "GenSigTimeoutTime" BU_SG_REL_ ICCM_HS SG_ 562 DiffPerfMdRq 250;
BA_REL_ "GenSigSuprvResp" BU_SG_REL_ BCM_HS SG_ 562 SndEnhcmtPerfMdRq 1;
BA_REL_ "GenSigTimeoutMsg" BU_SG_REL_ BCM_HS SG_ 562 SndEnhcmtPerfMdRq 562;
BA_REL_ "GenSigTimeoutTime" BU_SG_REL_ BCM_HS SG_ 562 SndEnhcmtPerfMdRq 250;
BA_REL_ "GenSigSuprvResp" BU_SG_REL_ AMP_HS SG_ 562 SndEnhcmtPerfMdRq 1;
BA_REL_ "GenSigTimeoutMsg" BU_SG_REL_ AMP_HS SG_ 562 SndEnhcmtPerfMdRq 562;
BA_REL_ "GenSigTimeoutTime" BU_SG_REL_ AMP_HS SG_ 562 SndEnhcmtPerfMdRq 250;
BA_REL_ "GenSigSuprvResp" BU_SG_REL_ BCM_HS SG_ 562 DsplyPerfMdRq 1;
BA_REL_ "GenSigTimeoutMsg" BU_SG_REL_ BCM_HS SG_ 562 DsplyPerfMdRq 562;
BA_REL_ "GenSigTimeoutTime" BU_SG_REL_ BCM_HS SG_ 562 DsplyPerfMdRq 250;
BA_REL_ "GenSigSuprvResp" BU_SG_REL_ ICCM_OBD_HS SG_ 562 ExhstPerfMdRq 1;
BA_REL_ "GenSigTimeoutMsg" BU_SG_REL_ ICCM_OBD_HS SG_ 562 ExhstPerfMdRq 562;
BA_REL_ "GenSigTimeoutTime" BU_SG_REL_ ICCM_OBD_HS SG_ 562 ExhstPerfMdRq 250;
BA_REL_ "GenSigSuprvResp" BU_SG_REL_ ICCM_HS SG_ 562 ExhstPerfMdRq 1;
BA_REL_ "GenSigTimeoutMsg" BU_SG_REL_ ICCM_HS SG_ 562 ExhstPerfMdRq 562;
BA_REL_ "GenSigTimeoutTime" BU_SG_REL_ ICCM_HS SG_ 562 ExhstPerfMdRq 250;
BA_REL_ "GenSigSuprvResp" BU_SG_REL_ EOCM_F_HS SG_ 562 DrvMdCntrlState 1;
BA_REL_ "GenSigTimeoutMsg" BU_SG_REL_ EOCM_F_HS SG_ 562 DrvMdCntrlState 562;
BA_REL_ "GenSigTimeoutTime" BU_SG_REL_ EOCM_F_HS SG_ 562 DrvMdCntrlState 250;
BA_REL_ "GenSigSuprvResp" BU_SG_REL_ FCM_HS SG_ 562 DrvMdCntrlState 1;
BA_REL_ "GenSigTimeoutMsg" BU_SG_REL_ FCM_HS SG_ 562 DrvMdCntrlState 562;
BA_REL_ "GenSigTimeoutTime" BU_SG_REL_ FCM_HS SG_ 562 DrvMdCntrlState 250;
BA_REL_ "GenSigSuprvResp" BU_SG_REL_ SADS_HS SG_ 562 DrvMdCntrlState 1;
BA_REL_ "GenSigTimeoutMsg" BU_SG_REL_ SADS_HS SG_ 562 DrvMdCntrlState 562;
BA_REL_ "GenSigTimeoutTime" BU_SG_REL_ SADS_HS SG_ 562 DrvMdCntrlState 250;
BA_REL_ "GenSigSuprvResp" BU_SG_REL_ RDCM_HS SG_ 562 AWDPerfMdRq 1;
BA_REL_ "GenSigTimeoutMsg" BU_SG_REL_ RDCM_HS SG_ 562 AWDPerfMdRq 562;
BA_REL_ "GenSigTimeoutTime" BU_SG_REL_ RDCM_HS SG_ 562 AWDPerfMdRq 250;
BA_REL_ "GenSigSuprvResp" BU_SG_REL_ TCCM_HS SG_ 562 AWDPerfMdRq 1;
BA_REL_ "GenSigTimeoutMsg" BU_SG_REL_ TCCM_HS SG_ 562 AWDPerfMdRq 562;
BA_REL_ "GenSigTimeoutTime" BU_SG_REL_ TCCM_HS SG_ 562 AWDPerfMdRq 250;
BA_REL_ "GenSigSuprvResp" BU_SG_REL_ BCM_HS SG_ 386 AHAct 1;
BA_REL_ "GenSigTimeoutMsg" BU_SG_REL_ BCM_HS SG_ 386 AHAct 386;
BA_REL_ "GenSigTimeoutTime" BU_SG_REL_ BCM_HS SG_ 386 AHAct 250;
BA_REL_ "GenSigSuprvResp" BU_SG_REL_ BCM_HS SG_ 386 AHEnbld 1;
BA_REL_ "GenSigTimeoutMsg" BU_SG_REL_ BCM_HS SG_ 386 AHEnbld 386;
BA_REL_ "GenSigTimeoutTime" BU_SG_REL_ BCM_HS SG_ 386 AHEnbld 250;
BA_REL_ "GenSigSuprvResp" BU_SG_REL_ BCM_HS SG_ 386 AHServcIO 1;
BA_REL_ "GenSigTimeoutMsg" BU_SG_REL_ BCM_HS SG_ 386 AHServcIO 386;
BA_REL_ "GenSigTimeoutTime" BU_SG_REL_ BCM_HS SG_ 386 AHServcIO 250;
BA_REL_ "GenSigSuprvResp" BU_SG_REL_ BCM_HS SG_ 386 AHAppBrkPedlIO 1;
BA_REL_ "GenSigTimeoutMsg" BU_SG_REL_ BCM_HS SG_ 386 AHAppBrkPedlIO 386;
BA_REL_ "GenSigTimeoutTime" BU_SG_REL_ BCM_HS SG_ 386 AHAppBrkPedlIO 250;
BA_REL_ "GenSigSuprvResp" BU_SG_REL_ BCM_HS SG_ 386 AHDisbldStbltIO 1;
BA_REL_ "GenSigTimeoutMsg" BU_SG_REL_ BCM_HS SG_ 386 AHDisbldStbltIO 386;
BA_REL_ "GenSigTimeoutTime" BU_SG_REL_ BCM_HS SG_ 386 AHDisbldStbltIO 250;
BA_REL_ "GenSigSuprvResp" BU_SG_REL_ BCM_HS SG_ 386 AHDisbldDrOpnIO 1;
BA_REL_ "GenSigTimeoutMsg" BU_SG_REL_ BCM_HS SG_ 386 AHDisbldDrOpnIO 386;
BA_REL_ "GenSigTimeoutTime" BU_SG_REL_ BCM_HS SG_ 386 AHDisbldDrOpnIO 250;
BA_REL_ "GenSigSuprvResp" BU_SG_REL_ BCM_HS SG_ 386 PMVSS_Disps 1;
BA_REL_ "GenSigTimeoutMsg" BU_SG_REL_ BCM_HS SG_ 386 PMVSS_Disps 386;
BA_REL_ "GenSigTimeoutTime" BU_SG_REL_ BCM_HS SG_ 386 PMVSS_Disps 250;
BA_REL_ "GenSigSuprvResp" BU_SG_REL_ BCM_HS SG_ 386 PMVSS_Exhst 1;
BA_REL_ "GenSigTimeoutMsg" BU_SG_REL_ BCM_HS SG_ 386 PMVSS_Exhst 386;
BA_REL_ "GenSigTimeoutTime" BU_SG_REL_ BCM_HS SG_ 386 PMVSS_Exhst 250;
BA_REL_ "GenSigSuprvResp" BU_SG_REL_ BCM_HS SG_ 386 PMVSS_PsngrSeat 1;
BA_REL_ "GenSigTimeoutMsg" BU_SG_REL_ BCM_HS SG_ 386 PMVSS_PsngrSeat 386;
BA_REL_ "GenSigTimeoutTime" BU_SG_REL_ BCM_HS SG_ 386 PMVSS_PsngrSeat 250;
BA_REL_ "GenSigSuprvResp" BU_SG_REL_ BCM_HS SG_ 386 PMVSS_DrvrSeat 1;
BA_REL_ "GenSigTimeoutMsg" BU_SG_REL_ BCM_HS SG_ 386 PMVSS_DrvrSeat 386;
BA_REL_ "GenSigTimeoutTime" BU_SG_REL_ BCM_HS SG_ 386 PMVSS_DrvrSeat 250;
BA_REL_ "GenSigSuprvResp" BU_SG_REL_ BCM_HS SG_ 386 PMVSS_AdptCrsCnt 1;
BA_REL_ "GenSigTimeoutMsg" BU_SG_REL_ BCM_HS SG_ 386 PMVSS_AdptCrsCnt 386;
BA_REL_ "GenSigTimeoutTime" BU_SG_REL_ BCM_HS SG_ 386 PMVSS_AdptCrsCnt 250;
BA_REL_ "GenSigSuprvResp" BU_SG_REL_ BCM_HS SG_ 386 PMVSS_Drvln 1;
BA_REL_ "GenSigTimeoutMsg" BU_SG_REL_ BCM_HS SG_ 386 PMVSS_Drvln 386;
BA_REL_ "GenSigTimeoutTime" BU_SG_REL_ BCM_HS SG_ 386 PMVSS_Drvln 250;
BA_REL_ "GenSigSuprvResp" BU_SG_REL_ BCM_HS SG_ 386 PMVSS_Susp 1;
BA_REL_ "GenSigTimeoutMsg" BU_SG_REL_ BCM_HS SG_ 386 PMVSS_Susp 386;
BA_REL_ "GenSigTimeoutTime" BU_SG_REL_ BCM_HS SG_ 386 PMVSS_Susp 250;
BA_REL_ "GenSigSuprvResp" BU_SG_REL_ BCM_HS SG_ 386 PMVSS_Strng 1;
BA_REL_ "GenSigTimeoutMsg" BU_SG_REL_ BCM_HS SG_ 386 PMVSS_Strng 386;
BA_REL_ "GenSigTimeoutTime" BU_SG_REL_ BCM_HS SG_ 386 PMVSS_Strng 250;
BA_REL_ "GenSigSuprvResp" BU_SG_REL_ BCM_HS SG_ 386 PMVSS_Trans 1;
BA_REL_ "GenSigTimeoutMsg" BU_SG_REL_ BCM_HS SG_ 386 PMVSS_Trans 386;
BA_REL_ "GenSigTimeoutTime" BU_SG_REL_ BCM_HS SG_ 386 PMVSS_Trans 250;
BA_REL_ "GenSigSuprvResp" BU_SG_REL_ BCM_HS SG_ 386 PMVSS_Eng 1;
BA_REL_ "GenSigTimeoutMsg" BU_SG_REL_ BCM_HS SG_ 386 PMVSS_Eng 386;
BA_REL_ "GenSigTimeoutTime" BU_SG_REL_ BCM_HS SG_ 386 PMVSS_Eng 250;
BA_REL_ "GenSigSuprvResp" BU_SG_REL_ BCM_HS SG_ 386 PMVSS_Snd 1;
BA_REL_ "GenSigTimeoutMsg" BU_SG_REL_ BCM_HS SG_ 386 PMVSS_Snd 386;
BA_REL_ "GenSigTimeoutTime" BU_SG_REL_ BCM_HS SG_ 386 PMVSS_Snd 250;
BA_REL_ "GenSigSuprvResp" BU_SG_REL_ EOCM_F_HS SG_ 386 AdptCruzCtrlStg 1;
BA_REL_ "GenSigTimeoutMsg" BU_SG_REL_ EOCM_F_HS SG_ 386 AdptCruzCtrlStg 386;
BA_REL_ "GenSigTimeoutTime" BU_SG_REL_ EOCM_F_HS SG_ 386 AdptCruzCtrlStg 250;
BA_REL_ "GenSigSuprvResp" BU_SG_REL_ ACC_HS SG_ 386 AdptCruzCtrlStg 1;
BA_REL_ "GenSigTimeoutMsg" BU_SG_REL_ ACC_HS SG_ 386 AdptCruzCtrlStg 386;
BA_REL_ "GenSigTimeoutTime" BU_SG_REL_ ACC_HS SG_ 386 AdptCruzCtrlStg 250;
BA_REL_ "GenSigSuprvResp" BU_SG_REL_ EPS_HS SG_ 532 RedntVSEAct 1;
BA_REL_ "GenSigTimeoutMsg" BU_SG_REL_ EPS_HS SG_ 532 RedntVSEAct 532;
BA_REL_ "GenSigTimeoutTime" BU_SG_REL_ EPS_HS SG_ 532 RedntVSEAct 250;
BA_REL_ "GenSigSuprvResp" BU_SG_REL_ ICCM_OBD_HS SG_ 532 RedntVSEAct 1;
BA_REL_ "GenSigTimeoutMsg" BU_SG_REL_ ICCM_OBD_HS SG_ 532 RedntVSEAct 532;
BA_REL_ "GenSigTimeoutTime" BU_SG_REL_ ICCM_OBD_HS SG_ 532 RedntVSEAct 125;
BA_REL_ "GenSigSuprvResp" BU_SG_REL_ ICCM_HS SG_ 532 RedntVSEAct 1;
BA_REL_ "GenSigTimeoutMsg" BU_SG_REL_ ICCM_HS SG_ 532 RedntVSEAct 532;
BA_REL_ "GenSigTimeoutTime" BU_SG_REL_ ICCM_HS SG_ 532 RedntVSEAct 125;
BA_REL_ "GenSigSuprvResp" BU_SG_REL_ BCM_HS SG_ 532 HilRlbkCtrlActIO 1;
BA_REL_ "GenSigTimeoutMsg" BU_SG_REL_ BCM_HS SG_ 532 HilRlbkCtrlActIO 532;
BA_REL_ "GenSigTimeoutTime" BU_SG_REL_ BCM_HS SG_ 532 HilRlbkCtrlActIO 250;
BA_REL_ "GenSigSuprvResp" BU_SG_REL_ CGM_HS SG_ 532 VehHldDrvrDsblActvFlg 1;
BA_REL_ "GenSigTimeoutMsg" BU_SG_REL_ CGM_HS SG_ 532 VehHldDrvrDsblActvFlg 532;
BA_REL_ "GenSigTimeoutTime" BU_SG_REL_ CGM_HS SG_ 532 VehHldDrvrDsblActvFlg 250;
BA_REL_ "GenSigSuprvResp" BU_SG_REL_ EPB_HS SG_ 532 VehHldDrvrDsblActvFlg 1;
BA_REL_ "GenSigTimeoutMsg" BU_SG_REL_ EPB_HS SG_ 532 VehHldDrvrDsblActvFlg 532;
BA_REL_ "GenSigTimeoutTime" BU_SG_REL_ EPB_HS SG_ 532 VehHldDrvrDsblActvFlg 250;
BA_REL_ "GenSigSuprvResp" BU_SG_REL_ FCM_HS SG_ 532 AutoBrkngAvlbl 1;
BA_REL_ "GenSigTimeoutMsg" BU_SG_REL_ FCM_HS SG_ 532 AutoBrkngAvlbl 532;
BA_REL_ "GenSigTimeoutTime" BU_SG_REL_ FCM_HS SG_ 532 AutoBrkngAvlbl 250;
BA_REL_ "GenSigSuprvResp" BU_SG_REL_ EPS_HS SG_ 532 AutoBrkngAvlbl 1;
BA_REL_ "GenSigTimeoutMsg" BU_SG_REL_ EPS_HS SG_ 532 AutoBrkngAvlbl 532;
BA_REL_ "GenSigTimeoutTime" BU_SG_REL_ EPS_HS SG_ 532 AutoBrkngAvlbl 250;
BA_REL_ "GenSigSuprvResp" BU_SG_REL_ EOCM_F_HS SG_ 532 AutoBrkngAvlbl 1;
BA_REL_ "GenSigTimeoutMsg" BU_SG_REL_ EOCM_F_HS SG_ 532 AutoBrkngAvlbl 532;
BA_REL_ "GenSigTimeoutTime" BU_SG_REL_ EOCM_F_HS SG_ 532 AutoBrkngAvlbl 250;
BA_REL_ "GenSigSuprvResp" BU_SG_REL_ ICCM_OBD_HS SG_ 532 ABSActvProtPVal 1;
BA_REL_ "GenSigTimeoutMsg" BU_SG_REL_ ICCM_OBD_HS SG_ 532 ABSActvProtPVal 532;
BA_REL_ "GenSigTimeoutTime" BU_SG_REL_ ICCM_OBD_HS SG_ 532 ABSActvProtPVal 125;
BA_REL_ "GenSigSuprvResp" BU_SG_REL_ ICCM_HS SG_ 532 ABSActvProtPVal 1;
BA_REL_ "GenSigTimeoutMsg" BU_SG_REL_ ICCM_HS SG_ 532 ABSActvProtPVal 532;
BA_REL_ "GenSigTimeoutTime" BU_SG_REL_ ICCM_HS SG_ 532 ABSActvProtPVal 125;
BA_REL_ "GenSigSuprvResp" BU_SG_REL_ ICCM_OBD_HS SG_ 532 ABSActvProtARC 1;
BA_REL_ "GenSigTimeoutMsg" BU_SG_REL_ ICCM_OBD_HS SG_ 532 ABSActvProtARC 532;
BA_REL_ "GenSigTimeoutTime" BU_SG_REL_ ICCM_OBD_HS SG_ 532 ABSActvProtARC 125;
BA_REL_ "GenSigSuprvResp" BU_SG_REL_ ICCM_HS SG_ 532 ABSActvProtARC 1;
BA_REL_ "GenSigTimeoutMsg" BU_SG_REL_ ICCM_HS SG_ 532 ABSActvProtARC 532;
BA_REL_ "GenSigTimeoutTime" BU_SG_REL_ ICCM_HS SG_ 532 ABSActvProtARC 125;
BA_REL_ "GenSigSuprvResp" BU_SG_REL_ EPS_HS SG_ 532 ABSActvProt 1;
BA_REL_ "GenSigTimeoutMsg" BU_SG_REL_ EPS_HS SG_ 532 ABSActvProt 532;
BA_REL_ "GenSigTimeoutTime" BU_SG_REL_ EPS_HS SG_ 532 ABSActvProt 250;
BA_REL_ "GenSigSuprvResp" BU_SG_REL_ EOCM_F_HS SG_ 532 ABSActvProt 1;
BA_REL_ "GenSigTimeoutMsg" BU_SG_REL_ EOCM_F_HS SG_ 532 ABSActvProt 532;
BA_REL_ "GenSigTimeoutTime" BU_SG_REL_ EOCM_F_HS SG_ 532 ABSActvProt 250;
BA_REL_ "GenSigSuprvResp" BU_SG_REL_ ICCM_OBD_HS SG_ 532 ABSActvProt 1;
BA_REL_ "GenSigTimeoutMsg" BU_SG_REL_ ICCM_OBD_HS SG_ 532 ABSActvProt 532;
BA_REL_ "GenSigTimeoutTime" BU_SG_REL_ ICCM_OBD_HS SG_ 532 ABSActvProt 125;
BA_REL_ "GenSigSuprvResp" BU_SG_REL_ ICCM_HS SG_ 532 ABSActvProt 1;
BA_REL_ "GenSigTimeoutMsg" BU_SG_REL_ ICCM_HS SG_ 532 ABSActvProt 532;
BA_REL_ "GenSigTimeoutTime" BU_SG_REL_ ICCM_HS SG_ 532 ABSActvProt 125;
BA_REL_ "GenSigSuprvResp" BU_SG_REL_ FCM_HS SG_ 532 BrkSysAutBrkFld 1;
BA_REL_ "GenSigTimeoutMsg" BU_SG_REL_ FCM_HS SG_ 532 BrkSysAutBrkFld 532;
BA_REL_ "GenSigTimeoutTime" BU_SG_REL_ FCM_HS SG_ 532 BrkSysAutBrkFld 250;
BA_REL_ "GenSigSuprvResp" BU_SG_REL_ EPB_HS SG_ 532 BrkSysAutBrkFld 1;
BA_REL_ "GenSigTimeoutMsg" BU_SG_REL_ EPB_HS SG_ 532 BrkSysAutBrkFld 532;
BA_REL_ "GenSigTimeoutTime" BU_SG_REL_ EPB_HS SG_ 532 BrkSysAutBrkFld 250;
BA_REL_ "GenSigSuprvResp" BU_SG_REL_ ACC_HS SG_ 532 BrkSysAutBrkFld 1;
BA_REL_ "GenSigTimeoutMsg" BU_SG_REL_ ACC_HS SG_ 532 BrkSysAutBrkFld 532;
BA_REL_ "GenSigTimeoutTime" BU_SG_REL_ ACC_HS SG_ 532 BrkSysAutBrkFld 250;
BA_REL_ "GenSigSuprvResp" BU_SG_REL_ BCM_HS SG_ 532 BrkSysMalFuncIndOn 1;
BA_REL_ "GenSigTimeoutMsg" BU_SG_REL_ BCM_HS SG_ 532 BrkSysMalFuncIndOn 532;
BA_REL_ "GenSigTimeoutTime" BU_SG_REL_ BCM_HS SG_ 532 BrkSysMalFuncIndOn 300;
BA_REL_ "GenSigSuprvResp" BU_SG_REL_ FCM_HS SG_ 532 BrkPdDrvAPrsStaPVal 1;
BA_REL_ "GenSigTimeoutMsg" BU_SG_REL_ FCM_HS SG_ 532 BrkPdDrvAPrsStaPVal 532;
BA_REL_ "GenSigTimeoutTime" BU_SG_REL_ FCM_HS SG_ 532 BrkPdDrvAPrsStaPVal 250;
BA_REL_ "GenSigSuprvResp" BU_SG_REL_ ICCM_OBD_HS SG_ 532 BrkPdDrvAPrsStaPVal 1;
BA_REL_ "GenSigTimeoutMsg" BU_SG_REL_ ICCM_OBD_HS SG_ 532 BrkPdDrvAPrsStaPVal 532;
BA_REL_ "GenSigTimeoutTime" BU_SG_REL_ ICCM_OBD_HS SG_ 532 BrkPdDrvAPrsStaPVal 250;
BA_REL_ "GenSigSuprvResp" BU_SG_REL_ ICCM_HS SG_ 532 BrkPdDrvAPrsStaPVal 1;
BA_REL_ "GenSigTimeoutMsg" BU_SG_REL_ ICCM_HS SG_ 532 BrkPdDrvAPrsStaPVal 532;
BA_REL_ "GenSigTimeoutTime" BU_SG_REL_ ICCM_HS SG_ 532 BrkPdDrvAPrsStaPVal 250;
BA_REL_ "GenSigSuprvResp" BU_SG_REL_ FCM_HS SG_ 532 BPDAPS_BkPDrvApPV 1;
BA_REL_ "GenSigTimeoutMsg" BU_SG_REL_ FCM_HS SG_ 532 BPDAPS_BkPDrvApPV 532;
BA_REL_ "GenSigTimeoutTime" BU_SG_REL_ FCM_HS SG_ 532 BPDAPS_BkPDrvApPV 250;
BA_REL_ "GenSigSuprvResp" BU_SG_REL_ ICCM_OBD_HS SG_ 532 BPDAPS_BkPDrvApPV 1;
BA_REL_ "GenSigTimeoutMsg" BU_SG_REL_ ICCM_OBD_HS SG_ 532 BPDAPS_BkPDrvApPV 532;
BA_REL_ "GenSigTimeoutTime" BU_SG_REL_ ICCM_OBD_HS SG_ 532 BPDAPS_BkPDrvApPV 250;
BA_REL_ "GenSigSuprvResp" BU_SG_REL_ ICCM_HS SG_ 532 BPDAPS_BkPDrvApPV 1;
BA_REL_ "GenSigTimeoutMsg" BU_SG_REL_ ICCM_HS SG_ 532 BPDAPS_BkPDrvApPV 532;
BA_REL_ "GenSigTimeoutTime" BU_SG_REL_ ICCM_HS SG_ 532 BPDAPS_BkPDrvApPV 250;
BA_REL_ "GenSigSuprvResp" BU_SG_REL_ ACC_HS SG_ 532 BPDAPS_BkPDrvApPV 1;
BA_REL_ "GenSigTimeoutMsg" BU_SG_REL_ ACC_HS SG_ 532 BPDAPS_BkPDrvApPV 532;
BA_REL_ "GenSigTimeoutTime" BU_SG_REL_ ACC_HS SG_ 532 BPDAPS_BkPDrvApPV 250;
BA_REL_ "GenSigSuprvResp" BU_SG_REL_ SADS_HS SG_ 532 BPDAPS_BkPDrvApPV 1;
BA_REL_ "GenSigTimeoutMsg" BU_SG_REL_ SADS_HS SG_ 532 BPDAPS_BkPDrvApPV 532;
BA_REL_ "GenSigTimeoutTime" BU_SG_REL_ SADS_HS SG_ 532 BPDAPS_BkPDrvApPV 250;
BA_REL_ "GenSigSuprvResp" BU_SG_REL_ EPB_HS SG_ 532 BPDAPS_BkPDrvApPV 1;
BA_REL_ "GenSigTimeoutMsg" BU_SG_REL_ EPB_HS SG_ 532 BPDAPS_BkPDrvApPV 532;
BA_REL_ "GenSigTimeoutTime" BU_SG_REL_ EPB_HS SG_ 532 BPDAPS_BkPDrvApPV 250;
BA_REL_ "GenSigSuprvResp" BU_SG_REL_ EPB_HS SG_ 532 BPDAPS_BkPDrvApPV 1;
BA_REL_ "GenSigTimeoutMsg" BU_SG_REL_ EPB_HS SG_ 532 BPDAPS_BkPDrvApPV 532;
BA_REL_ "GenSigTimeoutTime" BU_SG_REL_ EPB_HS SG_ 532 BPDAPS_BkPDrvApPV 250;
BA_REL_ "GenSigSuprvResp" BU_SG_REL_ FCM_HS SG_ 532 BPDAPS_BkPDrvApP 1;
BA_REL_ "GenSigTimeoutMsg" BU_SG_REL_ FCM_HS SG_ 532 BPDAPS_BkPDrvApP 532;
BA_REL_ "GenSigTimeoutTime" BU_SG_REL_ FCM_HS SG_ 532 BPDAPS_BkPDrvApP 250;
BA_REL_ "GenSigSuprvResp" BU_SG_REL_ ICCM_OBD_HS SG_ 532 BPDAPS_BkPDrvApP 1;
BA_REL_ "GenSigTimeoutMsg" BU_SG_REL_ ICCM_OBD_HS SG_ 532 BPDAPS_BkPDrvApP 532;
BA_REL_ "GenSigTimeoutTime" BU_SG_REL_ ICCM_OBD_HS SG_ 532 BPDAPS_BkPDrvApP 250;
BA_REL_ "GenSigSuprvResp" BU_SG_REL_ ICCM_HS SG_ 532 BPDAPS_BkPDrvApP 1;
BA_REL_ "GenSigTimeoutMsg" BU_SG_REL_ ICCM_HS SG_ 532 BPDAPS_BkPDrvApP 532;
BA_REL_ "GenSigTimeoutTime" BU_SG_REL_ ICCM_HS SG_ 532 BPDAPS_BkPDrvApP 250;
BA_REL_ "GenSigSuprvResp" BU_SG_REL_ ACC_HS SG_ 532 BPDAPS_BkPDrvApP 1;
BA_REL_ "GenSigTimeoutMsg" BU_SG_REL_ ACC_HS SG_ 532 BPDAPS_BkPDrvApP 532;
BA_REL_ "GenSigTimeoutTime" BU_SG_REL_ ACC_HS SG_ 532 BPDAPS_BkPDrvApP 250;
BA_REL_ "GenSigSuprvResp" BU_SG_REL_ SADS_HS SG_ 532 BPDAPS_BkPDrvApP 1;
BA_REL_ "GenSigTimeoutMsg" BU_SG_REL_ SADS_HS SG_ 532 BPDAPS_BkPDrvApP 532;
BA_REL_ "GenSigTimeoutTime" BU_SG_REL_ SADS_HS SG_ 532 BPDAPS_BkPDrvApP 250;
BA_REL_ "GenSigSuprvResp" BU_SG_REL_ EPB_HS SG_ 532 BPDAPS_BkPDrvApP 1;
BA_REL_ "GenSigTimeoutMsg" BU_SG_REL_ EPB_HS SG_ 532 BPDAPS_BkPDrvApP 532;
BA_REL_ "GenSigTimeoutTime" BU_SG_REL_ EPB_HS SG_ 532 BPDAPS_BkPDrvApP 250;
BA_REL_ "GenSigSuprvResp" BU_SG_REL_ EPB_HS SG_ 532 BPDAPS_BkPDrvApP 1;
BA_REL_ "GenSigTimeoutMsg" BU_SG_REL_ EPB_HS SG_ 532 BPDAPS_BkPDrvApP 532;
BA_REL_ "GenSigTimeoutTime" BU_SG_REL_ EPB_HS SG_ 532 BPDAPS_BkPDrvApP 250;
BA_REL_ "GenSigSuprvResp" BU_SG_REL_ FCM_HS SG_ 532 BrkPdDrvAppPrsAlRC 1;
BA_REL_ "GenSigTimeoutMsg" BU_SG_REL_ FCM_HS SG_ 532 BrkPdDrvAppPrsAlRC 532;
BA_REL_ "GenSigTimeoutTime" BU_SG_REL_ FCM_HS SG_ 532 BrkPdDrvAppPrsAlRC 250;
BA_REL_ "GenSigSuprvResp" BU_SG_REL_ EOCM_F_HS SG_ 532 BrkPdDrvAppPrsAlRC 1;
BA_REL_ "GenSigTimeoutMsg" BU_SG_REL_ EOCM_F_HS SG_ 532 BrkPdDrvAppPrsAlRC 532;
BA_REL_ "GenSigTimeoutTime" BU_SG_REL_ EOCM_F_HS SG_ 532 BrkPdDrvAppPrsAlRC 120;
BA_REL_ "GenSigSuprvResp" BU_SG_REL_ ICCM_OBD_HS SG_ 532 BrkPdDrvAppPrsAlRC 1;
BA_REL_ "GenSigTimeoutMsg" BU_SG_REL_ ICCM_OBD_HS SG_ 532 BrkPdDrvAppPrsAlRC 532;
BA_REL_ "GenSigTimeoutTime" BU_SG_REL_ ICCM_OBD_HS SG_ 532 BrkPdDrvAppPrsAlRC 250;
BA_REL_ "GenSigSuprvResp" BU_SG_REL_ ICCM_HS SG_ 532 BrkPdDrvAppPrsAlRC 1;
BA_REL_ "GenSigTimeoutMsg" BU_SG_REL_ ICCM_HS SG_ 532 BrkPdDrvAppPrsAlRC 532;
BA_REL_ "GenSigTimeoutTime" BU_SG_REL_ ICCM_HS SG_ 532 BrkPdDrvAppPrsAlRC 250;
BA_REL_ "GenSigSuprvResp" BU_SG_REL_ ICCM_OBD_HS SG_ 532 AutoBrkngAct 1;
BA_REL_ "GenSigTimeoutMsg" BU_SG_REL_ ICCM_OBD_HS SG_ 532 AutoBrkngAct 532;
BA_REL_ "GenSigTimeoutTime" BU_SG_REL_ ICCM_OBD_HS SG_ 532 AutoBrkngAct 125;
BA_REL_ "GenSigSuprvResp" BU_SG_REL_ ICCM_HS SG_ 532 AutoBrkngAct 1;
BA_REL_ "GenSigTimeoutMsg" BU_SG_REL_ ICCM_HS SG_ 532 AutoBrkngAct 532;
BA_REL_ "GenSigTimeoutTime" BU_SG_REL_ ICCM_HS SG_ 532 AutoBrkngAct 125;
BA_REL_ "GenSigSuprvResp" BU_SG_REL_ EPB_HS SG_ 532 AutoBrkngAct 1;
BA_REL_ "GenSigTimeoutMsg" BU_SG_REL_ EPB_HS SG_ 532 AutoBrkngAct 532;
BA_REL_ "GenSigTimeoutTime" BU_SG_REL_ EPB_HS SG_ 532 AutoBrkngAct 250;
BA_REL_ "GenSigSuprvResp" BU_SG_REL_ ACC_HS SG_ 532 AutoBrkngAct 1;
BA_REL_ "GenSigTimeoutMsg" BU_SG_REL_ ACC_HS SG_ 532 AutoBrkngAct 532;
BA_REL_ "GenSigTimeoutTime" BU_SG_REL_ ACC_HS SG_ 532 AutoBrkngAct 250;
BA_REL_ "GenSigVBitResp" BU_SG_REL_ BCM_HS SG_ 532 BrkFldLvlLw 1;
BA_REL_ "GenSigSuprvResp" BU_SG_REL_ BCM_HS SG_ 532 BrkFldLvlLw 1;
BA_REL_ "GenSigTimeoutMsg" BU_SG_REL_ BCM_HS SG_ 532 BrkFldLvlLw 532;
BA_REL_ "GenSigTimeoutTime" BU_SG_REL_ BCM_HS SG_ 532 BrkFldLvlLw 300;
BA_REL_ "GenSigSuprvResp" BU_SG_REL_ BCM_HS SG_ 328 StrngAsstRdcdIO 1;
BA_REL_ "GenSigTimeoutMsg" BU_SG_REL_ BCM_HS SG_ 328 StrngAsstRdcdIO 328;
BA_REL_ "GenSigTimeoutTime" BU_SG_REL_ BCM_HS SG_ 328 StrngAsstRdcdIO 2500;
BA_REL_ "GenSigSuprvResp" BU_SG_REL_ BCM_HS SG_ 328 PwrStrIO 1;
BA_REL_ "GenSigTimeoutMsg" BU_SG_REL_ BCM_HS SG_ 328 PwrStrIO 328;
BA_REL_ "GenSigTimeoutTime" BU_SG_REL_ BCM_HS SG_ 328 PwrStrIO 2500;
BA_REL_ "GenSigSuprvResp" BU_SG_REL_ BCM_HS SG_ 560 AllNodesVNA 1;
BA_REL_ "GenSigTimeoutMsg" BU_SG_REL_ BCM_HS SG_ 560 AllNodesVNA 560;
BA_REL_ "GenSigTimeoutTime" BU_SG_REL_ BCM_HS SG_ 560 AllNodesVNA 250;
BA_REL_ "GenSigSuprvResp" BU_SG_REL_ BCM_HS SG_ 560 StpOnBrkToRelPBIndOn 1;
BA_REL_ "GenSigTimeoutMsg" BU_SG_REL_ BCM_HS SG_ 560 StpOnBrkToRelPBIndOn 560;
BA_REL_ "GenSigTimeoutTime" BU_SG_REL_ BCM_HS SG_ 560 StpOnBrkToRelPBIndOn 250;
BA_REL_ "GenSigSuprvResp" BU_SG_REL_ BCM_HS SG_ 560 EPBSysDspMsgReq 1;
BA_REL_ "GenSigTimeoutMsg" BU_SG_REL_ BCM_HS SG_ 560 EPBSysDspMsgReq 560;
BA_REL_ "GenSigTimeoutTime" BU_SG_REL_ BCM_HS SG_ 560 EPBSysDspMsgReq 250;
BA_REL_ "GenSigSuprvResp" BU_SG_REL_ BCM_HS SG_ 560 EPBSysAudWarnReq 1;
BA_REL_ "GenSigTimeoutMsg" BU_SG_REL_ BCM_HS SG_ 560 EPBSysAudWarnReq 560;
BA_REL_ "GenSigTimeoutTime" BU_SG_REL_ BCM_HS SG_ 560 EPBSysAudWarnReq 250;
BA_REL_ "GenSigSuprvResp" BU_SG_REL_ ACC_HS SG_ 560 ElecPrkBrkStat 1;
BA_REL_ "GenSigTimeoutMsg" BU_SG_REL_ ACC_HS SG_ 560 ElecPrkBrkStat 560;
BA_REL_ "GenSigTimeoutTime" BU_SG_REL_ ACC_HS SG_ 560 ElecPrkBrkStat 125;
BA_REL_ "GenSigSuprvResp" BU_SG_REL_ EOCM_F_HS SG_ 560 ElecPrkBrkStat 1;
BA_REL_ "GenSigTimeoutMsg" BU_SG_REL_ EOCM_F_HS SG_ 560 ElecPrkBrkStat 560;
BA_REL_ "GenSigTimeoutTime" BU_SG_REL_ EOCM_F_HS SG_ 560 ElecPrkBrkStat 160;
BA_REL_ "GenSigSuprvResp" BU_SG_REL_ EOCM_F_HS SG_ 560 ElecPrkBrkStat 1;
BA_REL_ "GenSigTimeoutMsg" BU_SG_REL_ EOCM_F_HS SG_ 560 ElecPrkBrkStat 560;
BA_REL_ "GenSigTimeoutTime" BU_SG_REL_ EOCM_F_HS SG_ 560 ElecPrkBrkStat 160;
BA_REL_ "GenSigSuprvResp" BU_SG_REL_ BCM_HS SG_ 560 ElecPrkBrkStat 1;
BA_REL_ "GenSigTimeoutMsg" BU_SG_REL_ BCM_HS SG_ 560 ElecPrkBrkStat 560;
BA_REL_ "GenSigTimeoutTime" BU_SG_REL_ BCM_HS SG_ 560 ElecPrkBrkStat 250;
BA_REL_ "GenSigSuprvResp" BU_SG_REL_ RDCM_HS SG_ 560 ElecPrkBrkStat 1;
BA_REL_ "GenSigTimeoutMsg" BU_SG_REL_ RDCM_HS SG_ 560 ElecPrkBrkStat 560;
BA_REL_ "GenSigTimeoutTime" BU_SG_REL_ RDCM_HS SG_ 560 ElecPrkBrkStat 250;
BA_REL_ "GenSigRxStartValue" BU_SG_REL_ ACC_HS SG_ 560 EPBCrsCanRq "0";
BA_REL_ "GenSigSuprvResp" BU_SG_REL_ ACC_HS SG_ 560 EPBCrsCanRq 1;
BA_REL_ "GenSigTimeoutMsg" BU_SG_REL_ ACC_HS SG_ 560 EPBCrsCanRq 560;
BA_REL_ "GenSigTimeoutTime" BU_SG_REL_ ACC_HS SG_ 560 EPBCrsCanRq 125;
BA_REL_ "GenSigSuprvResp" BU_SG_REL_ EOCM_F_HS SG_ 560 EPBCrsCanRq 1;
BA_REL_ "GenSigTimeoutMsg" BU_SG_REL_ EOCM_F_HS SG_ 560 EPBCrsCanRq 560;
BA_REL_ "GenSigTimeoutTime" BU_SG_REL_ EOCM_F_HS SG_ 560 EPBCrsCanRq 160;
BA_REL_ "GenSigSuprvResp" BU_SG_REL_ BCM_HS SG_ 560 EPBSysBrkLtsReq 1;
BA_REL_ "GenSigTimeoutMsg" BU_SG_REL_ BCM_HS SG_ 560 EPBSysBrkLtsReq 560;
BA_REL_ "GenSigTimeoutTime" BU_SG_REL_ BCM_HS SG_ 560 EPBSysBrkLtsReq 250;
BA_REL_ "GenSigSuprvResp" BU_SG_REL_ EBCM_OBD_HS SG_ 451 HillDscntCtrlSwStatPVal 1;
BA_REL_ "GenSigTimeoutMsg" BU_SG_REL_ EBCM_OBD_HS SG_ 451 HillDscntCtrlSwStatPVal 451;
BA_REL_ "GenSigTimeoutTime" BU_SG_REL_ EBCM_OBD_HS SG_ 451 HillDscntCtrlSwStatPVal 250;
BA_REL_ "GenSigSuprvResp" BU_SG_REL_ EBCM_HS SG_ 451 HillDscntCtrlSwStatPVal 1;
BA_REL_ "GenSigTimeoutMsg" BU_SG_REL_ EBCM_HS SG_ 451 HillDscntCtrlSwStatPVal 451;
BA_REL_ "GenSigTimeoutTime" BU_SG_REL_ EBCM_HS SG_ 451 HillDscntCtrlSwStatPVal 250;
BA_REL_ "GenSigSuprvResp" BU_SG_REL_ EBCM_OBD_HS SG_ 451 HillDscntCtrlSwStatARC 1;
BA_REL_ "GenSigTimeoutMsg" BU_SG_REL_ EBCM_OBD_HS SG_ 451 HillDscntCtrlSwStatARC 451;
BA_REL_ "GenSigTimeoutTime" BU_SG_REL_ EBCM_OBD_HS SG_ 451 HillDscntCtrlSwStatARC 250;
BA_REL_ "GenSigSuprvResp" BU_SG_REL_ EBCM_HS SG_ 451 HillDscntCtrlSwStatARC 1;
BA_REL_ "GenSigTimeoutMsg" BU_SG_REL_ EBCM_HS SG_ 451 HillDscntCtrlSwStatARC 451;
BA_REL_ "GenSigTimeoutTime" BU_SG_REL_ EBCM_HS SG_ 451 HillDscntCtrlSwStatARC 250;
BA_REL_ "GenSigSuprvResp" BU_SG_REL_ EBCM_OBD_HS SG_ 451 HillDscntCtrlSwStat 1;
BA_REL_ "GenSigTimeoutMsg" BU_SG_REL_ EBCM_OBD_HS SG_ 451 HillDscntCtrlSwStat 451;
BA_REL_ "GenSigTimeoutTime" BU_SG_REL_ EBCM_OBD_HS SG_ 451 HillDscntCtrlSwStat 250;
BA_REL_ "GenSigSuprvResp" BU_SG_REL_ EBCM_HS SG_ 451 HillDscntCtrlSwStat 1;
BA_REL_ "GenSigTimeoutMsg" BU_SG_REL_ EBCM_HS SG_ 451 HillDscntCtrlSwStat 451;
BA_REL_ "GenSigTimeoutTime" BU_SG_REL_ EBCM_HS SG_ 451 HillDscntCtrlSwStat 250;
BA_REL_ "GenSigSuprvResp" BU_SG_REL_ BCM_HS SG_ 451 GlwPlgCrnkDelAct 1;
BA_REL_ "GenSigTimeoutMsg" BU_SG_REL_ BCM_HS SG_ 451 GlwPlgCrnkDelAct 451;
BA_REL_ "GenSigTimeoutTime" BU_SG_REL_ BCM_HS SG_ 451 GlwPlgCrnkDelAct 250;
BA_REL_ "GenSigSuprvResp" BU_SG_REL_ RDCM_HS SG_ 451 AccPos 1;
BA_REL_ "GenSigTimeoutMsg" BU_SG_REL_ RDCM_HS SG_ 451 AccPos 451;
BA_REL_ "GenSigTimeoutTime" BU_SG_REL_ RDCM_HS SG_ 451 AccPos 250;
BA_REL_ "GenSigSuprvResp" BU_SG_REL_ ICCM_OBD_HS SG_ 451 AccPos 1;
BA_REL_ "GenSigTimeoutMsg" BU_SG_REL_ ICCM_OBD_HS SG_ 451 AccPos 451;
BA_REL_ "GenSigTimeoutTime" BU_SG_REL_ ICCM_OBD_HS SG_ 451 AccPos 250;
BA_REL_ "GenSigSuprvResp" BU_SG_REL_ ICCM_HS SG_ 451 AccPos 1;
BA_REL_ "GenSigTimeoutMsg" BU_SG_REL_ ICCM_HS SG_ 451 AccPos 451;
BA_REL_ "GenSigTimeoutTime" BU_SG_REL_ ICCM_HS SG_ 451 AccPos 250;
BA_REL_ "GenSigSuprvResp" BU_SG_REL_ EOCM_F_HS SG_ 451 AccPos 2;
BA_REL_ "GenSigTimeoutMsg" BU_SG_REL_ EOCM_F_HS SG_ 451 AccPos 451;
BA_REL_ "GenSigTimeoutTime" BU_SG_REL_ EOCM_F_HS SG_ 451 AccPos 120;
BA_REL_ "GenSigSuprvResp" BU_SG_REL_ BSM_HS SG_ 451 AccPos 1;
BA_REL_ "GenSigTimeoutMsg" BU_SG_REL_ BSM_HS SG_ 451 AccPos 451;
BA_REL_ "GenSigTimeoutTime" BU_SG_REL_ BSM_HS SG_ 451 AccPos 250;
BA_REL_ "GenSigSuprvResp" BU_SG_REL_ BSM_HS SG_ 451 AccPos 1;
BA_REL_ "GenSigTimeoutMsg" BU_SG_REL_ BSM_HS SG_ 451 AccPos 451;
BA_REL_ "GenSigTimeoutTime" BU_SG_REL_ BSM_HS SG_ 451 AccPos 250;
BA_REL_ "GenSigSuprvResp" BU_SG_REL_ VICM_HS SG_ 451 AccPos 1;
BA_REL_ "GenSigTimeoutMsg" BU_SG_REL_ VICM_HS SG_ 451 AccPos 451;
BA_REL_ "GenSigTimeoutTime" BU_SG_REL_ VICM_HS SG_ 451 AccPos 250;
BA_REL_ "GenSigSuprvResp" BU_SG_REL_ VICM_HS SG_ 451 AccPos 1;
BA_REL_ "GenSigTimeoutMsg" BU_SG_REL_ VICM_HS SG_ 451 AccPos 451;
BA_REL_ "GenSigTimeoutTime" BU_SG_REL_ VICM_HS SG_ 451 AccPos 250;
BA_REL_ "GenSigSuprvResp" BU_SG_REL_ TCCM_HS SG_ 451 AccPos 1;
BA_REL_ "GenSigTimeoutMsg" BU_SG_REL_ TCCM_HS SG_ 451 AccPos 451;
BA_REL_ "GenSigTimeoutTime" BU_SG_REL_ TCCM_HS SG_ 451 AccPos 250;
BA_REL_ "GenSigSuprvResp" BU_SG_REL_ BCM_HS SG_ 451 EngTrqDrRqdExtRng 1;
BA_REL_ "GenSigTimeoutMsg" BU_SG_REL_ BCM_HS SG_ 451 EngTrqDrRqdExtRng 451;
BA_REL_ "GenSigTimeoutTime" BU_SG_REL_ BCM_HS SG_ 451 EngTrqDrRqdExtRng 250;
BA_REL_ "GenSigSuprvResp" BU_SG_REL_ ACC_HS SG_ 451 EngTrqDrRqdExtRng 1;
BA_REL_ "GenSigTimeoutMsg" BU_SG_REL_ ACC_HS SG_ 451 EngTrqDrRqdExtRng 451;
BA_REL_ "GenSigTimeoutTime" BU_SG_REL_ ACC_HS SG_ 451 EngTrqDrRqdExtRng 250;
BA_REL_ "GenSigSuprvResp" BU_SG_REL_ AVM_HS SG_ 451 EngTrqActExtRng 1;
BA_REL_ "GenSigTimeoutMsg" BU_SG_REL_ AVM_HS SG_ 451 EngTrqActExtRng 451;
BA_REL_ "GenSigTimeoutTime" BU_SG_REL_ AVM_HS SG_ 451 EngTrqActExtRng 250;
BA_REL_ "GenSigSuprvResp" BU_SG_REL_ ICCM_OBD_HS SG_ 451 EngTrqActExtRng 1;
BA_REL_ "GenSigTimeoutMsg" BU_SG_REL_ ICCM_OBD_HS SG_ 451 EngTrqActExtRng 451;
BA_REL_ "GenSigTimeoutTime" BU_SG_REL_ ICCM_OBD_HS SG_ 451 EngTrqActExtRng 250;
BA_REL_ "GenSigSuprvResp" BU_SG_REL_ ICCM_HS SG_ 451 EngTrqActExtRng 1;
BA_REL_ "GenSigTimeoutMsg" BU_SG_REL_ ICCM_HS SG_ 451 EngTrqActExtRng 451;
BA_REL_ "GenSigTimeoutTime" BU_SG_REL_ ICCM_HS SG_ 451 EngTrqActExtRng 250;
BA_REL_ "GenSigSuprvResp" BU_SG_REL_ PTO_HS SG_ 451 EngTrqActExtRng 1;
BA_REL_ "GenSigTimeoutMsg" BU_SG_REL_ PTO_HS SG_ 451 EngTrqActExtRng 451;
BA_REL_ "GenSigTimeoutTime" BU_SG_REL_ PTO_HS SG_ 451 EngTrqActExtRng 250;
BA_REL_ "GenSigSuprvResp" BU_SG_REL_ AMP_HS SG_ 451 EngTrqActExtRng 1;
BA_REL_ "GenSigTimeoutMsg" BU_SG_REL_ AMP_HS SG_ 451 EngTrqActExtRng 451;
BA_REL_ "GenSigTimeoutTime" BU_SG_REL_ AMP_HS SG_ 451 EngTrqActExtRng 250;
BA_REL_ "GenSigSuprvResp" BU_SG_REL_ ACC_HS SG_ 451 EngTrqActExtRng 1;
BA_REL_ "GenSigTimeoutMsg" BU_SG_REL_ ACC_HS SG_ 451 EngTrqActExtRng 451;
BA_REL_ "GenSigTimeoutTime" BU_SG_REL_ ACC_HS SG_ 451 EngTrqActExtRng 250;
BA_REL_ "GenSigSuprvResp" BU_SG_REL_ EPB_HS SG_ 451 EngTrqActExtRng 1;
BA_REL_ "GenSigTimeoutMsg" BU_SG_REL_ EPB_HS SG_ 451 EngTrqActExtRng 451;
BA_REL_ "GenSigTimeoutTime" BU_SG_REL_ EPB_HS SG_ 451 EngTrqActExtRng 250;
BA_REL_ "GenSigVBitResp" BU_SG_REL_ BCM_HS SG_ 451 EngTrqActExtRng 1;
BA_REL_ "GenSigSuprvResp" BU_SG_REL_ BCM_HS SG_ 451 EngTrqActExtRng 1;
BA_REL_ "GenSigTimeoutMsg" BU_SG_REL_ BCM_HS SG_ 451 EngTrqActExtRng 451;
BA_REL_ "GenSigTimeoutTime" BU_SG_REL_ BCM_HS SG_ 451 EngTrqActExtRng 250;
BA_REL_ "GenSigRxStartValue" BU_SG_REL_ RDCM_HS SG_ 451 EngTrqActExtRng "$6A0 (0 converted)";
BA_REL_ "GenSigSuprvResp" BU_SG_REL_ RDCM_HS SG_ 451 EngTrqActExtRng 1;
BA_REL_ "GenSigTimeoutMsg" BU_SG_REL_ RDCM_HS SG_ 451 EngTrqActExtRng 451;
BA_REL_ "GenSigTimeoutTime" BU_SG_REL_ RDCM_HS SG_ 451 EngTrqActExtRng 250;
BA_REL_ "GenSigSuprvResp" BU_SG_REL_ EBCM_OBD_HS SG_ 451 EngTrqActExtRng 1;
BA_REL_ "GenSigTimeoutMsg" BU_SG_REL_ EBCM_OBD_HS SG_ 451 EngTrqActExtRng 451;
BA_REL_ "GenSigTimeoutTime" BU_SG_REL_ EBCM_OBD_HS SG_ 451 EngTrqActExtRng 63;
BA_REL_ "GenSigSuprvResp" BU_SG_REL_ EBCM_HS SG_ 451 EngTrqActExtRng 1;
BA_REL_ "GenSigTimeoutMsg" BU_SG_REL_ EBCM_HS SG_ 451 EngTrqActExtRng 451;
BA_REL_ "GenSigTimeoutTime" BU_SG_REL_ EBCM_HS SG_ 451 EngTrqActExtRng 63;
BA_REL_ "GenSigSuprvResp" BU_SG_REL_ SADS_HS SG_ 451 EngTrqActExtRng 1;
BA_REL_ "GenSigTimeoutMsg" BU_SG_REL_ SADS_HS SG_ 451 EngTrqActExtRng 451;
BA_REL_ "GenSigTimeoutTime" BU_SG_REL_ SADS_HS SG_ 451 EngTrqActExtRng 63;
BA_REL_ "GenSigSuprvResp" BU_SG_REL_ CGM_HS SG_ 801 WhlBdySnsHmPosLrnd 1;
BA_REL_ "GenSigTimeoutMsg" BU_SG_REL_ CGM_HS SG_ 801 WhlBdySnsHmPosLrnd 801;
BA_REL_ "GenSigTimeoutTime" BU_SG_REL_ CGM_HS SG_ 801 WhlBdySnsHmPosLrnd 250;
BA_REL_ "GenSigSuprvResp" BU_SG_REL_ CGM_HS SG_ 801 WBRP_ARC 1;
BA_REL_ "GenSigTimeoutMsg" BU_SG_REL_ CGM_HS SG_ 801 WBRP_ARC 801;
BA_REL_ "GenSigTimeoutTime" BU_SG_REL_ CGM_HS SG_ 801 WBRP_ARC 250;
BA_REL_ "GenSigSuprvResp" BU_SG_REL_ AHL_AFL_HS SG_ 801 WBRP_ARC 1;
BA_REL_ "GenSigTimeoutMsg" BU_SG_REL_ AHL_AFL_HS SG_ 801 WBRP_ARC 801;
BA_REL_ "GenSigTimeoutTime" BU_SG_REL_ AHL_AFL_HS SG_ 801 WBRP_ARC 250;
BA_REL_ "GenSigSuprvResp" BU_SG_REL_ CGM_HS SG_ 801 WBRP_Tmestmp 1;
BA_REL_ "GenSigTimeoutMsg" BU_SG_REL_ CGM_HS SG_ 801 WBRP_Tmestmp 801;
BA_REL_ "GenSigTimeoutTime" BU_SG_REL_ CGM_HS SG_ 801 WBRP_Tmestmp 250;
BA_REL_ "GenSigSuprvResp" BU_SG_REL_ AHL_AFL_HS SG_ 801 WBRP_Tmestmp 1;
BA_REL_ "GenSigTimeoutMsg" BU_SG_REL_ AHL_AFL_HS SG_ 801 WBRP_Tmestmp 801;
BA_REL_ "GenSigTimeoutTime" BU_SG_REL_ AHL_AFL_HS SG_ 801 WBRP_Tmestmp 250;
BA_REL_ "GenSigSuprvResp" BU_SG_REL_ CGM_HS SG_ 801 WBRP_RtFrtV 1;
BA_REL_ "GenSigTimeoutMsg" BU_SG_REL_ CGM_HS SG_ 801 WBRP_RtFrtV 801;
BA_REL_ "GenSigTimeoutTime" BU_SG_REL_ CGM_HS SG_ 801 WBRP_RtFrtV 250;
BA_REL_ "GenSigSuprvResp" BU_SG_REL_ AHL_AFL_HS SG_ 801 WBRP_RtFrtV 1;
BA_REL_ "GenSigTimeoutMsg" BU_SG_REL_ AHL_AFL_HS SG_ 801 WBRP_RtFrtV 801;
BA_REL_ "GenSigTimeoutTime" BU_SG_REL_ AHL_AFL_HS SG_ 801 WBRP_RtFrtV 250;
BA_REL_ "GenSigSuprvResp" BU_SG_REL_ CGM_HS SG_ 801 WBRP_RtFrt 1;
BA_REL_ "GenSigTimeoutMsg" BU_SG_REL_ CGM_HS SG_ 801 WBRP_RtFrt 801;
BA_REL_ "GenSigTimeoutTime" BU_SG_REL_ CGM_HS SG_ 801 WBRP_RtFrt 250;
BA_REL_ "GenSigSuprvResp" BU_SG_REL_ AHL_AFL_HS SG_ 801 WBRP_RtFrt 1;
BA_REL_ "GenSigTimeoutMsg" BU_SG_REL_ AHL_AFL_HS SG_ 801 WBRP_RtFrt 801;
BA_REL_ "GenSigTimeoutTime" BU_SG_REL_ AHL_AFL_HS SG_ 801 WBRP_RtFrt 250;
BA_REL_ "GenSigSuprvResp" BU_SG_REL_ CGM_HS SG_ 801 WBRP_RtRrV 1;
BA_REL_ "GenSigTimeoutMsg" BU_SG_REL_ CGM_HS SG_ 801 WBRP_RtRrV 801;
BA_REL_ "GenSigTimeoutTime" BU_SG_REL_ CGM_HS SG_ 801 WBRP_RtRrV 250;
BA_REL_ "GenSigSuprvResp" BU_SG_REL_ AHL_AFL_HS SG_ 801 WBRP_RtRrV 1;
BA_REL_ "GenSigTimeoutMsg" BU_SG_REL_ AHL_AFL_HS SG_ 801 WBRP_RtRrV 801;
BA_REL_ "GenSigTimeoutTime" BU_SG_REL_ AHL_AFL_HS SG_ 801 WBRP_RtRrV 250;
BA_REL_ "GenSigSuprvResp" BU_SG_REL_ CGM_HS SG_ 801 WBRP_RtRr 1;
BA_REL_ "GenSigTimeoutMsg" BU_SG_REL_ CGM_HS SG_ 801 WBRP_RtRr 801;
BA_REL_ "GenSigTimeoutTime" BU_SG_REL_ CGM_HS SG_ 801 WBRP_RtRr 250;
BA_REL_ "GenSigSuprvResp" BU_SG_REL_ AHL_AFL_HS SG_ 801 WBRP_RtRr 1;
BA_REL_ "GenSigTimeoutMsg" BU_SG_REL_ AHL_AFL_HS SG_ 801 WBRP_RtRr 801;
BA_REL_ "GenSigTimeoutTime" BU_SG_REL_ AHL_AFL_HS SG_ 801 WBRP_RtRr 250;
BA_REL_ "GenSigSuprvResp" BU_SG_REL_ CGM_HS SG_ 801 WBRP_LftRrV 1;
BA_REL_ "GenSigTimeoutMsg" BU_SG_REL_ CGM_HS SG_ 801 WBRP_LftRrV 801;
BA_REL_ "GenSigTimeoutTime" BU_SG_REL_ CGM_HS SG_ 801 WBRP_LftRrV 250;
BA_REL_ "GenSigSuprvResp" BU_SG_REL_ AHL_AFL_HS SG_ 801 WBRP_LftRrV 1;
BA_REL_ "GenSigTimeoutMsg" BU_SG_REL_ AHL_AFL_HS SG_ 801 WBRP_LftRrV 801;
BA_REL_ "GenSigTimeoutTime" BU_SG_REL_ AHL_AFL_HS SG_ 801 WBRP_LftRrV 250;
BA_REL_ "GenSigSuprvResp" BU_SG_REL_ CGM_HS SG_ 801 WBRP_LftRr 1;
BA_REL_ "GenSigTimeoutMsg" BU_SG_REL_ CGM_HS SG_ 801 WBRP_LftRr 801;
BA_REL_ "GenSigTimeoutTime" BU_SG_REL_ CGM_HS SG_ 801 WBRP_LftRr 250;
BA_REL_ "GenSigSuprvResp" BU_SG_REL_ AHL_AFL_HS SG_ 801 WBRP_LftRr 1;
BA_REL_ "GenSigTimeoutMsg" BU_SG_REL_ AHL_AFL_HS SG_ 801 WBRP_LftRr 801;
BA_REL_ "GenSigTimeoutTime" BU_SG_REL_ AHL_AFL_HS SG_ 801 WBRP_LftRr 250;
BA_REL_ "GenSigSuprvResp" BU_SG_REL_ CGM_HS SG_ 801 WBRP_LftFrtV 1;
BA_REL_ "GenSigTimeoutMsg" BU_SG_REL_ CGM_HS SG_ 801 WBRP_LftFrtV 801;
BA_REL_ "GenSigTimeoutTime" BU_SG_REL_ CGM_HS SG_ 801 WBRP_LftFrtV 250;
BA_REL_ "GenSigSuprvResp" BU_SG_REL_ AHL_AFL_HS SG_ 801 WBRP_LftFrtV 1;
BA_REL_ "GenSigTimeoutMsg" BU_SG_REL_ AHL_AFL_HS SG_ 801 WBRP_LftFrtV 801;
BA_REL_ "GenSigTimeoutTime" BU_SG_REL_ AHL_AFL_HS SG_ 801 WBRP_LftFrtV 250;
BA_REL_ "GenSigSuprvResp" BU_SG_REL_ CGM_HS SG_ 801 WBRP_LftFrt 1;
BA_REL_ "GenSigTimeoutMsg" BU_SG_REL_ CGM_HS SG_ 801 WBRP_LftFrt 801;
BA_REL_ "GenSigTimeoutTime" BU_SG_REL_ CGM_HS SG_ 801 WBRP_LftFrt 250;
BA_REL_ "GenSigSuprvResp" BU_SG_REL_ AHL_AFL_HS SG_ 801 WBRP_LftFrt 1;
BA_REL_ "GenSigTimeoutMsg" BU_SG_REL_ AHL_AFL_HS SG_ 801 WBRP_LftFrt 801;
BA_REL_ "GenSigTimeoutTime" BU_SG_REL_ AHL_AFL_HS SG_ 801 WBRP_LftFrt 250;
BA_REL_ "GenSigSuprvResp" BU_SG_REL_ EPS_HS SG_ 320 Ky_IdDevPrgmAuthReq 1;
BA_REL_ "GenSigTimeoutMsg" BU_SG_REL_ EPS_HS SG_ 320 Ky_IdDevPrgmAuthReq 320;
BA_REL_ "GenSigTimeoutTime" BU_SG_REL_ EPS_HS SG_ 320 Ky_IdDevPrgmAuthReq 2500;
BA_REL_ "GenSigSuprvResp" BU_SG_REL_ EPS_HS SG_ 320 ClmnLckStat 1;
BA_REL_ "GenSigTimeoutMsg" BU_SG_REL_ EPS_HS SG_ 320 ClmnLckStat 320;
BA_REL_ "GenSigTimeoutTime" BU_SG_REL_ EPS_HS SG_ 320 ClmnLckStat 2500;
BA_REL_ "GenSigSuprvResp" BU_SG_REL_ AHL_AFL_HS SG_ 320 AutoBmSlctAllwd 1;
BA_REL_ "GenSigTimeoutMsg" BU_SG_REL_ AHL_AFL_HS SG_ 320 AutoBmSlctAllwd 320;
BA_REL_ "GenSigTimeoutTime" BU_SG_REL_ AHL_AFL_HS SG_ 320 AutoBmSlctAllwd 2500;
BA_REL_ "GenSigSuprvResp" BU_SG_REL_ AHL_AFL_HS SG_ 320 BrkLtsAtv 1;
BA_REL_ "GenSigTimeoutMsg" BU_SG_REL_ AHL_AFL_HS SG_ 320 BrkLtsAtv 320;
BA_REL_ "GenSigTimeoutTime" BU_SG_REL_ AHL_AFL_HS SG_ 320 BrkLtsAtv 2500;
BA_REL_ "GenSigSuprvResp" BU_SG_REL_ EOCM_F_HS SG_ 320 BrkLtsAtv 1;
BA_REL_ "GenSigTimeoutMsg" BU_SG_REL_ EOCM_F_HS SG_ 320 BrkLtsAtv 320;
BA_REL_ "GenSigTimeoutTime" BU_SG_REL_ EOCM_F_HS SG_ 320 BrkLtsAtv 2500;
BA_REL_ "GenSigSuprvResp" BU_SG_REL_ EOCM_F_HS SG_ 320 BrkLtsAtv 1;
BA_REL_ "GenSigTimeoutTime" BU_SG_REL_ EOCM_F_HS SG_ 320 BrkLtsAtv 2500;
BA_REL_ "GenSigSuprvResp" BU_SG_REL_ EBCM_OBD_HS SG_ 320 TrnSwAct 1;
BA_REL_ "GenSigTimeoutMsg" BU_SG_REL_ EBCM_OBD_HS SG_ 320 TrnSwAct 320;
BA_REL_ "GenSigTimeoutTime" BU_SG_REL_ EBCM_OBD_HS SG_ 320 TrnSwAct 2500;
BA_REL_ "GenSigSuprvResp" BU_SG_REL_ EBCM_HS SG_ 320 TrnSwAct 1;
BA_REL_ "GenSigTimeoutMsg" BU_SG_REL_ EBCM_HS SG_ 320 TrnSwAct 320;
BA_REL_ "GenSigTimeoutTime" BU_SG_REL_ EBCM_HS SG_ 320 TrnSwAct 2500;
BA_REL_ "GenSigSuprvResp" BU_SG_REL_ ECM_HS SG_ 320 TrnSwAct 1;
BA_REL_ "GenSigTimeoutMsg" BU_SG_REL_ ECM_HS SG_ 320 TrnSwAct 320;
BA_REL_ "GenSigTimeoutTime" BU_SG_REL_ ECM_HS SG_ 320 TrnSwAct 2500;
BA_REL_ "GenSigSuprvResp" BU_SG_REL_ EOCM_F_HS SG_ 320 TrnSwAct 1;
BA_REL_ "GenSigTimeoutTime" BU_SG_REL_ EOCM_F_HS SG_ 320 TrnSwAct 2500;
BA_REL_ "GenSigSuprvResp" BU_SG_REL_ EOCM_F_HS SG_ 320 OtsdAmbtLtLvlStat 1;
BA_REL_ "GenSigTimeoutMsg" BU_SG_REL_ EOCM_F_HS SG_ 320 OtsdAmbtLtLvlStat 320;
BA_REL_ "GenSigTimeoutTime" BU_SG_REL_ EOCM_F_HS SG_ 320 OtsdAmbtLtLvlStat 2500;
BA_REL_ "GenSigSuprvResp" BU_SG_REL_ EOCM_F_HS SG_ 320 LowBmAct 2;
BA_REL_ "GenSigTimeoutTime" BU_SG_REL_ EOCM_F_HS SG_ 320 LowBmAct 2500;
BA_REL_ "GenSigSuprvResp" BU_SG_REL_ EOCM_F_HS SG_ 320 HighBmAct 2;
BA_REL_ "GenSigTimeoutTime" BU_SG_REL_ EOCM_F_HS SG_ 320 HighBmAct 2500;
BA_REL_ "GenSigSuprvResp" BU_SG_REL_ AHL_AFL_HS SG_ 320 AdvFrntLghtSysEnbld 1;
BA_REL_ "GenSigTimeoutMsg" BU_SG_REL_ AHL_AFL_HS SG_ 320 AdvFrntLghtSysEnbld 320;
BA_REL_ "GenSigTimeoutTime" BU_SG_REL_ AHL_AFL_HS SG_ 320 AdvFrntLghtSysEnbld 2500;
BA_REL_ "GenSigSuprvResp" BU_SG_REL_ ECM_HS SG_ 957 RdctHtrCStat 1;
BA_REL_ "GenSigTimeoutMsg" BU_SG_REL_ ECM_HS SG_ 957 RdctHtrCStat 957;
BA_REL_ "GenSigTimeoutTime" BU_SG_REL_ ECM_HS SG_ 957 RdctHtrCStat 250;
BA_REL_ "GenSigSuprvResp" BU_SG_REL_ ECM_HS SG_ 957 RdctHtrBStat 1;
BA_REL_ "GenSigTimeoutMsg" BU_SG_REL_ ECM_HS SG_ 957 RdctHtrBStat 957;
BA_REL_ "GenSigTimeoutTime" BU_SG_REL_ ECM_HS SG_ 957 RdctHtrBStat 250;
BA_REL_ "GenSigSuprvResp" BU_SG_REL_ ECM_HS SG_ 957 RdctHtrAStat 1;
BA_REL_ "GenSigTimeoutMsg" BU_SG_REL_ ECM_HS SG_ 957 RdctHtrAStat 957;
BA_REL_ "GenSigTimeoutTime" BU_SG_REL_ ECM_HS SG_ 957 RdctHtrAStat 250;
BA_REL_ "GenSigSuprvResp" BU_SG_REL_ ECM_HS SG_ 957 DslGlwPlgMdOvTmOD 1;
BA_REL_ "GenSigTimeoutMsg" BU_SG_REL_ ECM_HS SG_ 957 DslGlwPlgMdOvTmOD 957;
BA_REL_ "GenSigTimeoutTime" BU_SG_REL_ ECM_HS SG_ 957 DslGlwPlgMdOvTmOD 250;
VAL_ 1280 TireRRLowTracIO 1 "true" 0 "false" ;
VAL_ 1280 TireRFLowTracIO 1 "true" 0 "false" ;
VAL_ 1280 TireLRLowTracIO 1 "true" 0 "false" ;
VAL_ 1280 TireLFLowTracIO 1 "true" 0 "false" ;
VAL_ 190 TrnsAuxPmpAct 1 "true" 0 "false" ;
VAL_ 190 PSBPI_PTSnBrkPdlPsV 1 "Invalid" 0 "Valid" ;
VAL_ 322 AFLGPSCstStReq 0 "No Action" 1 "Corner And Curve Lighting Only" 2 "Intelligent Light Distribution" 3 "GPS Assistance" 4 "Reserved1" 5 "Reserved2" 6 "Reserved3" 7 "Off" ;
VAL_ 322 AFLCstStReq 0 "No Action" 1 "Corner And Curve Lighting Only" 2 "Intelligent Light Distribution" 3 "Reserved1" 4 "Reserved2" 5 "Reserved3" 6 "Reserved4" 7 "Off" ;
VAL_ 322 LtRtHnTrCstStReq 0 "No Action" 1 "Left Hand Drive" 2 "Right Hand Drive" ;
VAL_ 322 AdpHgBmAsSnCsStRq 0 "No Action" 1 "Off" 2 "Normal Sensitivity" 3 "Reduced Sensitivity" 4 "Reserved1" 5 "Reserved2" 6 "Reserved3" 7 "Reserved4" ;
VAL_ 322 AdpHgBmAstCstStRq 0 "No Action" 1 "Off" 2 "On" 3 "Reserved1" 4 "Reserved2" 5 "Reserved3" 6 "Reserved4" 7 "Reserved5" ;
VAL_ 322 LtRtHnTrGPSCstStRq 0 "No Action" 1 "Left Hand Traffic" 2 "Right Hand Traffic" 3 "Automatic" 4 "Reserved1" 5 "Reserved2" 6 "Reserved3" 7 "Reserved4" ;
VAL_ 322 AutHgBmAsSnCsStRq 0 "No Action" 1 "Off" 2 "On Normal Sensitivity" 3 "On Reduced Sensitivity" 4 "Reserved1" 5 "Reserved2" 6 "Reserved3" 7 "Reserved4" ;
VAL_ 322 AutHgBmAstCstStRq 0 "No Action" 1 "Off" 2 "On" 3 "Reserved1" 4 "Reserved2" 5 "Reserved3" 6 "Reserved4" 7 "Reserved5" ;
VAL_ 534 SrvSuspSysIO 1 "true" 0 "false" ;
VAL_ 309 StBltTgtCSRq 0 "No Action" 1 "Low" 2 "Normal" 3 "Performance" 4 "Locked" ;
VAL_ 309 ColPrSysCustReq 0 "No Action" 1 "Off" 2 "Alert" 3 "Alert and Brake" ;
VAL_ 309 SecV 1 "Invalid" 0 "Valid" ;
VAL_ 309 CldrMth_154 12 "December" 11 "November" 10 "October" 9 "September" 8 "August" 7 "July" 6 "June" 5 "May" 4 "April" 3 "March" 2 "February" 1 "January" 0 "Unknown" ;
VAL_ 309 CldrMth 12 "December" 11 "November" 10 "October" 9 "September" 8 "August" 7 "July" 6 "June" 5 "May" 4 "April" 3 "March" 2 "February" 1 "January" 0 "Unknown" ;
VAL_ 309 AutoHiBmVDA 1 "VirtualDeviceAvailable" 0 "VirtualDeviceUnavailable" ;
VAL_ 309 CtLghtDet 1 "true" 0 "false" ;
VAL_ 309 RrClosVDA 1 "VirtualDeviceAvailable" 0 "VirtualDeviceUnavailable" ;
VAL_ 309 TCSysDisSwAtv 1 "true" 0 "false" ;
VAL_ 309 VehMovState 4 "Invalid" 3 "Reverse" 2 "Forward" 1 "Neutral" 0 "Parked" ;
VAL_ 309 TCSysDisSwAtvV 1 "Invalid" 0 "Valid" ;
VAL_ 309 HillDesCtrlMdSwActV 1 "Invalid" 0 "Valid" ;
VAL_ 309 WSWshSwAtv 1 "true" 0 "false" ;
VAL_ 309 HillDesCtrlMdSwAct 1 "true" 0 "false" ;
VAL_ 309 RrClosAjarSwAct 1 "true" 0 "false" ;
VAL_ 309 WSWprAct 1 "true" 0 "false" ;
VAL_ 389 VSELongAccLoResV 1 "Invalid" 0 "Valid" ;
VAL_ 389 StrAngSnsPolRat 0 "Not Passed" 1 "Passed" ;
VAL_ 389 LatAccSnsPolRat 0 "Not Passed" 1 "Passed" ;
VAL_ 1922 DTCI_WrnIndRqdSt_782 1 "true" 0 "false" ;
VAL_ 1922 DTCIUnused7_782 1 "true" 0 "false" ;
VAL_ 1922 DTCIUnused6_782 1 "true" 0 "false" ;
VAL_ 1922 DTCIUnused5_782 1 "true" 0 "false" ;
VAL_ 1922 DTCIUnused4_782 1 "true" 0 "false" ;
VAL_ 1922 DTCIUnused3_782 1 "true" 0 "false" ;
VAL_ 1922 DTCIUnused2_782 1 "true" 0 "false" ;
VAL_ 1922 DTCIUnused1_782 1 "true" 0 "false" ;
VAL_ 1922 DTCI_TstNPsdPwrUpSt_782 1 "true" 0 "false" ;
VAL_ 1922 DTCI_TstNPsdCdClrdSt_782 1 "true" 0 "false" ;
VAL_ 1922 DTCI_TstFldPwrUpSt_782 1 "true" 0 "false" ;
VAL_ 1922 DTCI_TstFldCdClrdStat_782 1 "true" 0 "false" ;
VAL_ 1922 DTCI_HistStat_782 1 "true" 0 "false" ;
VAL_ 1922 DTCI_DTCTriggered_782 1 "true" 0 "false" ;
VAL_ 1922 DTCI_DTCFaultType_782 3 "Type C" 2 "Type B" 1 "Type A" 0 "Not Supported" ;
VAL_ 1922 DTCI_CurrentStatus_782 1 "true" 0 "false" ;
VAL_ 1922 DTCI_CodeSupported_782 1 "true" 0 "false" ;
VAL_ 352 ShfFrmPrkAlwd 1 "true" 0 "false" ;
VAL_ 352 AVHSwtchStats 1 "Active" 0 "Not Active" ;
VAL_ 352 TeenDrvAct 1 "true" 0 "false" ;
VAL_ 352 LrnEnvIdSt 1 "Info_valid" 0 "No_info" ;
VAL_ 352 ImoIdSt 1 "Info valid" 0 "No info" ;
VAL_ 562 SndPerfMdCsStAvl 1 "true" 0 "false" ;
VAL_ 562 SndPerfMdCsCrStVal 0 "No Action" 1 "Performance Mode 1" 2 "Performance Mode 2" 3 "Performance Mode 3" 4 "Performance Mode 4" 5 "Performance Mode 5" 6 "Performance Mode 6" 7 "Auto" ;
VAL_ 562 DispPerfMdCsStAvl 1 "true" 0 "false" ;
VAL_ 562 DispPerfMdCsCrStVal 0 "No Action" 1 "Performance Mode 1" 2 "Performance Mode 2" 3 "Performance Mode 3" 4 "Performance Mode 4" 5 "Performance Mode 5" 6 "Performance Mode 6" 7 "Auto" ;
VAL_ 562 DrvlneMntsPerfMdRq 0 "No Action" 1 "Performance Mode 1" 2 "Performance Mode 2" 3 "Performance Mode 3" 4 "Performance Mode 4" 5 "Performance Mode 5" 6 "Performance Mode 6" 7 "Performance Mode 7" ;
VAL_ 562 RideCntrlPerfMdRq 7 "Performance Mode 7" 6 "Performance Mode 6" 5 "Performance Mode 5" 4 "Performance Mode 4" 3 "Performance Mode 3" 2 "Performance Mode 2" 1 "Performance Mode 1" 0 "No Action" ;
VAL_ 562 StgSysPerfMdRq 7 "Performance Mode 7" 6 "Performance Mode 6" 5 "Performance Mode 5" 4 "Performance Mode 4" 3 "Performance Mode 3" 2 "Performance Mode 2" 1 "Performance Mode 1" 0 "No Action" ;
VAL_ 562 DiffPerfMdRq 7 "Performance Mode 7" 6 "Performance Mode 6" 5 "Performance Mode 5" 4 "Performance Mode 4" 3 "Performance Mode 3" 2 "Performance Mode 2" 1 "Performance Mode 1" 0 "No Action" ;
VAL_ 562 SndEnhcmtPerfMdRq 7 "Performance Mode 7" 6 "Performance Mode 6" 5 "Performance Mode 5" 4 "Performance Mode 4" 3 "Performance Mode 3" 2 "Performance Mode 2" 1 "Performance Mode 1" 0 "No Action" ;
VAL_ 562 DsplyPerfMdRq 7 "Performance Mode 7" 6 "Performance Mode 6" 5 "Performance Mode 5" 4 "Performance Mode 4" 3 "Performance Mode 3" 2 "Performance Mode 2" 1 "Performance Mode 1" 0 "No Action" ;
VAL_ 562 ExhstPerfMdRq 7 "Performance Mode 7" 6 "Performance Mode 6" 5 "Performance Mode 5" 4 "Performance Mode 4" 3 "Performance Mode 3" 2 "Performance Mode 2" 1 "Performance Mode 1" 0 "No Action" ;
VAL_ 562 HillDscntCntlSysStat 4 "Temporarily Inhibited" 3 "Failed" 2 "Active" 1 "Enabled" 0 "Normal" ;
VAL_ 562 SusCustStngAvlbl 1 "true" 0 "false" ;
VAL_ 562 SusCustCurrStngVal 7 "Auto" 6 "Performance Mode 6" 5 "Performance Mode 5" 4 "Performance Mode 4" 3 "Performance Mode 3" 0 "No Action" 1 "Performance Mode 1" 2 "Performance Mode 2" ;
VAL_ 562 StrCustStngAvlbl 1 "true" 0 "false" ;
VAL_ 562 StrCustCurrStngVal 7 "Auto" 6 "Performance Mode 6" 5 "Performance Mode 5" 4 "Performance Mode 4" 3 "Performance Mode 3" 0 "No Action" 1 "Performance Mode 1" 2 "Performance Mode 2" ;
VAL_ 562 DrvlnCustStngAvlbl 1 "true" 0 "false" ;
VAL_ 562 AWDPerfMdRq 7 "Performance Mode 7" 6 "Performance Mode 6" 5 "Performance Mode 5" 4 "Performance Mode 4" 3 "Performance Mode 3" 2 "Performance Mode 2" 1 "Performance Mode 1" 0 "No Action" ;
VAL_ 562 DrvlnCustCurrStngVal 7 "Auto" 6 "Performance Mode 6" 5 "Performance Mode 5" 4 "Performance Mode 4" 3 "Performance Mode 3" 0 "No Action" 1 "Performance Mode 1" 2 "Performance Mode 2" ;
VAL_ 893 AFLMnu3CstStAvl 1 "true" 0 "false" ;
VAL_ 893 AFLMnu2CstStAvl 1 "true" 0 "false" ;
VAL_ 893 AFLGPSMnu2CstStAvl 1 "true" 0 "false" ;
VAL_ 893 AFLGPSCstStAvl 1 "true" 0 "false" ;
VAL_ 893 AFLGPSCstCrStVal 0 "No Value" 1 "Corner And Curve Lighting Only" 2 "Intelligent Light Distribution" 3 "GPS Assistance" 4 "Reserved1" 5 "Reserved2" 6 "Reserved3" 7 "Off" ;
VAL_ 893 AFLCstStAvl 1 "true" 0 "false" ;
VAL_ 893 AFLCstCrStVal 0 "No Value" 1 "Corner And Curve Lighting Only" 2 "Intelligent Light Distribution" 3 "Reserved1" 4 "Reserved2" 5 "Reserved3" 6 "Reserved4" 7 "Off" ;
VAL_ 892 AdpHgBmAsSnCsCrStVal 0 "No Value" 1 "Off" 2 "On Normal Sensitivity" 3 "On Reduced Sensitivity" 4 "Reserved1" 5 "Reserved2" 6 "Reserved3" 7 "Reserved4" ;
VAL_ 892 AdpHgBmAsSnCsStAvl 1 "true" 0 "false" ;
VAL_ 892 AdpHgBmAsCsCrStVal 0 "No Value" 1 "Off" 2 "On" 3 "Reserved1" 4 "Reserved2" 5 "Reserved3" 6 "Reserved4" 7 "Reserved5" ;
VAL_ 892 AdpHgBmAsCsStAvl 1 "true" 0 "false" ;
VAL_ 892 AutHgBmAsCsCrStVal 0 "No Value" 1 "Off" 2 "On" 3 "Reserved1" 4 "Reserved2" 5 "Reserved3" 6 "Reserved4" 7 "Reserved5" ;
VAL_ 892 AutHgBmAsSnCsStAvl 1 "true" 0 "false" ;
VAL_ 892 AutHgBmAsSnCsCrStVa 0 "No Value" 1 "Off" 2 "On Normal Sensitivity" 3 "On Reduced Sensitivity" 4 "Reserved1" 5 "Reserved2" 6 "Reserved3" 7 "Reserved4" ;
VAL_ 892 AutHgBmAsCsStAvl 1 "true" 0 "false" ;
VAL_ 386 AHAct 1 "true" 0 "false" ;
VAL_ 386 AHEnbld 1 "true" 0 "false" ;
VAL_ 386 ShfToPrkBfExtngIO 1 "true" 0 "false" ;
VAL_ 386 AHServcIO 1 "true" 0 "false" ;
VAL_ 386 AHAppBrkPedlIO 1 "true" 0 "false" ;
VAL_ 386 AHDisbldStbltIO 1 "true" 0 "false" ;
VAL_ 386 AHDisbldDrOpnIO 1 "true" 0 "false" ;
VAL_ 386 PMVSS_Disps 7 "Visualization Type 7" 6 "Visualization Type 6" 5 "Visualization Type 5" 4 "Visualization Type 4" 3 "Visualization Type 3" 2 "Visualization Type 2" 1 "Visualization Type 1" 0 "No Action" ;
VAL_ 386 PMVSS_Exhst 7 "Visualization Type 7" 6 "Visualization Type 6" 5 "Visualization Type 5" 4 "Visualization Type 4" 3 "Visualization Type 3" 2 "Visualization Type 2" 1 "Visualization Type 1" 0 "No Action" ;
VAL_ 386 PMVSS_PsngrSeat 7 "Visualization Type 7" 6 "Visualization Type 6" 5 "Visualization Type 5" 4 "Visualization Type 4" 3 "Visualization Type 3" 2 "Visualization Type 2" 1 "Visualization Type 1" 0 "No Action" ;
VAL_ 386 PMVSS_DrvrSeat 7 "Visualization Type 7" 6 "Visualization Type 6" 5 "Visualization Type 5" 4 "Visualization Type 4" 3 "Visualization Type 3" 2 "Visualization Type 2" 1 "Visualization Type 1" 0 "No Action" ;
VAL_ 386 PMVSS_AdptCrsCnt 7 "Visualization Type 7" 6 "Visualization Type 6" 5 "Visualization Type 5" 4 "Visualization Type 4" 3 "Visualization Type 3" 2 "Visualization Type 2" 1 "Visualization Type 1" 0 "No Action" ;
VAL_ 386 PMVSS_Drvln 7 "Visualization Type 7" 6 "Visualization Type 6" 5 "Visualization Type 5" 4 "Visualization Type 4" 3 "Visualization Type 3" 2 "Visualization Type 2" 1 "Visualization Type 1" 0 "No Action" ;
VAL_ 386 PMVSS_Susp 7 "Visualization Type 7" 6 "Visualization Type 6" 5 "Visualization Type 5" 4 "Visualization Type 4" 3 "Visualization Type 3" 2 "Visualization Type 2" 1 "Visualization Type 1" 0 "No Action" ;
VAL_ 386 PMVSS_Strng 7 "Visualization Type 7" 6 "Visualization Type 6" 5 "Visualization Type 5" 4 "Visualization Type 4" 3 "Visualization Type 3" 2 "Visualization Type 2" 1 "Visualization Type 1" 0 "No Action" ;
VAL_ 386 PMVSS_Trans 7 "Visualization Type 7" 6 "Visualization Type 6" 5 "Visualization Type 5" 4 "Visualization Type 4" 3 "Visualization Type 3" 2 "Visualization Type 2" 1 "Visualization Type 1" 0 "No Action" ;
VAL_ 386 PMVSS_Eng 7 "Visualization Type 7" 6 "Visualization Type 6" 5 "Visualization Type 5" 4 "Visualization Type 4" 3 "Visualization Type 3" 2 "Visualization Type 2" 1 "Visualization Type 1" 0 "No Action" ;
VAL_ 386 PMVSS_Snd 7 "Visualization Type 7" 6 "Visualization Type 6" 5 "Visualization Type 5" 4 "Visualization Type 4" 3 "Visualization Type 3" 2 "Visualization Type 2" 1 "Visualization Type 1" 0 "No Action" ;
VAL_ 386 AdptCruzCtrlStg 7 "Performance Mode 7" 6 "Performance Mode 6" 5 "Performance Mode 5" 4 "Performance Mode 4" 3 "Performance Mode 3" 2 "Performance Mode 2" 1 "Performance Mode 1" 0 "No Action" ;
VAL_ 386 EnvIdRspSt4 3 "Environment_id_request" 2 "Incorrect_immo_id" 1 "Info_valid" 0 "No_info" ;
VAL_ 532 RedntVSEAct 1 "true" 0 "false" ;
VAL_ 532 HilRlbkCtrlActIO 1 "true" 0 "false" ;
VAL_ 532 VehHldDrvrDsblActvFlg 1 "true" 0 "false" ;
VAL_ 532 AutoBrkngAvlbl 1 "true" 0 "false" ;
VAL_ 532 ABSAutnmsBrkReq 1 "true" 0 "false" ;
VAL_ 532 HlStrAssActIO 1 "true" 0 "false" ;
VAL_ 532 ABSActvProt 1 "true" 0 "false" ;
VAL_ 532 BrkSysAutBrkFld 1 "true" 0 "false" ;
VAL_ 532 IntBrkAssPreFilReq 1 "true" 0 "false" ;
VAL_ 532 BrkSysMalFuncIndOn 1 "true" 0 "false" ;
VAL_ 532 BPDAPS_BkPDrvApPV 1 "Invalid" 0 "Valid" ;
VAL_ 532 BrkFldLvlLwV 1 "Invalid" 0 "Valid" ;
VAL_ 532 AutoBrkngAct 1 "true" 0 "false" ;
VAL_ 532 BrkFldLvlLw 1 "true" 0 "false" ;
VAL_ 890 LtRtHnTrGPCsCrStVal 0 "No Value" 1 "Left Hand Traffic" 2 "Right Hand Traffic" 3 "Automatic" 4 "Reserved1" 5 "Reserved2" 6 "Reserved3" 7 "Reserved4" ;
VAL_ 890 LtRtHnTrGPSCsStAvl 1 "true" 0 "false" ;
VAL_ 890 LtRtHnTrCstStVal 0 "No Value" 1 "Left Hand Drive" 2 "Right Hand Drive" ;
VAL_ 890 LtRtHnTrCstStAvail 0 "Not Available" 1 "Present" ;
VAL_ 328 StrngAsstRdcdIO 1 "true" 0 "false" ;
VAL_ 328 PwrStrIO 1 "true" 0 "false" ;
VAL_ 560 ElecPrkBrkSwStatV 1 "Invalid" 0 "Valid" ;
VAL_ 560 ElecPrkBrkSwStat 3 "Active" 2 "Apply" 1 "Release" 0 "NotActive" ;
VAL_ 560 AllNodesVNA 1 "Activate Virtual Network" 0 "No Activation" ;
VAL_ 560 StpOnBrkToRelPBIndOn 1 "true" 0 "false" ;
VAL_ 560 EPBC_EPBrkAutBrkRq 1 "true" 0 "false" ;
VAL_ 560 EPBSysDspMsgReq 7 "Message #7" 6 "Message #6" 5 "Message #5" 4 "Message #4" 3 "Message #3" 2 "Message #2" 1 "Message #1" 0 "Off" ;
VAL_ 560 EPBSysAudWarnReq 2 "Warning #2" 1 "Warning #1" 0 "Off" ;
VAL_ 560 ElecPrkBrkStat 2 "Fault" 1 "Applied" 0 "Released" ;
VAL_ 560 EPBCrsCanRq 1 "true" 0 "false" ;
VAL_ 560 EPBSysStatIndReq 3 "Flash Rate 2 Indication" 2 "Flash Rate 1 Indication" 1 "Continuous Indication" 0 "No Indication" ;
VAL_ 560 EPBSysWrnIndReq 3 "Flash Rate #2 Indication" 2 "Flash Rate #1 Indication" 1 "Continuous Indication" 0 "No Indication" ;
VAL_ 560 EPBSysBrkLtsReq 1 "true" 0 "false" ;
VAL_ 451 HillDscntCtrlSwStat 0 "No Activation" 1 "Increment" 2 "Decrement" 3 "Faulted" ;
VAL_ 451 GlwPlgCrnkDelAct 1 "true" 0 "false" ;
VAL_ 451 AuxHtrAlwd 1 "true" 0 "false" ;
VAL_ 451 AppCltchAutSrtIO 1 "true" 0 "false" ;
VAL_ 451 AccPosV 1 "Invalid" 0 "Valid" ;
VAL_ 451 EngTrqRdFlrSt 4 "Torq Reduction Communication Failed" 3 "Torque Reduction Limited" 2 "Torque Reduction Permanently Failed" 1 "Torque Reduction Temporarily Failed" 0 "Torque Reduction OK" ;
VAL_ 451 EngTrqDrRqdExtRngV 1 "Invalid" 0 "Valid" ;
VAL_ 451 EngTrqActExtRngV 1 "Invalid" 0 "Valid" ;
VAL_ 801 WhlBdySnsHmPosLrnd 1 "true" 0 "false" ;
VAL_ 801 WBRP_RtFrtV 1 "Invalid" 0 "Valid" ;
VAL_ 801 WBRP_RtRrV 1 "Invalid" 0 "Valid" ;
VAL_ 801 WBRP_LftRrV 1 "Invalid" 0 "Valid" ;
VAL_ 801 WBRP_LftFrtV 1 "Invalid" 0 "Valid" ;
VAL_ 320 Ky_IdDevPrgmAuthReq 1 "true" 0 "false" ;
VAL_ 320 ClmnLckStatV 1 "Invalid" 0 "Valid" ;
VAL_ 320 ClmnLckStat 2 "Locked unsuccessful" 1 "Unlocked" 0 "Locked" 3 "Unlocked unsuccessful" ;
VAL_ 320 AutoBmSlctAllwd 1 "true" 0 "false" ;
VAL_ 320 BrkLtsAtv 1 "true" 0 "false" ;
VAL_ 320 TrnSwAct 2 "Right" 1 "Left" 0 "No Activation" ;
VAL_ 320 RrFogLmpsAct 1 "true" 0 "false" ;
VAL_ 320 OtsdAmbtLtLvlStatV 1 "Invalid" 0 "Valid" ;
VAL_ 320 OtsdAmbtLtLvlStat 2 "Day" 1 "Night" 0 "Unknown" ;
VAL_ 320 MainLghtSw 3 "HEADLAMP" 2 "PARKLAMP" 1 "OFF" 0 "AUTO" ;
VAL_ 320 LowBmAct 1 "true" 0 "false" ;
VAL_ 320 HighBmAct 1 "true" 0 "false" ;
VAL_ 320 HdlmpBmSelectStat 2 "High Beams" 1 "Low Beams" 0 "Unknown" ;
VAL_ 320 FlToPsSwAtv 1 "true" 0 "false" ;
VAL_ 320 AdvFrntLghtSysEnbld 1 "true" 0 "false" ;
VAL_ 320 FrFogLmpsAct 1 "true" 0 "false" ;
VAL_ 320 AutLghtCtrl 1 "true" 0 "false" ;
VAL_ 957 RdctHtrCStat 0 "Off" 1 "On" ;
VAL_ 957 RdctHtrBStat 0 "Off" 1 "On" ;
VAL_ 957 RdctHtrAStat 0 "Off" 1 "On" ;
VAL_ 957 GPCMDS2_DTCStatus 4 "Diagnostic Failed" 3 "Diagnostic Passed" 2 "No Status to Report" 1 "Critically Disabled" 0 "Not Supported" ;
VAL_ 957 IntAirHtrPwrConsmpV 1 "Invalid" 0 "Valid" ;
VAL_ 957 DslGlwPlgMdOvTmOD 1 "true" 0 "false" ;
VAL_ 957 IQAI_InjIdInd 7 "Injector 8" 6 "Injector 7" 5 "Injector 6" 4 "Injector 5" 3 "Injector 4" 2 "Injector 3" 1 "Injector 2" 0 "Injector 1" ;
VAL_ 957 IQAI_DataStat 1 "IQA Data Byte Stored" 0 "IQA Data Byte Not Stored" ;
VAL_ 957 IntAirHtrTempSensVoltV 1 "Invalid" 0 "Valid" ;
VAL_ 957 IntAirHtrSupVoltV 1 "Invalid" 0 "Valid" ;
VAL_ 957 GPCMDS_DTCStatus 4 "Diagnostic Failed" 3 "Diagnostic Passed" 2 "No Status to Report" 1 "Critically Disabled" 0 "Not Supported" ;
VAL_ 1904 DTCI_WrnIndRqdSt_770 1 "true" 0 "false" ;
VAL_ 1904 DTCIUnused7_770 1 "true" 0 "false" ;
VAL_ 1904 DTCIUnused6_770 1 "true" 0 "false" ;
VAL_ 1904 DTCIUnused5_770 1 "true" 0 "false" ;
VAL_ 1904 DTCIUnused4_770 1 "true" 0 "false" ;
VAL_ 1904 DTCIUnused3_770 1 "true" 0 "false" ;
VAL_ 1904 DTCIUnused2_770 1 "true" 0 "false" ;
VAL_ 1904 DTCIUnused1_770 1 "true" 0 "false" ;
VAL_ 1904 DTCI_TstNPsdPwrUpSt_770 1 "true" 0 "false" ;
VAL_ 1904 DTCI_TstNPsdCdClrdSt_770 1 "true" 0 "false" ;
VAL_ 1904 DTCI_TstFldPwrUpSt_770 1 "true" 0 "false" ;
VAL_ 1904 DTCI_TstFldCdClrdStat_770 1 "true" 0 "false" ;
VAL_ 1904 DTCI_HistStat_770 1 "true" 0 "false" ;
VAL_ 1904 DTCI_DTCTriggered_770 1 "true" 0 "false" ;
VAL_ 1904 DTCI_DTCFaultType_770 3 "Type C" 2 "Type B" 1 "Type A" 0 "Not Supported" ;
VAL_ 1904 DTCI_CurrentStatus_770 1 "true" 0 "false" ;
VAL_ 1904 DTCI_CodeSupported_770 1 "true" 0 "false" ;
VAL_ 1908 DTCI_DTCFaultType_774 3 "Type C" 2 "Type B" 1 "Type A" 0 "Not Supported" ;
VAL_ 1908 DTCI_CodeSupported_774 1 "true" 0 "false" ;
VAL_ 1908 DTCI_CurrentStatus_774 1 "true" 0 "false" ;
VAL_ 1908 DTCI_TstNPsdCdClrdSt_774 1 "true" 0 "false" ;
VAL_ 1908 DTCI_TstFldCdClrdStat_774 1 "true" 0 "false" ;
VAL_ 1908 DTCI_HistStat_774 1 "true" 0 "false" ;
VAL_ 1908 DTCI_TstNPsdPwrUpSt_774 1 "true" 0 "false" ;
VAL_ 1908 DTCI_TstFldPwrUpSt_774 1 "true" 0 "false" ;
VAL_ 1908 DTCI_WrnIndRqdSt_774 1 "true" 0 "false" ;
VAL_ 1908 DTCI_DTCTriggered_774 1 "true" 0 "false" ;
VAL_ 1908 DTCIUnused7_774 1 "true" 0 "false" ;
VAL_ 1908 DTCIUnused6_774 1 "true" 0 "false" ;
VAL_ 1908 DTCIUnused5_774 1 "true" 0 "false" ;
VAL_ 1908 DTCIUnused4_774 1 "true" 0 "false" ;
VAL_ 1908 DTCIUnused3_774 1 "true" 0 "false" ;
VAL_ 1908 DTCIUnused2_774 1 "true" 0 "false" ;
VAL_ 1908 DTCIUnused1_774 1 "true" 0 "false" ;
VAL_ 1909 DTCI_DTCFaultType_775 3 "Type C" 2 "Type B" 1 "Type A" 0 "Not Supported" ;
VAL_ 1909 DTCI_CodeSupported_775 1 "true" 0 "false" ;
VAL_ 1909 DTCI_CurrentStatus_775 1 "true" 0 "false" ;
VAL_ 1909 DTCI_TstNPsdCdClrdSt_775 1 "true" 0 "false" ;
VAL_ 1909 DTCI_TstFldCdClrdStat_775 1 "true" 0 "false" ;
VAL_ 1909 DTCI_HistStat_775 1 "true" 0 "false" ;
VAL_ 1909 DTCI_TstNPsdPwrUpSt_775 1 "true" 0 "false" ;
VAL_ 1909 DTCI_TstFldPwrUpSt_775 1 "true" 0 "false" ;
VAL_ 1909 DTCI_WrnIndRqdSt_775 1 "true" 0 "false" ;
VAL_ 1909 DTCI_DTCTriggered_775 1 "true" 0 "false" ;
VAL_ 1909 DTCIUnused7_775 1 "true" 0 "false" ;
VAL_ 1909 DTCIUnused6_775 1 "true" 0 "false" ;
VAL_ 1909 DTCIUnused5_775 1 "true" 0 "false" ;
VAL_ 1909 DTCIUnused4_775 1 "true" 0 "false" ;
VAL_ 1909 DTCIUnused3_775 1 "true" 0 "false" ;
VAL_ 1909 DTCIUnused2_775 1 "true" 0 "false" ;
VAL_ 1909 DTCIUnused1_775 1 "true" 0 "false" ;
SIG_GROUP_ 190 PTSnsdBrkPdlInf 1 : PSBPI_PTSnBrkPdlPsV PSBPI_PTSnBrkPdlPs;
SIG_GROUP_ 1922 DTCInfo_782 1 : DTCI_WrnIndRqdSt_782 DTCIUnused7_782 DTCIUnused6_782 DTCIUnused5_782 DTCIUnused4_782 DTCIUnused3_782 DTCIUnused2_782 DTCIUnused1_782 DTCI_TstNPsdPwrUpSt_782 DTCI_TstNPsdCdClrdSt_782 DTCI_TstFldPwrUpSt_782 DTCI_TstFldCdClrdStat_782 DTCI_HistStat_782 DTCI_DTCTriggered_782 DTCI_DTCSource_782 DTCI_DTCNumber_782 DTCI_DTCFaultType_782 DTCI_DTCFailType_782 DTCI_CurrentStatus_782 DTCI_CodeSupported_782;
SIG_GROUP_ 386 PerfMdVislztnScrnStat 1 : PMVSS_Disps PMVSS_Exhst PMVSS_PsngrSeat PMVSS_DrvrSeat PMVSS_AdptCrsCnt PMVSS_Drvln PMVSS_Susp PMVSS_Strng PMVSS_Trans PMVSS_Eng PMVSS_Snd;
SIG_GROUP_ 532 BrkPdDrvAppPrsStat 1 : BPDAPS_BkPDrvApPV BPDAPS_BkPDrvApP;
SIG_GROUP_ 560 ElecPrkBrkCmd 1 : EPBC_EPBAccRq EPBC_EPBrkAutBrkRq;
SIG_GROUP_ 801 WhlBdyRelPos 1 : WBRP_ARC WBRP_Tmestmp WBRP_RtFrtV WBRP_RtFrt WBRP_RtRrV WBRP_RtRr WBRP_LftRrV WBRP_LftRr WBRP_LftFrtV WBRP_LftFrt;
SIG_GROUP_ 957 GlwPlgCntlModDiagSt2 1 : GPCMDS2_DTCStatus GPCMDS2_DTCIndex;
SIG_GROUP_ 957 InjQualAdjInfo 1 : IQAI_DataByte IQAI_DataSeqNmbr IQAI_InjIdInd IQAI_DataStat;
SIG_GROUP_ 957 GlwPlgCntlModDiagSt 1 : GPCMDS_DTCStatus GPCMDS_DTCIndex;
SIG_GROUP_ 1904 DTCInfo_770 1 : DTCI_WrnIndRqdSt_770 DTCIUnused7_770 DTCIUnused6_770 DTCIUnused5_770 DTCIUnused4_770 DTCIUnused3_770 DTCIUnused2_770 DTCIUnused1_770 DTCI_TstNPsdPwrUpSt_770 DTCI_TstNPsdCdClrdSt_770 DTCI_TstFldPwrUpSt_770 DTCI_TstFldCdClrdStat_770 DTCI_HistStat_770 DTCI_DTCTriggered_770 DTCI_DTCSource_770 DTCI_DTCNumber_770 DTCI_DTCFaultType_770 DTCI_DTCFailType_770 DTCI_CurrentStatus_770 DTCI_CodeSupported_770;
SIG_GROUP_ 1908 DTCInfo_774 1 : DTCI_DTCFaultType_774 DTCI_CodeSupported_774 DTCI_CurrentStatus_774 DTCI_TstNPsdCdClrdSt_774 DTCI_TstFldCdClrdStat_774 DTCI_HistStat_774 DTCI_TstNPsdPwrUpSt_774 DTCI_TstFldPwrUpSt_774 DTCI_WrnIndRqdSt_774 DTCI_DTCFailType_774 DTCI_DTCNumber_774 DTCI_DTCSource_774 DTCI_DTCTriggered_774 DTCIUnused7_774 DTCIUnused6_774 DTCIUnused5_774 DTCIUnused4_774 DTCIUnused3_774 DTCIUnused2_774 DTCIUnused1_774;
SIG_GROUP_ 1909 DTCInfo_775 1 : DTCI_DTCFaultType_775 DTCI_CodeSupported_775 DTCI_CurrentStatus_775 DTCI_TstNPsdCdClrdSt_775 DTCI_TstFldCdClrdStat_775 DTCI_HistStat_775 DTCI_TstNPsdPwrUpSt_775 DTCI_TstFldPwrUpSt_775 DTCI_WrnIndRqdSt_775 DTCI_DTCFailType_775 DTCI_DTCNumber_775 DTCI_DTCSource_775 DTCI_DTCTriggered_775 DTCIUnused7_775 DTCIUnused6_775 DTCIUnused5_775 DTCIUnused4_775 DTCIUnused3_775 DTCIUnused2_775 DTCIUnused1_775;
